VERSION ""

NS_ :

BS_:

BU_:

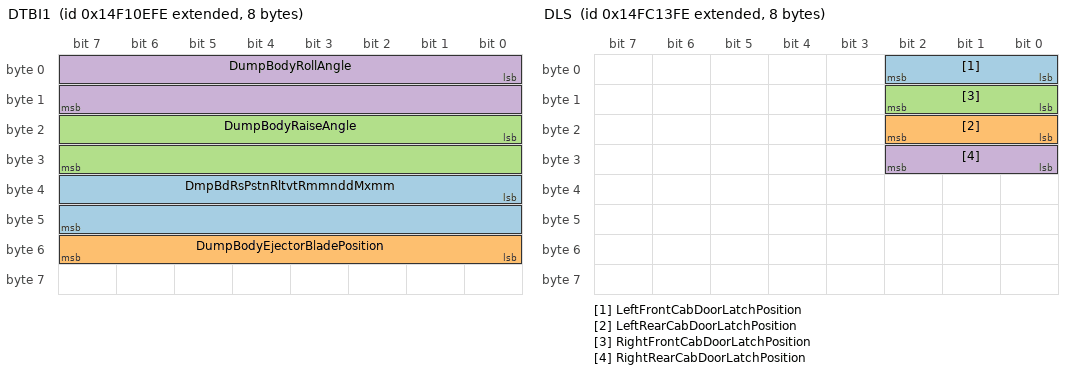
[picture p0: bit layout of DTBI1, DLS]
BO_ 2498825982 DTBI1: 8 Vector__XXX
 SG_ DmpBdRsPstnRltvtRmmnddMxmm : 32|16@1+ (0.005,-150) [-150|171.275] "%" Vector__XXX
 SG_ DumpBodyEjectorBladePosition : 48|8@1+ (0.4,0) [0|100] "%" Vector__XXX
 SG_ DumpBodyRaiseAngle : 16|16@1+ (0.0078125,-200) [-200|301.99] "deg" Vector__XXX
 SG_ DumpBodyRollAngle : 0|16@1+ (0.0078125,-200) [-200|301.99] "deg" Vector__XXX

BO_ 2499547902 CDC1: 8 Vector__XXX
 SG_ CabDoorsLockActuationCommand : 0|3@1+ (1,0) [0|7] "" Vector__XXX
 SG_ LeftFrontWindowPositionCommand : 16|3@1+ (1,0) [0|7] "" Vector__XXX
 SG_ LeftRearWindowPositionCommand : 24|3@1+ (1,0) [0|7] "" Vector__XXX
 SG_ MirrorLeft1HeatCommand : 48|2@1+ (1,0) [0|3] "" Vector__XXX
 SG_ MirrorLeft1HorizontalCommand : 32|2@1+ (1,0) [0|3] "" Vector__XXX
 SG_ MirrorLeft1VerticalCommand : 34|2@1+ (1,0) [0|3] "" Vector__XXX
 SG_ MirrorLeft2HeatCommand : 52|2@1+ (1,0) [0|3] "" Vector__XXX
 SG_ MirrorLeft2HorizontalCommand : 40|2@1+ (1,0) [0|3] "" Vector__XXX
 SG_ MirrorLeft2VerticalCommand : 42|2@1+ (1,0) [0|3] "" Vector__XXX
 SG_ MirrorRight1HeatCommand : 50|2@1+ (1,0) [0|3] "" Vector__XXX
 SG_ MirrorRight1HorizontalCommand : 36|2@1+ (1,0) [0|3] "" Vector__XXX
 SG_ MirrorRight1VerticalCommand : 38|2@1+ (1,0) [0|3] "" Vector__XXX
 SG_ MirrorRight2HeatCommand : 54|2@1+ (1,0) [0|3] "" Vector__XXX
 SG_ MirrorRight2HorizontalCommand : 44|2@1+ (1,0) [0|3] "" Vector__XXX
 SG_ MirrorRight2VerticalCommand : 46|2@1+ (1,0) [0|3] "" Vector__XXX
 SG_ RemoteCabDoorLockRequest : 8|3@1+ (1,0) [0|7] "" Vector__XXX
 SG_ RightFrontWindowPositionCommand : 19|3@1+ (1,0) [0|7] "" Vector__XXX
 SG_ RightRearWindowPositionCommand : 27|3@1+ (1,0) [0|7] "" Vector__XXX
 SG_ MirrorFoldingSwitch : 22|2@1+ (1,0) [0|3] "" Vector__XXX
 SG_ MirrorAutoPanningEnable : 30|2@1+ (1,0) [0|3] "" Vector__XXX

BO_ 2499548158 DLS: 8 Vector__XXX
 SG_ LeftFrontCabDoorLatchPosition : 0|3@1+ (1,0) [0|7] "" Vector__XXX
 SG_ LeftRearCabDoorLatchPosition : 16|3@1+ (1,0) [0|7] "" Vector__XXX
 SG_ RightFrontCabDoorLatchPosition : 8|3@1+ (1,0) [0|7] "" Vector__XXX
 SG_ RightRearCabDoorLatchPosition : 24|3@1+ (1,0) [0|7] "" Vector__XXX

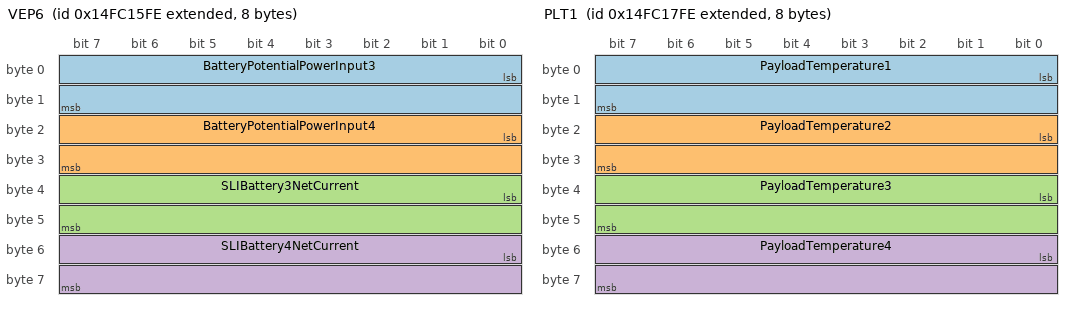
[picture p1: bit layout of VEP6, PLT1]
BO_ 2499548670 VEP6: 8 Vector__XXX
 SG_ BatteryPotentialPowerInput3 : 0|16@1+ (0.05,0) [0|3212.75] "V" Vector__XXX
 SG_ BatteryPotentialPowerInput4 : 16|16@1+ (0.05,0) [0|3212.75] "V" Vector__XXX
 SG_ SLIBattery3NetCurrent : 32|16@1+ (0.05,-1600) [-1600|1612.75] "A" Vector__XXX
 SG_ SLIBattery4NetCurrent : 48|16@1+ (0.05,-1600) [-1600|1612.75] "A" Vector__XXX

BO_ 2499548926 PLT2: 8 Vector__XXX
 SG_ PayloadTemperature5 : 0|16@1+ (0.03125,-273) [-273|1734.96875] "degC" Vector__XXX

BO_ 2499549182 PLT1: 8 Vector__XXX
 SG_ PayloadTemperature1 : 0|16@1+ (0.03125,-273) [-273|1734.96875] "degC" Vector__XXX
 SG_ PayloadTemperature2 : 16|16@1+ (0.03125,-273) [-273|1734.96875] "degC" Vector__XXX
 SG_ PayloadTemperature3 : 32|16@1+ (0.03125,-273) [-273|1734.96875] "degC" Vector__XXX
 SG_ PayloadTemperature4 : 48|16@1+ (0.03125,-273) [-273|1734.96875] "degC" Vector__XXX

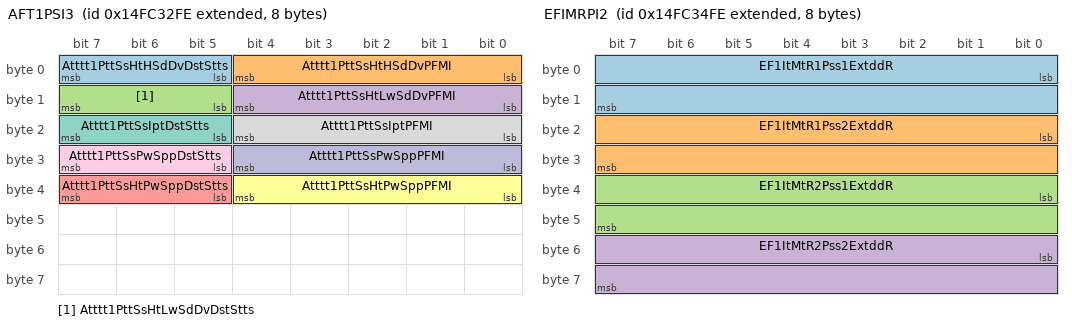
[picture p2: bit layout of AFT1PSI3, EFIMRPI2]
BO_ 2499556094 AFT1PSI3: 8 Vector__XXX
 SG_ Atttt1PttSsHtHSdDvDstStts : 5|3@1+ (1,0) [0|7] "" Vector__XXX
 SG_ Atttt1PttSsHtHSdDvPFMI : 0|5@1+ (1,0) [0|31] "" Vector__XXX
 SG_ Atttt1PttSsHtLwSdDvDstStts : 13|3@1+ (1,0) [0|7] "" Vector__XXX
 SG_ Atttt1PttSsHtLwSdDvPFMI : 8|5@1+ (1,0) [0|31] "" Vector__XXX
 SG_ Atttt1PttSsHtPwSppDstStts : 37|3@1+ (1,0) [0|7] "" Vector__XXX
 SG_ Atttt1PttSsHtPwSppPFMI : 32|5@1+ (1,0) [0|31] "" Vector__XXX
 SG_ Atttt1PttSsIptDstStts : 21|3@1+ (1,0) [0|7] "" Vector__XXX
 SG_ Atttt1PttSsIptPFMI : 16|5@1+ (1,0) [0|31] "" Vector__XXX
 SG_ Atttt1PttSsPwSppDstStts : 29|3@1+ (1,0) [0|7] "" Vector__XXX
 SG_ Atttt1PttSsPwSppPFMI : 24|5@1+ (1,0) [0|31] "" Vector__XXX

BO_ 2499556350 EFIMRPI3: 8 Vector__XXX
 SG_ EngnFl1InjtrMtrngRl1DsrdPrssr : 0|16@1+ (5,0) [0|321275] "kPa" Vector__XXX
 SG_ EngnFl1InjtrMtrngRl2DsrdPrssr : 16|16@1+ (5,0) [0|321275] "kPa" Vector__XXX

BO_ 2499556606 EFIMRPI2: 8 Vector__XXX
 SG_ EF1ItMtR1Pss1ExtddR : 0|16@1+ (5,0) [0|321275] "kPa" Vector__XXX
 SG_ EF1ItMtR1Pss2ExtddR : 16|16@1+ (5,0) [0|321275] "kPa" Vector__XXX
 SG_ EF1ItMtR2Pss1ExtddR : 32|16@1+ (5,0) [0|321275] "kPa" Vector__XXX
 SG_ EF1ItMtR2Pss2ExtddR : 48|16@1+ (5,0) [0|321275] "kPa" Vector__XXX

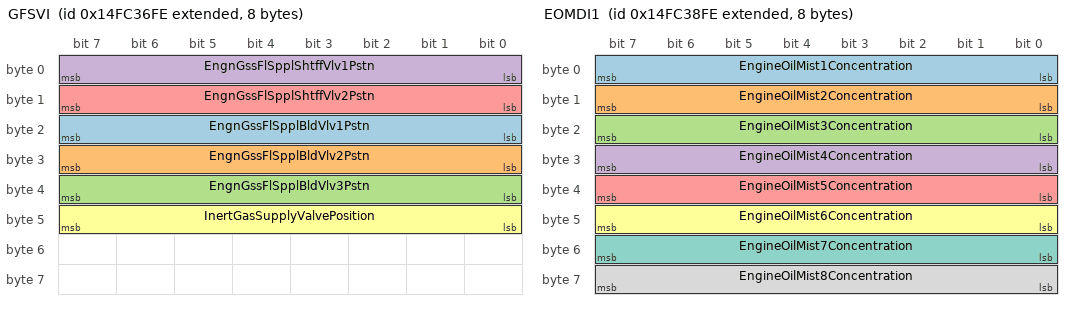
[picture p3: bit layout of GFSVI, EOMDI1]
BO_ 2499557118 GFSVI: 8 Vector__XXX
 SG_ EngnGssFlSpplBldVlv1Pstn : 16|8@1+ (0.4,0) [0|100] "%" Vector__XXX
 SG_ EngnGssFlSpplBldVlv2Pstn : 24|8@1+ (0.4,0) [0|100] "%" Vector__XXX
 SG_ EngnGssFlSpplBldVlv3Pstn : 32|8@1+ (0.4,0) [0|100] "%" Vector__XXX
 SG_ EngnGssFlSpplShtffVlv1Pstn : 0|8@1+ (0.4,0) [0|100] "%" Vector__XXX
 SG_ EngnGssFlSpplShtffVlv2Pstn : 8|8@1+ (0.4,0) [0|100] "%" Vector__XXX
 SG_ InertGasSupplyValvePosition : 40|8@1+ (0.4,0) [0|100] "%" Vector__XXX

BO_ 2499557374 EOMDI2: 8 Vector__XXX
 SG_ EngineOilMist10Concentration : 8|8@1+ (1,0) [0|250] "%" Vector__XXX
 SG_ EngineOilMist9Concentration : 0|8@1+ (1,0) [0|250] "%" Vector__XXX

BO_ 2499557630 EOMDI1: 8 Vector__XXX
 SG_ EngineOilMist1Concentration : 0|8@1+ (1,0) [0|250] "%" Vector__XXX
 SG_ EngineOilMist2Concentration : 8|8@1+ (1,0) [0|250] "%" Vector__XXX
 SG_ EngineOilMist3Concentration : 16|8@1+ (1,0) [0|250] "%" Vector__XXX
 SG_ EngineOilMist4Concentration : 24|8@1+ (1,0) [0|250] "%" Vector__XXX
 SG_ EngineOilMist5Concentration : 32|8@1+ (1,0) [0|250] "%" Vector__XXX
 SG_ EngineOilMist6Concentration : 40|8@1+ (1,0) [0|250] "%" Vector__XXX
 SG_ EngineOilMist7Concentration : 48|8@1+ (1,0) [0|250] "%" Vector__XXX
 SG_ EngineOilMist8Concentration : 56|8@1+ (1,0) [0|250] "%" Vector__XXX

BO_ 2499557886 GFSP2: 8 Vector__XXX
 SG_ PlntGssFlSpplOtltPrssr : 0|16@1+ (0.5,0) [0|32127.5] "kPa" Vector__XXX
 SG_ PlntInrtGsSpplOtltPrssr : 16|16@1+ (0.5,0) [0|32127.5] "kPa" Vector__XXX

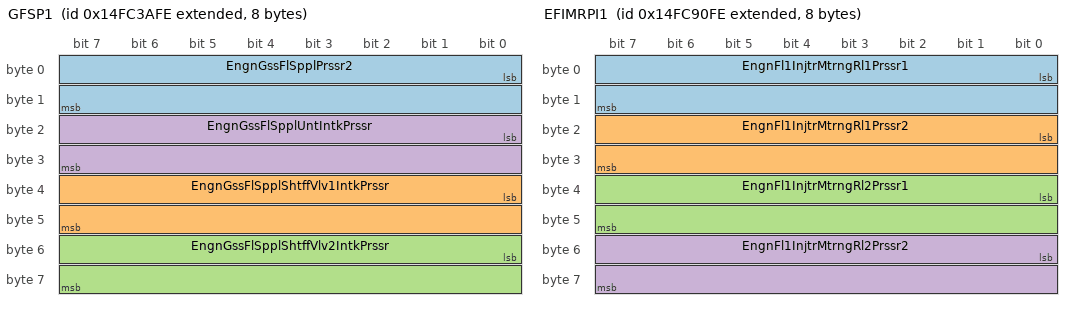
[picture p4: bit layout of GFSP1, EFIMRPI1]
BO_ 2499558142 GFSP1: 8 Vector__XXX
 SG_ EngnGssFlSpplPrssr2 : 0|16@1+ (0.5,0) [0|32127.5] "kPa" Vector__XXX
 SG_ EngnGssFlSpplShtffVlv1IntkPrssr : 32|16@1+ (0.5,0) [0|32127.5] "kPa" Vector__XXX
 SG_ EngnGssFlSpplShtffVlv2IntkPrssr : 48|16@1+ (0.5,0) [0|32127.5] "kPa" Vector__XXX
 SG_ EngnGssFlSpplUntIntkPrssr : 16|16@1+ (0.5,0) [0|32127.5] "kPa" Vector__XXX

BO_ 2499580158 EFIMRPI1: 8 Vector__XXX
 SG_ EngnFl1InjtrMtrngRl1Prssr1 : 0|16@1+ (0.00390625,0) [0|250.996] "MPa" Vector__XXX
 SG_ EngnFl1InjtrMtrngRl1Prssr2 : 16|16@1+ (0.00390625,0) [0|250.996] "MPa" Vector__XXX
 SG_ EngnFl1InjtrMtrngRl2Prssr1 : 32|16@1+ (0.00390625,0) [0|250.996] "MPa" Vector__XXX
 SG_ EngnFl1InjtrMtrngRl2Prssr2 : 48|16@1+ (0.00390625,0) [0|250.996] "MPa" Vector__XXX

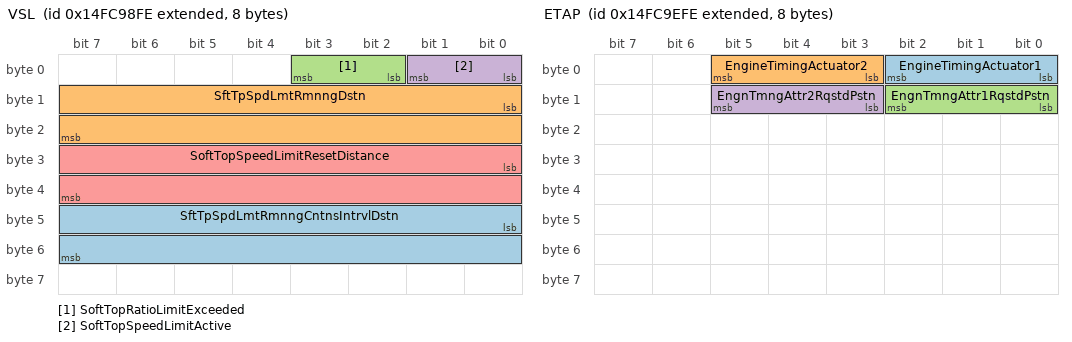
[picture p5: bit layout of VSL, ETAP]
BO_ 2499582206 VSL: 8 Vector__XXX
 SG_ SftTpSpdLmtRmnngCntnsIntrvlDstn : 40|16@1+ (1,0) [0|64255] "km" Vector__XXX
 SG_ SftTpSpdLmtRmnngDstn : 8|16@1+ (1,0) [0|64255] "km" Vector__XXX
 SG_ SoftTopRatioLimitExceeded : 2|2@1+ (1,0) [0|3] "" Vector__XXX
 SG_ SoftTopSpeedLimitActive : 0|2@1+ (1,0) [0|3] "" Vector__XXX
 SG_ SoftTopSpeedLimitResetDistance : 24|16@1+ (1,0) [0|64255] "km" Vector__XXX

BO_ 2499583486 ETAPC: 8 Vector__XXX
 SG_ EngnTmngAttr1PstnCmmnd : 0|3@1+ (1,0) [0|7] "" Vector__XXX
 SG_ EngnTmngAttr2PstnCmmnd : 3|3@1+ (1,0) [0|7] "" Vector__XXX

BO_ 2499583742 ETAP: 8 Vector__XXX
 SG_ EngineTimingActuator1 : 0|3@1+ (1,0) [0|7] "" Vector__XXX
 SG_ EngineTimingActuator2 : 3|3@1+ (1,0) [0|7] "" Vector__XXX
 SG_ EngnTmngAttr1RqstdPstn : 8|3@1+ (1,0) [0|7] "" Vector__XXX
 SG_ EngnTmngAttr2RqstdPstn : 11|3@1+ (1,0) [0|7] "" Vector__XXX

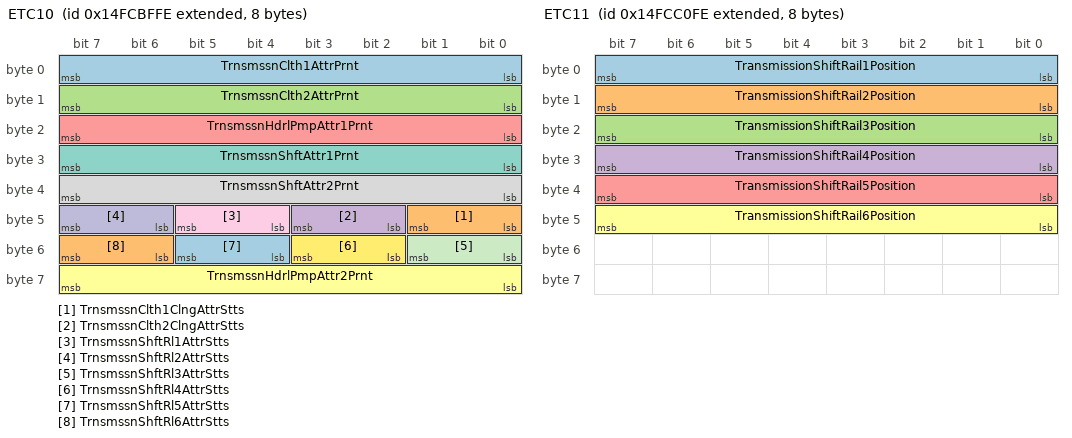
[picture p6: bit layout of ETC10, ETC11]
BO_ 2499592190 ETC10: 8 Vector__XXX
 SG_ TrnsmssnClth1AttrPrnt : 0|8@1+ (0.4,0) [0|100] "%" Vector__XXX
 SG_ TrnsmssnClth1ClngAttrStts : 40|2@1+ (1,0) [0|3] "" Vector__XXX
 SG_ TrnsmssnClth2AttrPrnt : 8|8@1+ (0.4,0) [0|100] "%" Vector__XXX
 SG_ TrnsmssnClth2ClngAttrStts : 42|2@1+ (1,0) [0|3] "" Vector__XXX
 SG_ TrnsmssnHdrlPmpAttr1Prnt : 16|8@1+ (0.4,0) [0|100] "%" Vector__XXX
 SG_ TrnsmssnHdrlPmpAttr2Prnt : 56|8@1+ (0.4,0) [0|100] "%" Vector__XXX
 SG_ TrnsmssnShftAttr1Prnt : 24|8@1+ (0.4,0) [0|100] "%" Vector__XXX
 SG_ TrnsmssnShftAttr2Prnt : 32|8@1+ (0.4,0) [0|100] "%" Vector__XXX
 SG_ TrnsmssnShftRl1AttrStts : 44|2@1+ (1,0) [0|3] "" Vector__XXX
 SG_ TrnsmssnShftRl2AttrStts : 46|2@1+ (1,0) [0|3] "" Vector__XXX
 SG_ TrnsmssnShftRl3AttrStts : 48|2@1+ (1,0) [0|3] "" Vector__XXX
 SG_ TrnsmssnShftRl4AttrStts : 50|2@1+ (1,0) [0|3] "" Vector__XXX
 SG_ TrnsmssnShftRl5AttrStts : 52|2@1+ (1,0) [0|3] "" Vector__XXX
 SG_ TrnsmssnShftRl6AttrStts : 54|2@1+ (1,0) [0|3] "" Vector__XXX

BO_ 2499592446 ETC11: 8 Vector__XXX
 SG_ TransmissionShiftRail1Position : 0|8@1+ (0.4,0) [0|100] "%" Vector__XXX
 SG_ TransmissionShiftRail2Position : 8|8@1+ (0.4,0) [0|100] "%" Vector__XXX
 SG_ TransmissionShiftRail3Position : 16|8@1+ (0.4,0) [0|100] "%" Vector__XXX
 SG_ TransmissionShiftRail4Position : 24|8@1+ (0.4,0) [0|100] "%" Vector__XXX
 SG_ TransmissionShiftRail5Position : 32|8@1+ (0.4,0) [0|100] "%" Vector__XXX
 SG_ TransmissionShiftRail6Position : 40|8@1+ (0.4,0) [0|100] "%" Vector__XXX

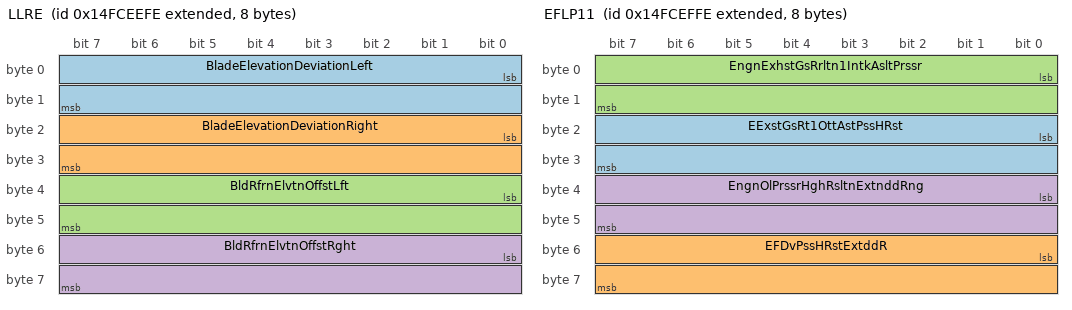
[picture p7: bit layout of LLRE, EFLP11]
BO_ 2499604222 LLRE: 8 Vector__XXX
 SG_ BladeElevationDeviationLeft : 0|16@1+ (1,-32000) [-32000|32255] "mm" Vector__XXX
 SG_ BladeElevationDeviationRight : 16|16@1+ (1,-32000) [-32000|32255] "mm" Vector__XXX
 SG_ BldRfrnElvtnOffstLft : 32|16@1+ (1,-32000) [-32000|32255] "mm" Vector__XXX
 SG_ BldRfrnElvtnOffstRght : 48|16@1+ (1,-32000) [-32000|32255] "mm" Vector__XXX

BO_ 2499604478 EFLP11: 8 Vector__XXX
 SG_ EExstGsRt1OttAstPssHRst : 16|16@1+ (0.1,0) [0|6425.5] "kPa" Vector__XXX
 SG_ EFDvPssHRstExtddR : 48|16@1+ (0.1,0) [0|6425.5] "kPa" Vector__XXX
 SG_ EngnExhstGsRrltn1IntkAsltPrssr : 0|16@1+ (0.1,0) [0|6425.5] "kPa" Vector__XXX
 SG_ EngnOlPrssrHghRsltnExtnddRng : 32|16@1+ (0.1,0) [0|6425.5] "kPa" Vector__XXX

BO_ 2499607550 EMAP: 8 Vector__XXX
 SG_ EExstMdB1FwBVvAttPst : 0|16@1+ (0.0025,0) [0|160.6375] "%" Vector__XXX
 SG_ EExstMdB2FwBVvAttPst : 16|16@1+ (0.0025,0) [0|160.6375] "%" Vector__XXX

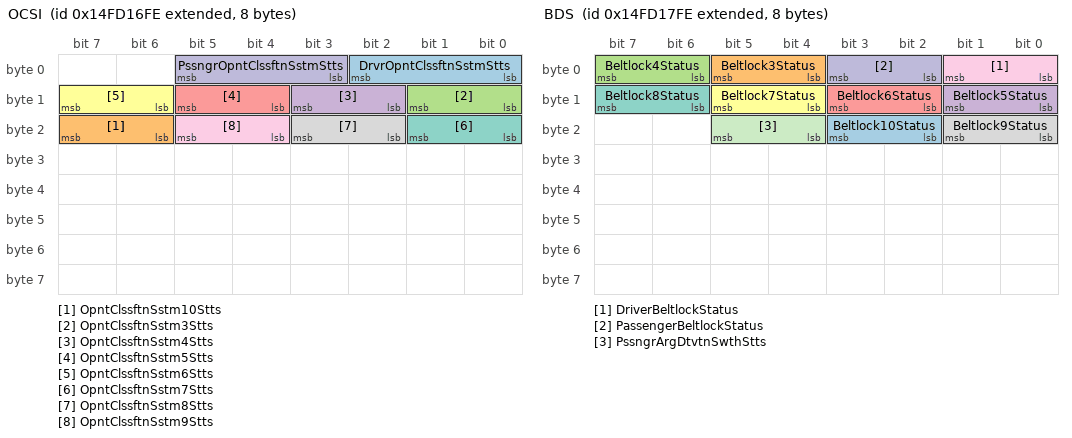
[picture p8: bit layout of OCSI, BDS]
BO_ 2499614462 OCSI: 8 Vector__XXX
 SG_ DrvrOpntClssftnSstmStts : 0|3@1+ (1,0) [0|7] "" Vector__XXX
 SG_ OpntClssftnSstm10Stts : 22|2@1+ (1,0) [0|3] "" Vector__XXX
 SG_ OpntClssftnSstm3Stts : 8|2@1+ (1,0) [0|3] "" Vector__XXX
 SG_ OpntClssftnSstm4Stts : 10|2@1+ (1,0) [0|3] "" Vector__XXX
 SG_ OpntClssftnSstm5Stts : 12|2@1+ (1,0) [0|3] "" Vector__XXX
 SG_ OpntClssftnSstm6Stts : 14|2@1+ (1,0) [0|3] "" Vector__XXX
 SG_ OpntClssftnSstm7Stts : 16|2@1+ (1,0) [0|3] "" Vector__XXX
 SG_ OpntClssftnSstm8Stts : 18|2@1+ (1,0) [0|3] "" Vector__XXX
 SG_ OpntClssftnSstm9Stts : 20|2@1+ (1,0) [0|3] "" Vector__XXX
 SG_ PssngrOpntClssftnSstmStts : 3|3@1+ (1,0) [0|7] "" Vector__XXX

BO_ 2499614718 BDS: 8 Vector__XXX
 SG_ Beltlock10Status : 18|2@1+ (1,0) [0|3] "" Vector__XXX
 SG_ Beltlock3Status : 4|2@1+ (1,0) [0|3] "" Vector__XXX
 SG_ Beltlock4Status : 6|2@1+ (1,0) [0|3] "" Vector__XXX
 SG_ Beltlock5Status : 8|2@1+ (1,0) [0|3] "" Vector__XXX
 SG_ Beltlock6Status : 10|2@1+ (1,0) [0|3] "" Vector__XXX
 SG_ Beltlock7Status : 12|2@1+ (1,0) [0|3] "" Vector__XXX
 SG_ Beltlock8Status : 14|2@1+ (1,0) [0|3] "" Vector__XXX
 SG_ Beltlock9Status : 16|2@1+ (1,0) [0|3] "" Vector__XXX
 SG_ DriverBeltlockStatus : 0|2@1+ (1,0) [0|3] "" Vector__XXX
 SG_ PassengerBeltlockStatus : 2|2@1+ (1,0) [0|3] "" Vector__XXX
 SG_ PssngrArgDtvtnSwthStts : 20|2@1+ (1,0) [0|3] "" Vector__XXX

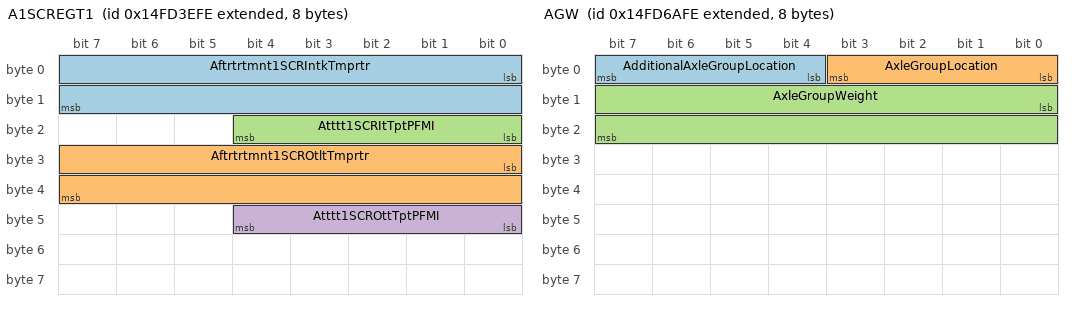
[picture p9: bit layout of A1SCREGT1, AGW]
BO_ 2499624702 A1SCREGT1: 8 Vector__XXX
 SG_ Aftrtrtmnt1SCRIntkTmprtr : 0|16@1+ (0.03125,-273) [-273|1734.96875] "degC" Vector__XXX
 SG_ Aftrtrtmnt1SCROtltTmprtr : 24|16@1+ (0.03125,-273) [-273|1734.96875] "degC" Vector__XXX
 SG_ Atttt1SCRItTptPFMI : 16|5@1+ (1,0) [0|31] "" Vector__XXX
 SG_ Atttt1SCROttTptPFMI : 40|5@1+ (1,0) [0|31] "" Vector__XXX

BO_ 2499630078 EAI: 8 Vector__XXX
 SG_ EngineExhaustTemperatureAverage : 0|16@1+ (0.03125,-273) [-273|1734.96875] "degC" Vector__XXX
 SG_ EngnExhstBnk1TmprtrAvrg : 16|16@1+ (0.03125,-273) [-273|1734.96875] "degC" Vector__XXX
 SG_ EngnExhstBnk2TmprtrAvrg : 32|16@1+ (0.03125,-273) [-273|1734.96875] "degC" Vector__XXX

BO_ 2499635454 GCVW: 8 Vector__XXX
 SG_ GrossCombinationWeight : 0|24@1+ (2,0) [0|32899070] "kg" Vector__XXX
 SG_ NetVehicleWeightChange : 24|24@1+ (2,-16449535) [-16449535|16449535] "kg" Vector__XXX

BO_ 2499635966 AGW: 8 Vector__XXX
 SG_ AdditionalAxleGroupLocation : 4|4@1+ (1,0) [0|15] "" Vector__XXX
 SG_ AxleGroupLocation : 0|4@1+ (1,0) [0|15] "" Vector__XXX
 SG_ AxleGroupWeight : 8|16@1+ (2,0) [0|128510] "kg" Vector__XXX

BO_ 2499641854 EGRBV: 8 Vector__XXX
 SG_ EExstGsRt1CBpssAttPst : 0|8@1+ (0.4,0) [0|100] "%" Vector__XXX

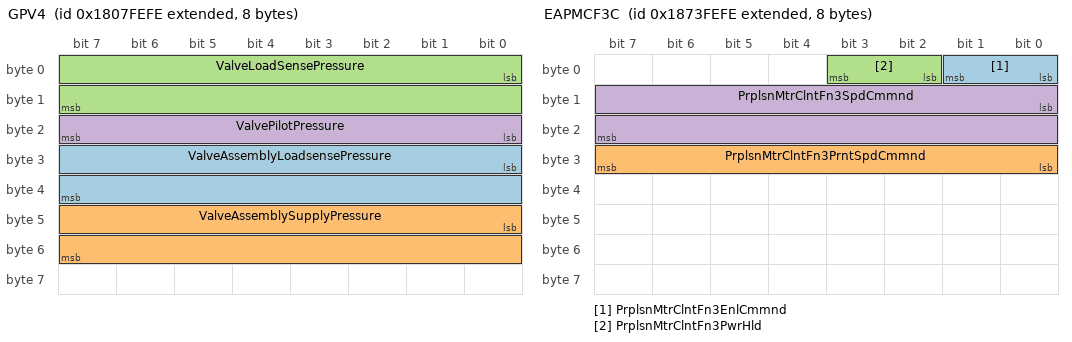
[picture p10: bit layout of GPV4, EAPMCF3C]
BO_ 2550660862 GPV4: 8 Vector__XXX
 SG_ ValveAssemblyLoadsensePressure : 24|16@1+ (5,0) [0|321275] "kPa" Vector__XXX
 SG_ ValveAssemblySupplyPressure : 40|16@1+ (5,0) [0|321275] "kPa" Vector__XXX
 SG_ ValveLoadSensePressure : 0|16@1+ (5,0) [0|321275] "kPa" Vector__XXX
 SG_ ValvePilotPressure : 16|8@1+ (16,0) [0|4000] "kPa" Vector__XXX

BO_ 2550988542 EEC16: 8 Vector__XXX
 SG_ EngineClutchEngageRequestStatus : 10|2@1+ (1,0) [0|3] "" Vector__XXX
 SG_ ReadyForClutchEngagementStatus : 8|2@1+ (1,0) [0|3] "" Vector__XXX
 SG_ AcceleratorPedal3Position : 0|8@1+ (0.4,0) [0|100] "%" Vector__XXX

BO_ 2557214462 WSPSCC: 8 Vector__XXX
 SG_ WSttPpDsPssCtStPtCd : 8|4@1+ (1,0) [0|15] "" Vector__XXX
 SG_ WSttPpStPssCtStPtCd : 0|4@1+ (1,0) [0|15] "" Vector__XXX

BO_ 2557345534 WSPT1: 19 Vector__XXX
 SG_ WllStmltnPmpPlngrFrngOrdr : 144|4@1+ (1,0) [0|15] "" Vector__XXX
 SG_ WllStmltnPmpRdLdHghThrshld : 128|16@1+ (5,0) [0|321275] "kN" Vector__XXX
 SG_ WllStmltnPmpStnPrssrHghThrshld : 64|16@1+ (0.1,-3212.7) [-3212.7|3212.8] "kPa" Vector__XXX
 SG_ WllStmltnPmpStnPrssrLwThrshld : 48|16@1+ (0.1,-3212.7) [-3212.7|3212.8] "kPa" Vector__XXX
 SG_ WSttPpCstSpdHTsd : 112|16@1+ (0.125,0) [0|8031.875] "rpm" Vector__XXX
 SG_ WSttPpCstSpdLwTsd : 96|16@1+ (0.125,0) [0|8031.875] "rpm" Vector__XXX
 SG_ WSttPpDsPssHTsd : 80|16@1+ (5,0) [0|321275] "kPa" Vector__XXX
 SG_ WSttPpGBxOPssHTsd : 16|16@1+ (0.1,0) [0|6425.5] "kPa" Vector__XXX
 SG_ WSttPpGBxOPssLwTsd : 0|16@1+ (0.1,0) [0|6425.5] "kPa" Vector__XXX
 SG_ WSttPpGBxOTptHTsd : 40|8@1+ (1,-40) [-40|210] "degC" Vector__XXX
 SG_ WSttPpGBxOTptLwTsd : 32|8@1+ (1,-40) [-40|210] "degC" Vector__XXX

BO_ 2557673214 ODMCC: 37 Vector__XXX
 SG_ OlDrsMntrCnfgrtnIdntftnNmr : 0|8@1+ (1,0) [0|250] "count" Vector__XXX
 SG_ OlDrsMntrFrrsBn1CntCmmnd : 8|24@1+ (1,0) [0|16449535] "count" Vector__XXX
 SG_ OlDrsMntrFrrsBn2CntCmmnd : 32|24@1+ (1,0) [0|16449535] "count" Vector__XXX
 SG_ OlDrsMntrFrrsBn3CntCmmnd : 56|24@1+ (1,0) [0|16449535] "count" Vector__XXX
 SG_ OlDrsMntrFrrsBn4CntCmmnd : 80|24@1+ (1,0) [0|16449535] "count" Vector__XXX
 SG_ OlDrsMntrFrrsBn5CntCmmnd : 104|24@1+ (1,0) [0|16449535] "count" Vector__XXX
 SG_ OlDrsMntrFrrsBn6CntCmmnd : 128|24@1+ (1,0) [0|16449535] "count" Vector__XXX
 SG_ OlDrsMntrNnFrrsBn1CntCmmnd : 152|24@1+ (1,0) [0|16449535] "count" Vector__XXX
 SG_ OlDrsMntrNnFrrsBn2CntCmmnd : 176|24@1+ (1,0) [0|16449535] "count" Vector__XXX
 SG_ OlDrsMntrNnFrrsBn3CntCmmnd : 200|24@1+ (1,0) [0|16449535] "count" Vector__XXX
 SG_ OlDrsMntrNnFrrsBn4CntCmmnd : 224|24@1+ (1,0) [0|16449535] "count" Vector__XXX
 SG_ OlDrsMntrNnFrrsBn5CntCmmnd : 248|24@1+ (1,0) [0|16449535] "count" Vector__XXX
 SG_ OlDrsMntrNnFrrsBn6CntCmmnd : 272|24@1+ (1,0) [0|16449535] "count" Vector__XXX

BO_ 2557738750 EAPMCF3C: 8 Vector__XXX
 SG_ PrplsnMtrClntFn3EnlCmmnd : 0|2@1+ (1,0) [0|3] "" Vector__XXX
 SG_ PrplsnMtrClntFn3PrntSpdCmmnd : 24|8@1+ (0.5,0) [0|125] "%" Vector__XXX
 SG_ PrplsnMtrClntFn3PwrHld : 2|2@1+ (1,0) [0|3] "" Vector__XXX
 SG_ PrplsnMtrClntFn3SpdCmmnd : 8|16@1+ (0.5,0) [0|32127.5] "rpm" Vector__XXX

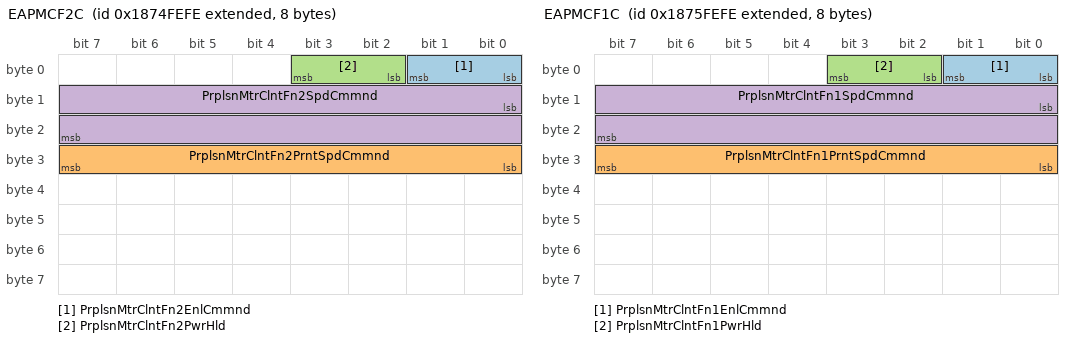
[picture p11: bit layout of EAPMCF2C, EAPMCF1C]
BO_ 2557804286 EAPMCF2C: 8 Vector__XXX
 SG_ PrplsnMtrClntFn2EnlCmmnd : 0|2@1+ (1,0) [0|3] "" Vector__XXX
 SG_ PrplsnMtrClntFn2PrntSpdCmmnd : 24|8@1+ (0.5,0) [0|125] "%" Vector__XXX
 SG_ PrplsnMtrClntFn2PwrHld : 2|2@1+ (1,0) [0|3] "" Vector__XXX
 SG_ PrplsnMtrClntFn2SpdCmmnd : 8|16@1+ (0.5,0) [0|32127.5] "rpm" Vector__XXX

BO_ 2557869822 EAPMCF1C: 8 Vector__XXX
 SG_ PrplsnMtrClntFn1EnlCmmnd : 0|2@1+ (1,0) [0|3] "" Vector__XXX
 SG_ PrplsnMtrClntFn1PrntSpdCmmnd : 24|8@1+ (0.5,0) [0|125] "%" Vector__XXX
 SG_ PrplsnMtrClntFn1PwrHld : 2|2@1+ (1,0) [0|3] "" Vector__XXX
 SG_ PrplsnMtrClntFn1SpdCmmnd : 8|16@1+ (0.5,0) [0|32127.5] "rpm" Vector__XXX

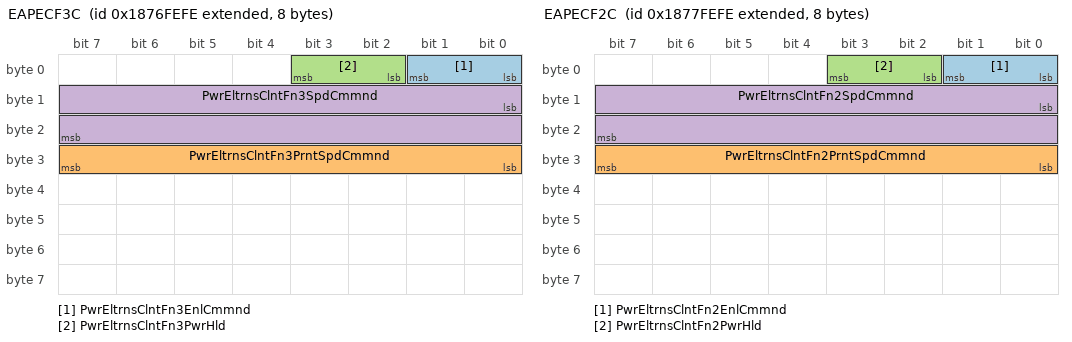
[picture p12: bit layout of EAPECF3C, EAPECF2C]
BO_ 2557935358 EAPECF3C: 8 Vector__XXX
 SG_ PwrEltrnsClntFn3EnlCmmnd : 0|2@1+ (1,0) [0|3] "" Vector__XXX
 SG_ PwrEltrnsClntFn3PrntSpdCmmnd : 24|8@1+ (0.5,0) [0|125] "%" Vector__XXX
 SG_ PwrEltrnsClntFn3PwrHld : 2|2@1+ (1,0) [0|3] "" Vector__XXX
 SG_ PwrEltrnsClntFn3SpdCmmnd : 8|16@1+ (0.5,0) [0|32127.5] "rpm" Vector__XXX

BO_ 2558000894 EAPECF2C: 8 Vector__XXX
 SG_ PwrEltrnsClntFn2EnlCmmnd : 0|2@1+ (1,0) [0|3] "" Vector__XXX
 SG_ PwrEltrnsClntFn2PrntSpdCmmnd : 24|8@1+ (0.5,0) [0|125] "%" Vector__XXX
 SG_ PwrEltrnsClntFn2PwrHld : 2|2@1+ (1,0) [0|3] "" Vector__XXX
 SG_ PwrEltrnsClntFn2SpdCmmnd : 8|16@1+ (0.5,0) [0|32127.5] "rpm" Vector__XXX

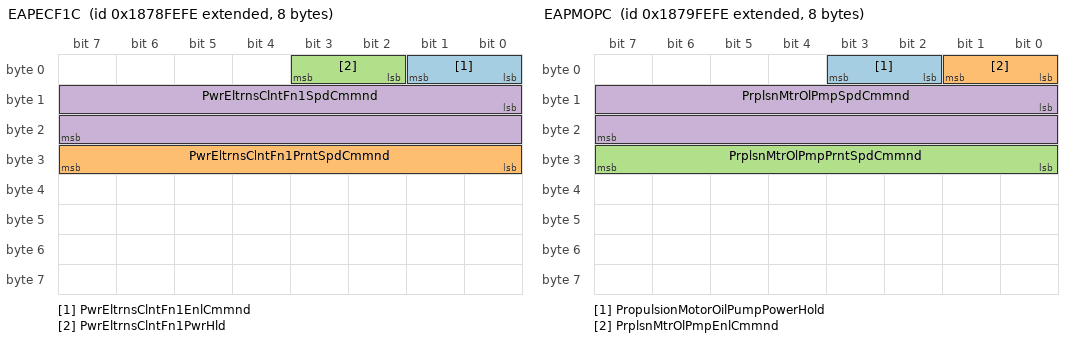
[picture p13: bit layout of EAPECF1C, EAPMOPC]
BO_ 2558066430 EAPECF1C: 8 Vector__XXX
 SG_ PwrEltrnsClntFn1EnlCmmnd : 0|2@1+ (1,0) [0|3] "" Vector__XXX
 SG_ PwrEltrnsClntFn1PrntSpdCmmnd : 24|8@1+ (0.5,0) [0|125] "%" Vector__XXX
 SG_ PwrEltrnsClntFn1PwrHld : 2|2@1+ (1,0) [0|3] "" Vector__XXX
 SG_ PwrEltrnsClntFn1SpdCmmnd : 8|16@1+ (0.5,0) [0|32127.5] "rpm" Vector__XXX

BO_ 2558131966 EAPMOPC: 8 Vector__XXX
 SG_ PropulsionMotorOilPumpPowerHold : 2|2@1+ (1,0) [0|3] "" Vector__XXX
 SG_ PrplsnMtrOlPmpEnlCmmnd : 0|2@1+ (1,0) [0|3] "" Vector__XXX
 SG_ PrplsnMtrOlPmpPrntSpdCmmnd : 24|8@1+ (0.5,0) [0|125] "%" Vector__XXX
 SG_ PrplsnMtrOlPmpSpdCmmnd : 8|16@1+ (0.5,0) [0|32127.5] "rpm" Vector__XXX

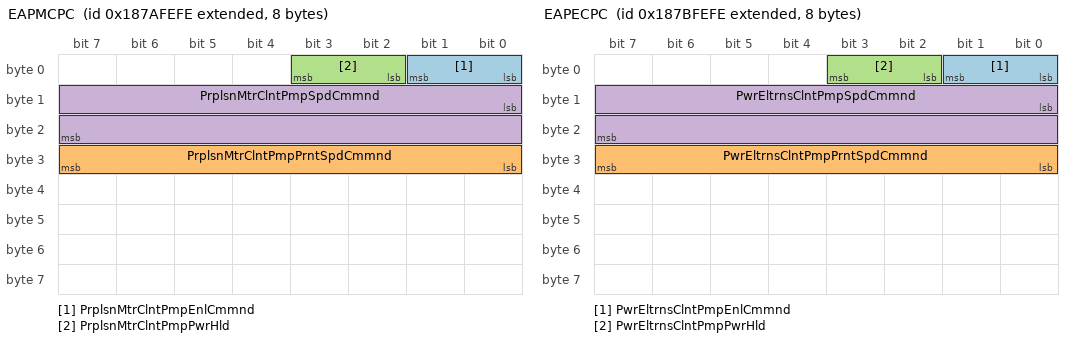
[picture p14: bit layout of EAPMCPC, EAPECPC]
BO_ 2558197502 EAPMCPC: 8 Vector__XXX
 SG_ PrplsnMtrClntPmpEnlCmmnd : 0|2@1+ (1,0) [0|3] "" Vector__XXX
 SG_ PrplsnMtrClntPmpPrntSpdCmmnd : 24|8@1+ (0.5,0) [0|125] "%" Vector__XXX
 SG_ PrplsnMtrClntPmpPwrHld : 2|2@1+ (1,0) [0|3] "" Vector__XXX
 SG_ PrplsnMtrClntPmpSpdCmmnd : 8|16@1+ (0.5,0) [0|32127.5] "rpm" Vector__XXX

BO_ 2558263038 EAPECPC: 8 Vector__XXX
 SG_ PwrEltrnsClntPmpEnlCmmnd : 0|2@1+ (1,0) [0|3] "" Vector__XXX
 SG_ PwrEltrnsClntPmpPrntSpdCmmnd : 24|8@1+ (0.5,0) [0|125] "%" Vector__XXX
 SG_ PwrEltrnsClntPmpPwrHld : 2|2@1+ (1,0) [0|3] "" Vector__XXX
 SG_ PwrEltrnsClntPmpSpdCmmnd : 8|16@1+ (0.5,0) [0|32127.5] "rpm" Vector__XXX

BO_ 2558394110 EAMC: 8 Vector__XXX
 SG_ EltrfdAssrMtrEnlCmmnd : 0|2@1+ (1,0) [0|3] "" Vector__XXX
 SG_ EltrfdAssrMtrPrntSpdCmmnd : 24|8@1+ (0.5,0) [0|125] "%" Vector__XXX
 SG_ EltrfdAssrMtrPwrHld : 2|2@1+ (1,0) [0|3] "" Vector__XXX
 SG_ EltrfdAssrMtrSpdCmmnd : 8|16@1+ (0.5,0) [0|32127.5] "rpm" Vector__XXX
 SG_ ElectrifiedAccessoryMotor1 : 32|1@1+ (1,0) [0|1] "" Vector__XXX
 SG_ ElectrifiedAccessoryMotor2 : 33|1@1+ (1,0) [0|1] "" Vector__XXX
 SG_ ElectrifiedAccessoryMotor3 : 34|1@1+ (1,0) [0|1] "" Vector__XXX
 SG_ ElectrifiedAccessoryMotor4 : 35|1@1+ (1,0) [0|1] "" Vector__XXX
 SG_ ElectrifiedAccessoryMotor5 : 36|1@1+ (1,0) [0|1] "" Vector__XXX
 SG_ ElectrifiedAccessoryMotor6 : 37|1@1+ (1,0) [0|1] "" Vector__XXX
 SG_ ElectrifiedAccessoryMotor7 : 38|1@1+ (1,0) [0|1] "" Vector__XXX
 SG_ ElectrifiedAccessoryMotor8 : 39|1@1+ (1,0) [0|1] "" Vector__XXX
 SG_ ElectrifiedAccessoryMotor9 : 40|1@1+ (1,0) [0|1] "" Vector__XXX
 SG_ ElectrifiedAccessoryMotor10 : 41|1@1+ (1,0) [0|1] "" Vector__XXX
 SG_ ElectrifiedAccessoryMotor11 : 42|1@1+ (1,0) [0|1] "" Vector__XXX
 SG_ ElectrifiedAccessoryMotor12 : 43|1@1+ (1,0) [0|1] "" Vector__XXX
 SG_ ElectrifiedAccessoryMotor13 : 44|1@1+ (1,0) [0|1] "" Vector__XXX
 SG_ ElectrifiedAccessoryMotor14 : 45|1@1+ (1,0) [0|1] "" Vector__XXX
 SG_ ElectrifiedAccessoryMotor15 : 46|1@1+ (1,0) [0|1] "" Vector__XXX

BO_ 2558459646 ESRRBR: 8 Vector__XXX
 SG_ RqstdEngnSpdAlrtnRtLmt : 0|16@1+ (1,0) [0|64255] "rpm/s" Vector__XXX
 SG_ RqstdEngnSpdDlrtnRtLmt : 16|16@1+ (1,0) [0|64255] "rpm/s" Vector__XXX

BO_ 2558525182 TSIC: 200 Vector__XXX
 SG_ NumberofTireSensors : 0|8@1+ (1,0) [0|250] "count" Vector__XXX
 SG_ TireLocation : 16|8@1+ (8,0) [0|0] "bit-mapped" Vector__XXX
 SG_ TireNumber : 8|8@1+ (1,0) [0|250] "count" Vector__XXX
 SG_ TireSensorIdentificationNumber : 24|8@1+ (1,0) [0|255] "ASCII" Vector__XXX

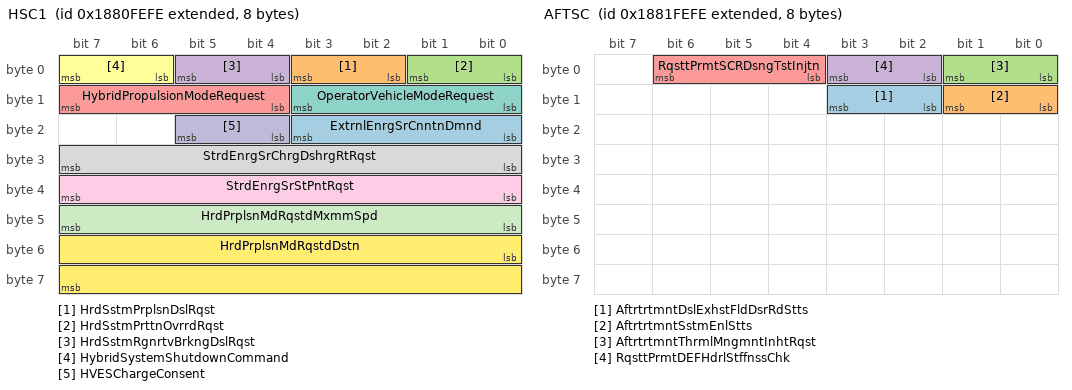
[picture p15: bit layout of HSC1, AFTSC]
BO_ 2558590718 HSC1: 8 Vector__XXX
 SG_ ExtrnlEnrgSrCnntnDmnd : 16|4@1+ (1,0) [0|15] "" Vector__XXX
 SG_ HrdSstmPrplsnDslRqst : 2|2@1+ (1,0) [0|3] "" Vector__XXX
 SG_ HrdSstmPrttnOvrrdRqst : 0|2@1+ (1,0) [0|3] "" Vector__XXX
 SG_ HrdSstmRgnrtvBrkngDslRqst : 4|2@1+ (1,0) [0|3] "" Vector__XXX
 SG_ HybridPropulsionModeRequest : 12|4@1+ (1,0) [0|15] "" Vector__XXX
 SG_ HybridSystemShutdownCommand : 6|2@1+ (1,0) [0|3] "" Vector__XXX
 SG_ OperatorVehicleModeRequest : 8|4@1+ (1,0) [0|15] "" Vector__XXX
 SG_ StrdEnrgSrChrgDshrgRtRqst : 24|8@1+ (0.4,0) [0|100] "%" Vector__XXX
 SG_ StrdEnrgSrStPntRqst : 32|8@1+ (0.4,0) [0|100] "%" Vector__XXX
 SG_ HVESChargeConsent : 20|2@1+ (1,0) [0|3] "" Vector__XXX
 SG_ HrdPrplsnMdRqstdMxmmSpd : 40|8@1+ (1,0) [0|250] "km/h" Vector__XXX
 SG_ HrdPrplsnMdRqstdDstn : 48|16@1+ (0.03125,0) [0|2007.96875] "km" Vector__XXX

BO_ 2558656254 AFTSC: 8 Vector__XXX
 SG_ AftrtrtmntDslExhstFldDsrRdStts : 10|2@1+ (1,0) [0|3] "" Vector__XXX
 SG_ AftrtrtmntSstmEnlStts : 8|2@1+ (1,0) [0|3] "" Vector__XXX
 SG_ AftrtrtmntThrmlMngmntInhtRqst : 0|2@1+ (1,0) [0|3] "" Vector__XXX
 SG_ RqsttPrmtDEFHdrlStffnssChk : 2|2@1+ (1,0) [0|3] "" Vector__XXX
 SG_ RqsttPrmtSCRDsngTstInjtn : 4|3@1+ (1,0) [0|7] "" Vector__XXX

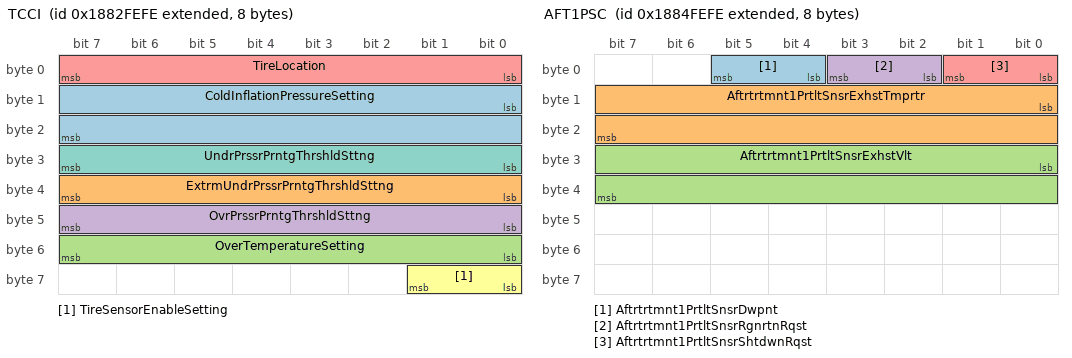
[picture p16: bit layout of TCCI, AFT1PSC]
BO_ 2558721790 TCCI: 8 Vector__XXX
 SG_ ColdInflationPressureSetting : 8|16@1+ (1,0) [0|64255] "kPa" Vector__XXX
 SG_ ExtrmUndrPrssrPrntgThrshldSttng : 32|8@1+ (0.5,0) [0|125] "%" Vector__XXX
 SG_ OverTemperatureSetting : 48|8@1+ (1,-40) [-40|210] "degC" Vector__XXX
 SG_ OvrPrssrPrntgThrshldSttng : 40|8@1+ (0.5,0) [0|125] "%" Vector__XXX
 SG_ TireLocation : 0|8@1+ (8,0) [0|0] "bit-mapped" Vector__XXX
 SG_ TireSensorEnableSetting : 56|2@1+ (1,0) [0|3] "" Vector__XXX
 SG_ UndrPrssrPrntgThrshldSttng : 24|8@1+ (0.5,0) [0|125] "%" Vector__XXX

BO_ 2558787326 PCIC: 8 Vector__XXX
 SG_ PayloadCorrectionFactorCommand : 24|8@1+ (1,-125) [-125|125] "%" Vector__XXX
 SG_ PldClrtnCmmnddWght : 8|16@1+ (2,0) [0|128510] "kg" Vector__XXX
 SG_ PldClrtnStPntCmmnd : 0|4@1+ (1,0) [0|15] "" Vector__XXX

BO_ 2558852862 AFT1PSC: 8 Vector__XXX
 SG_ Aftrtrtmnt1PrtltSnsrDwpnt : 4|2@1+ (1,0) [0|3] "" Vector__XXX
 SG_ Aftrtrtmnt1PrtltSnsrExhstTmprtr : 8|16@1+ (0.03125,-273) [-273|1734.96875] "degC" Vector__XXX
 SG_ Aftrtrtmnt1PrtltSnsrExhstVlt : 24|16@1+ (0.00390625,0) [0|250.996] "km/h" Vector__XXX
 SG_ Aftrtrtmnt1PrtltSnsrRgnrtnRqst : 2|2@1+ (1,0) [0|3] "" Vector__XXX
 SG_ Aftrtrtmnt1PrtltSnsrShtdwnRqst : 0|2@1+ (1,0) [0|3] "" Vector__XXX

BO_ 2558918398 CM2: 8 Vector__XXX
 SG_ ActiveShiftConsoleRequest : 52|2@1+ (1,0) [0|3] "" Vector__XXX
 SG_ AftrtrtmntSstmEnlCmmnd : 50|2@1+ (1,0) [0|3] "" Vector__XXX
 SG_ AttttRtESpdAwdSwt : 30|2@1+ (1,0) [0|3] "" Vector__XXX
 SG_ ElvtdEngnSpdAllwdSwth : 28|2@1+ (1,0) [0|3] "" Vector__XXX
 SG_ EngineFan2RequestedPercentSpeed : 0|8@1+ (0.4,0) [0|100] "%" Vector__XXX
 SG_ EngineStopStartDisableCommand : 26|2@1+ (1,0) [0|3] "" Vector__XXX
 SG_ EngnIdlMngmntPndngEvntOvrrd : 54|2@1+ (1,0) [0|3] "" Vector__XXX
 SG_ HtExhngrDrsPrgFrSwth : 20|2@1+ (1,0) [0|3] "" Vector__XXX
 SG_ HtExhngrDrsPrgInhtSwth : 18|2@1+ (1,0) [0|3] "" Vector__XXX
 SG_ PerformanceBiasSelection : 8|8@1+ (0.4,0) [0|100] "%" Vector__XXX
 SG_ PrdtvCrsCntrlDtvtnRqst : 24|2@1+ (1,0) [0|3] "" Vector__XXX
 SG_ PrdtvCrsCntrlEnlSwth : 22|2@1+ (1,0) [0|3] "" Vector__XXX
 SG_ PrdtvCrsCntrlMxmmNgtvOffst : 40|8@1+ (0.125,-31.25) [-31.25|0] "km/h" Vector__XXX
 SG_ PrdtvCrsCntrlMxmmPstvOffst : 32|8@1+ (0.125,0) [0|31.25] "km/h" Vector__XXX
 SG_ SCROprtrIndmntOvrrdSwth : 16|2@1+ (1,0) [0|3] "" Vector__XXX
 SG_ TrnsmssnAtNtrlMnlRtrnEnlSwth : 48|2@1+ (1,0) [0|3] "" Vector__XXX
 SG_ VehicleHoodSwitch : 56|2@1+ (1,0) [0|3] "" Vector__XXX

BO_ 2558983934 SPOC: 8 Vector__XXX
 SG_ SwitchedPowerOutput10Command : 20|2@1+ (1,0) [0|3] "" Vector__XXX
 SG_ SwitchedPowerOutput11Command : 18|2@1+ (1,0) [0|3] "" Vector__XXX
 SG_ SwitchedPowerOutput12Command : 16|2@1+ (1,0) [0|3] "" Vector__XXX
 SG_ SwitchedPowerOutput13Command : 30|2@1+ (1,0) [0|3] "" Vector__XXX
 SG_ SwitchedPowerOutput14Command : 28|2@1+ (1,0) [0|3] "" Vector__XXX
 SG_ SwitchedPowerOutput15Command : 26|2@1+ (1,0) [0|3] "" Vector__XXX
 SG_ SwitchedPowerOutput16Command : 24|2@1+ (1,0) [0|3] "" Vector__XXX
 SG_ SwitchedPowerOutput17Command : 38|2@1+ (1,0) [0|3] "" Vector__XXX
 SG_ SwitchedPowerOutput18Command : 36|2@1+ (1,0) [0|3] "" Vector__XXX
 SG_ SwitchedPowerOutput19Command : 34|2@1+ (1,0) [0|3] "" Vector__XXX
 SG_ SwitchedPowerOutput1Command : 6|2@1+ (1,0) [0|3] "" Vector__XXX
 SG_ SwitchedPowerOutput20Command : 32|2@1+ (1,0) [0|3] "" Vector__XXX
 SG_ SwitchedPowerOutput21Command : 46|2@1+ (1,0) [0|3] "" Vector__XXX
 SG_ SwitchedPowerOutput22Command : 44|2@1+ (1,0) [0|3] "" Vector__XXX
 SG_ SwitchedPowerOutput23Command : 42|2@1+ (1,0) [0|3] "" Vector__XXX
 SG_ SwitchedPowerOutput24Command : 40|2@1+ (1,0) [0|3] "" Vector__XXX
 SG_ SwitchedPowerOutput25Command : 54|2@1+ (1,0) [0|3] "" Vector__XXX
 SG_ SwitchedPowerOutput26Command : 52|2@1+ (1,0) [0|3] "" Vector__XXX
 SG_ SwitchedPowerOutput27Command : 50|2@1+ (1,0) [0|3] "" Vector__XXX
 SG_ SwitchedPowerOutput28Command : 48|2@1+ (1,0) [0|3] "" Vector__XXX
 SG_ SwitchedPowerOutput29Command : 62|2@1+ (1,0) [0|3] "" Vector__XXX
 SG_ SwitchedPowerOutput2Command : 4|2@1+ (1,0) [0|3] "" Vector__XXX
 SG_ SwitchedPowerOutput30Command : 60|2@1+ (1,0) [0|3] "" Vector__XXX
 SG_ SwitchedPowerOutput31Command : 58|2@1+ (1,0) [0|3] "" Vector__XXX
 SG_ SwitchedPowerOutput32Command : 56|2@1+ (1,0) [0|3] "" Vector__XXX
 SG_ SwitchedPowerOutput3Command : 2|2@1+ (1,0) [0|3] "" Vector__XXX
 SG_ SwitchedPowerOutput4Command : 0|2@1+ (1,0) [0|3] "" Vector__XXX
 SG_ SwitchedPowerOutput5Command : 14|2@1+ (1,0) [0|3] "" Vector__XXX
 SG_ SwitchedPowerOutput6Command : 12|2@1+ (1,0) [0|3] "" Vector__XXX
 SG_ SwitchedPowerOutput7Command : 10|2@1+ (1,0) [0|3] "" Vector__XXX
 SG_ SwitchedPowerOutput8Command : 8|2@1+ (1,0) [0|3] "" Vector__XXX
 SG_ SwitchedPowerOutput9Command : 22|2@1+ (1,0) [0|3] "" Vector__XXX

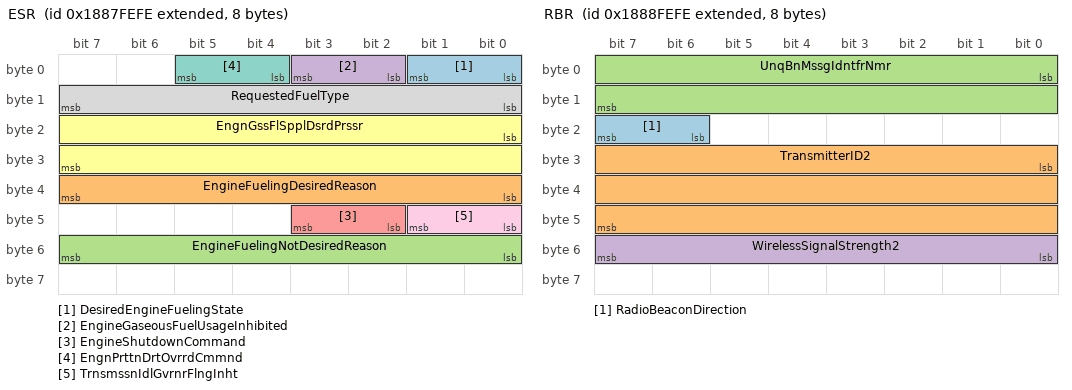
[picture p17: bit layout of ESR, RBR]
BO_ 2559049470 ESR: 8 Vector__XXX
 SG_ DesiredEngineFuelingState : 0|2@1+ (1,0) [0|3] "" Vector__XXX
 SG_ EngineFuelingDesiredReason : 32|8@1+ (1,0) [0|255] "" Vector__XXX
 SG_ EngineFuelingNotDesiredReason : 48|8@1+ (1,0) [0|255] "" Vector__XXX
 SG_ EngineGaseousFuelUsageInhibited : 2|2@1+ (1,0) [0|3] "" Vector__XXX
 SG_ EngineShutdownCommand : 42|2@1+ (1,0) [0|3] "" Vector__XXX
 SG_ EngnGssFlSpplDsrdPrssr : 16|16@1+ (0.5,0) [0|32127.5] "kPa" Vector__XXX
 SG_ EngnPrttnDrtOvrrdCmmnd : 4|2@1+ (1,0) [0|3] "" Vector__XXX
 SG_ RequestedFuelType : 8|8@1+ (1,0) [0|255] "" Vector__XXX
 SG_ TrnsmssnIdlGvrnrFlngInht : 40|2@1+ (1,0) [0|3] "" Vector__XXX

BO_ 2559115006 RBR: 8 Vector__XXX
 SG_ RadioBeaconDirection : 22|2@1+ (1,0) [0|3] "" Vector__XXX
 SG_ TransmitterID2 : 24|24@1+ (1,0) [0|16449635] "ID" Vector__XXX
 SG_ UnqBnMssgIdntfrNmr : 0|16@1+ (1,0) [0|64255] "count" Vector__XXX
 SG_ WirelessSignalStrength2 : 48|8@1+ (0.5,-125) [-125|0] "dBm" Vector__XXX

BO_ 2559573758 ECC: 8 Vector__XXX
 SG_ CtLvEPttStdwOvdCd : 0|2@1+ (1,0) [0|3] "" Vector__XXX

BO_ 2559639294 SFC: 8 Vector__XXX
 SG_ SupplementalFanDirectionCommand : 2|2@1+ (1,0) [0|3] "" Vector__XXX
 SG_ SupplementalFanEnableCommand : 0|2@1+ (1,0) [0|3] "" Vector__XXX
 SG_ SupplementalFanPowerHold : 24|2@1+ (1,0) [0|3] "" Vector__XXX
 SG_ SupplementalFanSpeedCommand : 8|16@1+ (0.5,0) [0|32127.5] "rpm" Vector__XXX

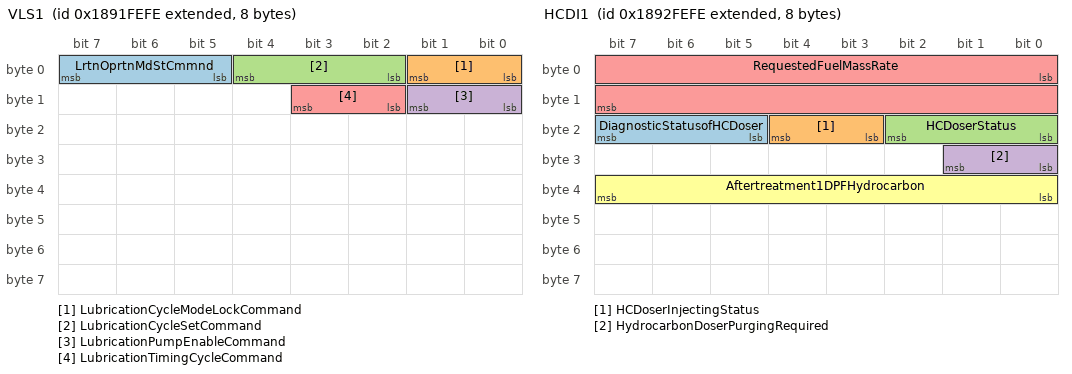
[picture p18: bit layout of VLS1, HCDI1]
BO_ 2559704830 VLS1: 8 Vector__XXX
 SG_ LrtnOprtnMdStCmmnd : 5|3@1+ (1,0) [0|7] "" Vector__XXX
 SG_ LubricationCycleModeLockCommand : 0|2@1+ (1,0) [0|3] "" Vector__XXX
 SG_ LubricationCycleSetCommand : 2|3@1+ (1,0) [0|7] "" Vector__XXX
 SG_ LubricationPumpEnableCommand : 8|2@1+ (1,0) [0|3] "" Vector__XXX
 SG_ LubricationTimingCycleCommand : 10|2@1+ (1,0) [0|3] "" Vector__XXX

BO_ 2559770366 HCDI1: 8 Vector__XXX
 SG_ DiagnosticStatusofHCDoser : 21|3@1+ (1,0) [0|7] "" Vector__XXX
 SG_ HCDoserInjectingStatus : 19|2@1+ (1,0) [0|3] "" Vector__XXX
 SG_ HCDoserStatus : 16|3@1+ (1,0) [0|7] "" Vector__XXX
 SG_ HydrocarbonDoserPurgingRequired : 24|2@1+ (1,0) [0|3] "" Vector__XXX
 SG_ RequestedFuelMassRate : 0|16@1+ (0.05,0) [0|3212.75] "g/min" Vector__XXX
 SG_ Aftertreatment1DPFHydrocarbon : 32|8@1+ (0.5,0) [0|125] "%" Vector__XXX

BO_ 2559901438 AT1DPFSSC: 8 Vector__XXX
 SG_ Atttt1DsPttFtStMCtOst : 0|16@1+ (0.0025,0) [0|160.6375] "%" Vector__XXX
 SG_ Atttt1DsPttFtStStddDvtCtOst : 16|16@1+ (0.0025,0) [0|160.6375] "%" Vector__XXX

BO_ 2559966974 AT2DPFSSC: 8 Vector__XXX
 SG_ Atttt2DsPttFtStMCtOst : 0|16@1+ (0.0025,0) [0|160.6375] "%" Vector__XXX
 SG_ Atttt2DsPttFtStStddDvtCtOst : 16|16@1+ (0.0025,0) [0|160.6375] "%" Vector__XXX

BO_ 2560032510 LVDSOM: 8 Vector__XXX
 SG_ LwVltgDsnntDsrdOprtngMd : 0|4@1+ (1,0) [0|15] "" Vector__XXX

BO_ 2560098046 NCS: 8 Vector__XXX
 SG_ CabNoiseControlStatus : 0|2@1+ (1,0) [0|3] "" Vector__XXX
 SG_ CabNoiseControlTuningStatus : 2|4@1+ (1,0) [0|15] "" Vector__XXX

BO_ 2560163582 NC1: 8 Vector__XXX
 SG_ CabNoiseControlCommand : 0|2@1+ (1,0) [0|3] "" Vector__XXX
 SG_ CabNoiseControlTuningCommand : 2|3@1+ (1,0) [0|7] "" Vector__XXX

BO_ 2560360190 PMI: 8 Vector__XXX
 SG_ DataDictionaryManufacturerCode : 0|11@1+ (1,0) [0|2047] "" Vector__XXX
 SG_ DataDictionaryMethod : 11|21@1+ (1,0) [0|2097151] "" Vector__XXX

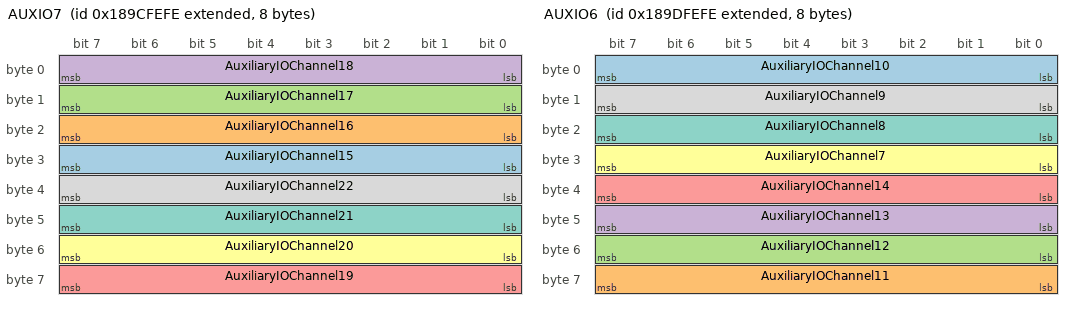
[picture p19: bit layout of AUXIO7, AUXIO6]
BO_ 2560425726 AUXIO7: 8 Vector__XXX
 SG_ AuxiliaryIOChannel15 : 24|8@1+ (1,0) [0|250] "count" Vector__XXX
 SG_ AuxiliaryIOChannel16 : 16|8@1+ (1,0) [0|250] "count" Vector__XXX
 SG_ AuxiliaryIOChannel17 : 8|8@1+ (1,0) [0|250] "count" Vector__XXX
 SG_ AuxiliaryIOChannel18 : 0|8@1+ (1,0) [0|250] "count" Vector__XXX
 SG_ AuxiliaryIOChannel19 : 56|8@1+ (1,0) [0|250] "count" Vector__XXX
 SG_ AuxiliaryIOChannel20 : 48|8@1+ (1,0) [0|250] "count" Vector__XXX
 SG_ AuxiliaryIOChannel21 : 40|8@1+ (1,0) [0|250] "count" Vector__XXX
 SG_ AuxiliaryIOChannel22 : 32|8@1+ (1,0) [0|250] "count" Vector__XXX

BO_ 2560491262 AUXIO6: 8 Vector__XXX
 SG_ AuxiliaryIOChannel10 : 0|8@1+ (1,0) [0|250] "count" Vector__XXX
 SG_ AuxiliaryIOChannel11 : 56|8@1+ (1,0) [0|250] "count" Vector__XXX
 SG_ AuxiliaryIOChannel12 : 48|8@1+ (1,0) [0|250] "count" Vector__XXX
 SG_ AuxiliaryIOChannel13 : 40|8@1+ (1,0) [0|250] "count" Vector__XXX
 SG_ AuxiliaryIOChannel14 : 32|8@1+ (1,0) [0|250] "count" Vector__XXX
 SG_ AuxiliaryIOChannel7 : 24|8@1+ (1,0) [0|250] "count" Vector__XXX
 SG_ AuxiliaryIOChannel8 : 16|8@1+ (1,0) [0|250] "count" Vector__XXX
 SG_ AuxiliaryIOChannel9 : 8|8@1+ (1,0) [0|250] "count" Vector__XXX

BO_ 2561015550 AUXIO4: 8 Vector__XXX
 SG_ AuxiliaryIO100 : 32|2@1+ (1,0) [0|3] "" Vector__XXX
 SG_ AuxiliaryIO101 : 46|2@1+ (1,0) [0|3] "" Vector__XXX
 SG_ AuxiliaryIO102 : 44|2@1+ (1,0) [0|3] "" Vector__XXX
 SG_ AuxiliaryIO103 : 42|2@1+ (1,0) [0|3] "" Vector__XXX
 SG_ AuxiliaryIO104 : 40|2@1+ (1,0) [0|3] "" Vector__XXX
 SG_ AuxiliaryIO105 : 54|2@1+ (1,0) [0|3] "" Vector__XXX
 SG_ AuxiliaryIO106 : 52|2@1+ (1,0) [0|3] "" Vector__XXX
 SG_ AuxiliaryIO107 : 50|2@1+ (1,0) [0|3] "" Vector__XXX
 SG_ AuxiliaryIO108 : 48|2@1+ (1,0) [0|3] "" Vector__XXX
 SG_ AuxiliaryIO109 : 62|2@1+ (1,0) [0|3] "" Vector__XXX
 SG_ AuxiliaryIO110 : 60|2@1+ (1,0) [0|3] "" Vector__XXX
 SG_ AuxiliaryIO111 : 58|2@1+ (1,0) [0|3] "" Vector__XXX
 SG_ AuxiliaryIO112 : 56|2@1+ (1,0) [0|3] "" Vector__XXX
 SG_ AuxiliaryIO81 : 6|2@1+ (1,0) [0|3] "" Vector__XXX
 SG_ AuxiliaryIO82 : 4|2@1+ (1,0) [0|3] "" Vector__XXX
 SG_ AuxiliaryIO83 : 2|2@1+ (1,0) [0|3] "" Vector__XXX
 SG_ AuxiliaryIO84 : 0|2@1+ (1,0) [0|3] "" Vector__XXX
 SG_ AuxiliaryIO85 : 14|2@1+ (1,0) [0|3] "" Vector__XXX
 SG_ AuxiliaryIO86 : 12|2@1+ (1,0) [0|3] "" Vector__XXX
 SG_ AuxiliaryIO87 : 10|2@1+ (1,0) [0|3] "" Vector__XXX
 SG_ AuxiliaryIO88 : 8|2@1+ (1,0) [0|3] "" Vector__XXX
 SG_ AuxiliaryIO89 : 22|2@1+ (1,0) [0|3] "" Vector__XXX
 SG_ AuxiliaryIO90 : 20|2@1+ (1,0) [0|3] "" Vector__XXX
 SG_ AuxiliaryIO91 : 18|2@1+ (1,0) [0|3] "" Vector__XXX
 SG_ AuxiliaryIO92 : 16|2@1+ (1,0) [0|3] "" Vector__XXX
 SG_ AuxiliaryIO93 : 30|2@1+ (1,0) [0|3] "" Vector__XXX
 SG_ AuxiliaryIO94 : 28|2@1+ (1,0) [0|3] "" Vector__XXX
 SG_ AuxiliaryIO95 : 26|2@1+ (1,0) [0|3] "" Vector__XXX
 SG_ AuxiliaryIO96 : 24|2@1+ (1,0) [0|3] "" Vector__XXX
 SG_ AuxiliaryIO97 : 38|2@1+ (1,0) [0|3] "" Vector__XXX
 SG_ AuxiliaryIO98 : 36|2@1+ (1,0) [0|3] "" Vector__XXX
 SG_ AuxiliaryIO99 : 34|2@1+ (1,0) [0|3] "" Vector__XXX

BO_ 2561081086 AUXIO3: 8 Vector__XXX
 SG_ AuxiliaryIO49 : 6|2@1+ (1,0) [0|3] "" Vector__XXX
 SG_ AuxiliaryIO50 : 4|2@1+ (1,0) [0|3] "" Vector__XXX
 SG_ AuxiliaryIO51 : 2|2@1+ (1,0) [0|3] "" Vector__XXX
 SG_ AuxiliaryIO52 : 0|2@1+ (1,0) [0|3] "" Vector__XXX
 SG_ AuxiliaryIO53 : 14|2@1+ (1,0) [0|3] "" Vector__XXX
 SG_ AuxiliaryIO54 : 12|2@1+ (1,0) [0|3] "" Vector__XXX
 SG_ AuxiliaryIO55 : 10|2@1+ (1,0) [0|3] "" Vector__XXX
 SG_ AuxiliaryIO56 : 8|2@1+ (1,0) [0|3] "" Vector__XXX
 SG_ AuxiliaryIO57 : 22|2@1+ (1,0) [0|3] "" Vector__XXX
 SG_ AuxiliaryIO58 : 20|2@1+ (1,0) [0|3] "" Vector__XXX
 SG_ AuxiliaryIO59 : 18|2@1+ (1,0) [0|3] "" Vector__XXX
 SG_ AuxiliaryIO60 : 16|2@1+ (1,0) [0|3] "" Vector__XXX
 SG_ AuxiliaryIO61 : 30|2@1+ (1,0) [0|3] "" Vector__XXX
 SG_ AuxiliaryIO62 : 28|2@1+ (1,0) [0|3] "" Vector__XXX
 SG_ AuxiliaryIO63 : 26|2@1+ (1,0) [0|3] "" Vector__XXX
 SG_ AuxiliaryIO64 : 24|2@1+ (1,0) [0|3] "" Vector__XXX
 SG_ AuxiliaryIO65 : 38|2@1+ (1,0) [0|3] "" Vector__XXX
 SG_ AuxiliaryIO66 : 36|2@1+ (1,0) [0|3] "" Vector__XXX
 SG_ AuxiliaryIO67 : 34|2@1+ (1,0) [0|3] "" Vector__XXX
 SG_ AuxiliaryIO68 : 32|2@1+ (1,0) [0|3] "" Vector__XXX
 SG_ AuxiliaryIO69 : 46|2@1+ (1,0) [0|3] "" Vector__XXX
 SG_ AuxiliaryIO70 : 44|2@1+ (1,0) [0|3] "" Vector__XXX
 SG_ AuxiliaryIO71 : 42|2@1+ (1,0) [0|3] "" Vector__XXX
 SG_ AuxiliaryIO72 : 40|2@1+ (1,0) [0|3] "" Vector__XXX
 SG_ AuxiliaryIO73 : 54|2@1+ (1,0) [0|3] "" Vector__XXX
 SG_ AuxiliaryIO74 : 52|2@1+ (1,0) [0|3] "" Vector__XXX
 SG_ AuxiliaryIO75 : 50|2@1+ (1,0) [0|3] "" Vector__XXX
 SG_ AuxiliaryIO76 : 48|2@1+ (1,0) [0|3] "" Vector__XXX
 SG_ AuxiliaryIO77 : 62|2@1+ (1,0) [0|3] "" Vector__XXX
 SG_ AuxiliaryIO78 : 60|2@1+ (1,0) [0|3] "" Vector__XXX
 SG_ AuxiliaryIO79 : 58|2@1+ (1,0) [0|3] "" Vector__XXX
 SG_ AuxiliaryIO80 : 56|2@1+ (1,0) [0|3] "" Vector__XXX

CM_ BO_ 2498825982 "Dump Truck Body Information";
CM_ SG_ 2498825982 DmpBdRsPstnRltvtRmmnddMxmm "Dump Body Raise Position Relative to Recommended Maximum: The angular position of the dump body expressed as a percentage of the maximum recommended body raised position. 100% represents the maximum default raised position of the dump body and is mea...";
CM_ SG_ 2498825982 DumpBodyEjectorBladePosition "Dump Body Ejector Blade Position: The dump body ejector blade is used to push material out of the dump body of a dump truck. 0% represents the fully retracted position and 100% represents the fully extended position.";
CM_ SG_ 2498825982 DumpBodyRaiseAngle "Dump Body Raise Angle: The angular position of the dump body referenced to the vehicle chassis. 0 degrees represents the body in its resting position.";
CM_ SG_ 2498825982 DumpBodyRollAngle "Dump Body Roll Angle: The angle between the dump body y-axis and the ground plane (i.e. rotation about the X-axis). The roll angle for a roll to the right is reported with a positive value. Roll angle is the same for both Z-Down and Z-Up axis systems...";
CM_ BO_ 2499547902 "Cab Door Control 1";
CM_ SG_ 2499547902 CabDoorsLockActuationCommand "Cab Doors Lock Actuation Command: Commands cab door latch state change: lock or unlock.000b = Unlock left front cab door latch (driver door on LH steer vehicles)001b = Unlock right front cab door latch (front passenger door for LH steer vehicles)010b...";
CM_ SG_ 2499547902 LeftFrontWindowPositionCommand "Left Front Window Position Command: Commands position change of left front window (driver door window on left-hand steer vehicles).000b = Window move up001b = Window move down010b = Window auto up011b = Window auto down100b = Reserved101b = Reserved1...";
CM_ SG_ 2499547902 LeftRearWindowPositionCommand "Left Rear Window Position Command: Commands position change of left rear window.000b = Window move up001b = Window move down010b = Window auto up011b = Window auto down100b = Reserved101b = Reserved110b = Reserved111b = Take no action...";
CM_ SG_ 2499547902 MirrorLeft1HeatCommand "Mirror Left 1 Heat Command: Command to activate heater for primary mirror on the left side (driver side for left-hand steer vehicle).  Mirror heat may be expected to latch in the on state upon receipt of the command, stay on while the command is take...";
CM_ SG_ 2499547902 MirrorLeft1HorizontalCommand "Mirror Left 1 Horizontal Command: Commands horizontal position change of the primary mirror on the left side (driver side for left-hand steer vehicles).00b = Move left01b = Move right10b = Reserved11b = Take no action";
CM_ SG_ 2499547902 MirrorLeft1VerticalCommand "Mirror Left 1 Vertical Command: Commands vertical position change of the primary mirror on the left side (driver side for left-hand steer vehicles).00b = Move up01b = Move down10b = Reserved11b = Take no action";
CM_ SG_ 2499547902 MirrorLeft2HeatCommand "Mirror Left 2 Heat Command: Command to activate heater for second mirror on the left side (driver side for left-hand steer vehicle).  Mirror heat may be expected to latch in the on state upon receipt of the command, stay on while the command is take ...";
CM_ SG_ 2499547902 MirrorLeft2HorizontalCommand "Mirror Left 2 Horizontal Command: Commands horizontal position change of the second mirror on the left side (driver side for left-hand steer vehicles).00b = Move left01b = Move right10b = Reserved11b = Take no action";
CM_ SG_ 2499547902 MirrorLeft2VerticalCommand "Mirror Left 2 Vertical Command: Commands vertical position change of the second mirror on the left side (driver side for left-hand steer vehicles). 00b = Move up01b = Move down10b = Reserved11b = Take no action";
CM_ SG_ 2499547902 MirrorRight1HeatCommand "Mirror Right 1 Heat Command: Command to activate heater for primary mirror on the right side (passenger side for left-hand steer vehicle).  Mirror heat may be expected to latch in the on state upon receipt of the command, stay on while the command is...";
CM_ SG_ 2499547902 MirrorRight1HorizontalCommand "Mirror Right 1 Horizontal Command: Commands horizontal position change of the primary mirror on the right side (passenger side for lefthand steer vehicles).00b = Move left01b = Move right10b = Reserved11b = Take no action";
CM_ SG_ 2499547902 MirrorRight1VerticalCommand "Mirror Right 1 Vertical Command: Commands vertical position change of the primary mirror on the right side (passenger side for lefthand steer vehicles).00b = Move up01b = Move down10b = Reserved11b = Take no action";
CM_ SG_ 2499547902 MirrorRight2HeatCommand "Mirror Right 2 Heat Command: Command to activate heater for second mirror on the right side (passenger side for left-hand steer vehicle).  Mirror heat may be expected to latch in the on state upon receipt of the command, stay on while the command is ...";
CM_ SG_ 2499547902 MirrorRight2HorizontalCommand "Mirror Right 2 Horizontal Command: Commands horizontal position change of the second mirror on the right side (passenger side for lefthand steer vehicles).00b = Move left01b = Move right10b = Reserved11b = Take no action";
CM_ SG_ 2499547902 MirrorRight2VerticalCommand "Mirror Right 2 Vertical Command: Commands vertical position change of the second mirror on the right side (passenger side for lefthand steer vehicles).00b = Move up01b = Move down10b = Reserved11b = Take no action";
CM_ SG_ 2499547902 RemoteCabDoorLockRequest "Remote Cab Door Lock Request: Request to the cab door lock controller from Remote Keyless Entry or or other external device to lock or unlock doors.This parameter is different from Cab Doors Lock Actuation Command (SPN 7727) because this is a request...";
CM_ SG_ 2499547902 RightFrontWindowPositionCommand "Right Front Window Position Command: Commands position change of right front window (passenger door window on left-hand steer vehicles).000b = Window move up001b = Window move down010b = Window auto up011b = Window auto down100b = Reserved101b = Rese...";
CM_ SG_ 2499547902 RightRearWindowPositionCommand "Right Rear Window Position Command: Commands position change of the right rear window.000b = Window move up001b = Window move down010b = Window auto up011b = Window auto down100b = Reserved101b = Reserved110b = Reserved111b = Take no action...";
CM_ SG_ 2499547902 MirrorFoldingSwitch "Mirror Folding Switch: Status of momentary switch used to toggle position of folding mirrors.00b = No Request01b = Request to toggle mirror position (fold/unfold)10b = Reserved11b = Take no action";
CM_ SG_ 2499547902 MirrorAutoPanningEnable "Mirror Auto Panning Enable: Command to enable/disable the auto panning (trailer tracking) function of the mirror or mirror replacement camera.00b = Disable panning01b = Enable panning10b = Reserved11b = Not available/Take no action";
CM_ BO_ 2499548158 "Door Latch Status";
CM_ SG_ 2499548158 LeftFrontCabDoorLatchPosition "Left Front Cab Door Latch Position: Status of the left front cab door latch (driver door for left-hand steer vehicles). Door latches may have 3 positions indicating fully open, 1st detent or ajar, and 2nd detent or fully closed.000b = Door Latch Open...";
CM_ SG_ 2499548158 LeftRearCabDoorLatchPosition "Left Rear Cab Door Latch Position: Status of the left rear cab door latch. Door latches may have 3 positions indicating fully open, 1st detent or ajar, and 2nd detent or fully closed.000b = Door Latch Open001b = Door Latch Fully Closed/Latched010b = ...";
CM_ SG_ 2499548158 RightFrontCabDoorLatchPosition "Right Front Cab Door Latch Position: Status of the right front cab door latch (passenger door for left-hand steer vehicles). Door latches may have 3 positions indicating fully open, 1st detent or ajar, and 2nd detent or fully closed.000b = Door Latch...";
CM_ SG_ 2499548158 RightRearCabDoorLatchPosition "Right Rear Cab Door Latch Position: Status of the right rear cab door latch. Door latches may have 3 positions indicating fully open, 1st detent or ajar, and 2nd detent or fully closed.000b = Door Latch Open001b = Door Latch Fully Closed/Latched010b ...";
CM_ BO_ 2499548670 "Vehicle Electrical Power 6";
CM_ SG_ 2499548670 BatteryPotentialPowerInput3 "Battery Potential / Power Input 3: This parameter measures the third source of battery potential as measured at the input of the ECU/actuator etc. coming from one or more batteries, irrespective of the distance between the component and the battery. ...";
CM_ SG_ 2499548670 BatteryPotentialPowerInput4 "Battery Potential / Power Input 4: This parameter measures the fourth source of battery potential as measured at the input of the ECU/actuator etc. coming from one or more batteries, irrespective of the distance between the component and the battery....";
CM_ SG_ 2499548670 SLIBattery3NetCurrent "SLI Battery 3 Net Current: Net flow of electrical current into/out of the third battery or third set of batteries used for starting the engine, for lighting, and for ignition (SLI).";
CM_ SG_ 2499548670 SLIBattery4NetCurrent "SLI Battery 4 Net Current: Net flow of electrical current into/out of the fourth battery or fourth set of batteries used for starting the engine, for lighting, and for ignition (SLI).";
CM_ BO_ 2499548926 "Payload Temperature 2";
CM_ SG_ 2499548926 PayloadTemperature5 "Payload Temperature 5: Temperature of payload at measurement point 5.Measurement position is manufacturer or regulation specific.";
CM_ BO_ 2499549182 "Payload Temperature 1";
CM_ SG_ 2499549182 PayloadTemperature1 "Payload Temperature 1: Temperature of payload at measurement point 1.Measurement position is manufacturer or regulation specific.";
CM_ SG_ 2499549182 PayloadTemperature2 "Payload Temperature 2: Temperature of payload at measurement point 2.Measurement position is manufacturer or regulation specific.";
CM_ SG_ 2499549182 PayloadTemperature3 "Payload Temperature 3: Temperature of payload at measurement point 3.Measurement position is manufacturer or regulation specific.";
CM_ SG_ 2499549182 PayloadTemperature4 "Payload Temperature 4: Temperature of payload at measurement point 4.Measurement position is manufacturer or regulation specific.";
CM_ BO_ 2499556094 "Aftertreatment 1 Particulate Sensor Information 3";
CM_ SG_ 2499556094 Atttt1PttSsHtHSdDvDstStts "Aftertreatment 1 Particulate Sensor Heater High Side Driver Diagnostic Status: The value of this parameter is not retained when power is removed from the particulate sensor.000b = Tests monitored continuously. There are no enable or pause conditions....";
CM_ SG_ 2499556094 Atttt1PttSsHtHSdDvPFMI "Aftertreatment 1 Particulate Sensor Heater High Side Driver Preliminary FMI: Used to identify the applicable J1939-73 FMI detected in the aftertreatment particulate sensor heater high side driver by the manufacturer’s sensor control software in exhau...";
CM_ SG_ 2499556094 Atttt1PttSsHtLwSdDvDstStts "Aftertreatment 1 Particulate Sensor Heater Low Side Driver Diagnostic Status: The value of this parameter is not retained when power is removed from the particulate sensor.000b = Tests monitored continuously. There are no enable or pause conditions. ...";
CM_ SG_ 2499556094 Atttt1PttSsHtLwSdDvPFMI "Aftertreatment 1 Particulate Sensor Heater Low Side Driver Preliminary FMI: Used to identify the applicable J1939-73 FMI detected in the aftertreatment particulate sensor heater high side driver by the manufacturer’s sensor control software in exhaus...";
CM_ SG_ 2499556094 Atttt1PttSsHtPwSppDstStts "Aftertreatment 1 Particulate Sensor Heater Power Supply Diagnostic Status: The value of this parameter is not retained when power is removed from the particulate sensor.000b = Tests monitored continuously. There are no enable or pause conditions. See...";
CM_ SG_ 2499556094 Atttt1PttSsHtPwSppPFMI "Aftertreatment 1 Particulate Sensor Heater Power Supply Preliminary FMI: Used to identify the applicable J1939-73 FMI detected in the aftertreatment particulate sensor heater power supply by the manufacturer’s sensor control software in exhaust bank ...";
CM_ SG_ 2499556094 Atttt1PttSsIptDstStts "Aftertreatment 1 Particulate Sensor Input Diagnostic Status: The value of this parameter is not retained when power is removed from the particulate sensor.000b = Tests monitored continuously. There are no enable or pause conditions. See Aftertreatmen...";
CM_ SG_ 2499556094 Atttt1PttSsIptPFMI "Aftertreatment 1 Particulate Sensor Input Preliminary FMI: Used to identify the applicable J1939-73 FMI detected in the aftertreatment particulate sensor input by the manufacturer’s sensor control software in exhaust bank 1. In the case of multiple f...";
CM_ SG_ 2499556094 Atttt1PttSsPwSppDstStts "Aftertreatment 1 Particulate Sensor Power Supply Diagnostic Status: The value of this parameter is not retained when power is removed from the particulate sensor.000b = Tests monitored continuously. There are no enable or pause conditions. See Aftert...";
CM_ SG_ 2499556094 Atttt1PttSsPwSppPFMI "Aftertreatment 1 Particulate Sensor Power Supply Preliminary FMI: Used to identify the applicable J1939-73 FMI detected in the aftertreatment particulate sensor power supply by the manufacturer’s sensor control software in exhaust bank 1. In the case...";
CM_ BO_ 2499556350 "Engine Fuel Injector Metering Rail Pressure Information 3";
CM_ SG_ 2499556350 EngnFl1InjtrMtrngRl1DsrdPrssr "Engine Fuel 1 Injector Metering Rail 1 Desired Pressure: The desired pressure of fuel in the primary, or first, metering rail as delivered from the supply pump to the injector metering intake.";
CM_ SG_ 2499556350 EngnFl1InjtrMtrngRl2DsrdPrssr "Engine Fuel 1 Injector Metering Rail 2 Desired Pressure: The desired pressure of fuel in metering rail 2 as delivered from the supply pump to the injector metering intake.";
CM_ BO_ 2499556606 "Engine Fuel Injector Metering Rail Pressure Information 2";
CM_ SG_ 2499556606 EF1ItMtR1Pss1ExtddR "Engine Fuel 1 Injector Metering Rail 1 Pressure 1 (Extended Range): The pressure of fuel measured by first rail pressure sensor in the primary, or first, metering rail as delivered from the supply pump to the injector metering intake.";
CM_ SG_ 2499556606 EF1ItMtR1Pss2ExtddR "Engine Fuel 1 Injector Metering Rail 1 Pressure 2 (Extended Range): The pressure of fuel measured by the second rail pressure sensor in the primary, or first, metering rail as delivered from the supply pump to the injector metering intake.";
CM_ SG_ 2499556606 EF1ItMtR2Pss1ExtddR "Engine Fuel 1 Injector Metering Rail 2 Pressure 1 (Extended Range): The pressure of fuel measured by first rail pressure sensor in the metering rail 2 as delivered from the supply pump to the injector metering intake.";
CM_ SG_ 2499556606 EF1ItMtR2Pss2ExtddR "Engine Fuel 1 Injector Metering Rail 2 Pressure 2 (Extended Range): The pressure of fuel measured by second rail pressure sensor in the metering rail 2 as delivered from the supply pump to the injector metering intake.";
CM_ BO_ 2499557118 "Gaseous Fuel Supply Valve Information";
CM_ SG_ 2499557118 EngnGssFlSpplBldVlv1Pstn "Engine Gaseous Fuel Supply Bleed Valve 1 Position: Position of bleed valve 1, which is used to control the flow of gaseous fuel through the fuel supply unit. 0% represents valve fully closed and 100% represents valve fully open.";
CM_ SG_ 2499557118 EngnGssFlSpplBldVlv2Pstn "Engine Gaseous Fuel Supply Bleed Valve 2 Position: Position of bleed valve 2, which is used to control the flow of gaseous fuel through the fuel supply unit. 0% represents valve fully closed and 100% represents valve fully open.";
CM_ SG_ 2499557118 EngnGssFlSpplBldVlv3Pstn "Engine Gaseous Fuel Supply Bleed Valve 3 Position: Position of bleed valve 3, which is used to control the flow of gaseous fuel through the fuel supply unit. 0% represents valve fully closed and 100% represents valve fully open.";
CM_ SG_ 2499557118 EngnGssFlSpplShtffVlv1Pstn "Engine Gaseous Fuel Supply Shutoff Valve 1 Position: Position of shutoff valve 1, which is used to control the flow of gaseous fuel through the fuel supply unit. 0% represents valve fully closed and 100% represents valve fully open.";
CM_ SG_ 2499557118 EngnGssFlSpplShtffVlv2Pstn "Engine Gaseous Fuel Supply Shutoff Valve 2 Position: Position of shutoff valve 2, which is used to control the flow of gaseous fuel through the fuel supply unit. 0% represents valve fully closed and 100% represents valve fully open.";
CM_ SG_ 2499557118 InertGasSupplyValvePosition "Inert Gas Supply Valve Position: Position of inert gas supply valve used to control the flow of inert gas into the engine to purge the system.0% represents valve fully closed and 100% represents valve fully open.";
CM_ BO_ 2499557374 "Engine Oil Mist Detection Information 2";
CM_ SG_ 2499557374 EngineOilMist10Concentration "Engine Oil Mist 10 Concentration: Percentage of detected oil mist in compartment 10 compared to the lower explosion limit (LEL). 100% means the measured value is on the lower explosion limit,whereas 0% means no detected oil mist in the air.";
CM_ SG_ 2499557374 EngineOilMist9Concentration "Engine Oil Mist 9 Concentration: Percentage of detected oil mist in compartment 9 compared to the lower explosion limit (LEL). 100% means the measured value is on the lower explosion limit,whereas 0% means no detected oil mist in the air.";
CM_ BO_ 2499557630 "Engine Oil Mist Detection Information 1";
CM_ SG_ 2499557630 EngineOilMist1Concentration "Engine Oil Mist 1 Concentration: Percentage of detected oil mist in compartment 1 compared to the lower explosion limit (LEL). 100% means the measured value is on the lower explosion limit, whereas 0% means no detected oil mist in the air. This measu...";
CM_ SG_ 2499557630 EngineOilMist2Concentration "Engine Oil Mist 2 Concentration: Percentage of detected oil mist in compartment 2 compared to the lower explosion limit (LEL). 100% means the measured value is on the lower explosion limit,whereas 0% means no detected oil mist in the air.";
CM_ SG_ 2499557630 EngineOilMist3Concentration "Engine Oil Mist 3 Concentration: Percentage of detected oil mist in compartment 3 compared to the lower explosion limit (LEL). 100% means the measured value is on the lower explosion limit,whereas 0% means no detected oil mist in the air.";
CM_ SG_ 2499557630 EngineOilMist4Concentration "Engine Oil Mist 4 Concentration: Percentage of detected oil mist in compartment 4 compared to the lower explosion limit (LEL). 100% means the measured value is on the lower explosion limit,whereas 0% means no detected oil mist in the air.";
CM_ SG_ 2499557630 EngineOilMist5Concentration "Engine Oil Mist 5 Concentration: Percentage of detected oil mist in compartment 5 compared to the lower explosion limit (LEL). 100% means the measured value is on the lower explosion limit,whereas 0% means no detected oil mist in the air.";
CM_ SG_ 2499557630 EngineOilMist6Concentration "Engine Oil Mist 6 Concentration: Percentage of detected oil mist in compartment 6 compared to the lower explosion limit (LEL). 100% means the measured value is on the lower explosion limit,whereas 0% means no detected oil mist in the air.";
CM_ SG_ 2499557630 EngineOilMist7Concentration "Engine Oil Mist 7 Concentration: Percentage of detected oil mist in compartment 7 compared to the lower explosion limit (LEL). 100% means the measured value is on the lower explosion limit,whereas 0% means no detected oil mist in the air.";
CM_ SG_ 2499557630 EngineOilMist8Concentration "Engine Oil Mist 8 Concentration: Percentage of detected oil mist in compartment 8 compared to the lower explosion limit (LEL). 100% means the measured value is on the lower explosion limit,whereas 0% means no detected oil mist in the air.";
CM_ BO_ 2499557886 "Gaseous Fuel Supply Pressure 2";
CM_ SG_ 2499557886 PlntGssFlSpplOtltPrssr "Plant Gaseous Fuel Supply Outlet Pressure: Pressure of the gaseous fuel supplied from the plant room for one or more engines.  Based on the application, plant room will contain fuel tank for gas, vaporizer and heater and cooler compartments.";
CM_ SG_ 2499557886 PlntInrtGsSpplOtltPrssr "Plant Inert Gas Supply Outlet Pressure: Pressure of the purge gas supplied to the engine. Inert gas is used to remove gaseous fuel build-up in the engines and in the fuel supply lines when gaseous fuel is not in operation.";
CM_ BO_ 2499558142 "Gaseous Fuel Supply Pressure 1";
CM_ SG_ 2499558142 EngnGssFlSpplPrssr2 "Engine Gaseous Fuel Supply Pressure 2: Second gage pressure measurement of gaseous fuel supply to fuel metering device. If only one sensor is used for gas supply pressure measurement, use SPN 159 instead.";
CM_ SG_ 2499558142 EngnGssFlSpplShtffVlv1IntkPrssr "Engine Gaseous Fuel Supply Shutoff Valve 1 Intake Pressure: Pressure of gaseous fuel supply measured at shutoff valve 1 in gaseous fuel supply unit. Shutoff valves are used to regulate gaseous fuel supply to engine.";
CM_ SG_ 2499558142 EngnGssFlSpplShtffVlv2IntkPrssr "Engine Gaseous Fuel Supply Shutoff Valve 2 Intake Pressure: Pressure of gaseous fuel supply measured at shutoff valve 2 in gaseous fuel supply unit. Shutoff valves are used to regulate gaseous fuel supply to engine.";
CM_ SG_ 2499558142 EngnGssFlSpplUntIntkPrssr "Engine Gaseous Fuel Supply Unit Intake Pressure: Pressure of gaseous fuel supply measured at the intake of gaseous fuel supply unit. Gaseous fuel valve unit contains block and bleed valves to regulate the flow of gaseous fuel from the plant to engine...";
CM_ BO_ 2499580158 "Engine Fuel Injector Metering Rail Pressure Information 1";
CM_ SG_ 2499580158 EngnFl1InjtrMtrngRl1Prssr1 "Engine Fuel 1 Injector Metering Rail 1 Pressure 1: The pressure of fuel measured by first rail pressure sensor in the primary, or first, metering rail as delivered from the supply pump to the injector metering intake.Note:  This is for the rail press...";
CM_ SG_ 2499580158 EngnFl1InjtrMtrngRl1Prssr2 "Engine Fuel 1 Injector Metering Rail 1 Pressure 2: The pressure of fuel measured by the second rail pressure sensor in the primary, or first, metering rail as delivered from the supply pump to the injector metering intake. Note:  This is for the rail...";
CM_ SG_ 2499580158 EngnFl1InjtrMtrngRl2Prssr1 "Engine Fuel 1 Injector Metering Rail 2 Pressure 1: The pressure of fuel measured by first rail pressure sensor in the metering rail 2 as delivered from the supply pump to the injector metering intake.Note:  This is for the rail pressure from the 1st ...";
CM_ SG_ 2499580158 EngnFl1InjtrMtrngRl2Prssr2 "Engine Fuel 1 Injector Metering Rail 2 Pressure 2: The pressure of fuel measured by second rail pressure sensor in the metering rail 2 as delivered from the supply pump to the injector metering intake. Note:  This is for the rail pressure from the 2n...";
CM_ BO_ 2499582206 "Vehicle Speed Limiter";
CM_ SG_ 2499582206 SftTpSpdLmtRmnngCntnsIntrvlDstn "Soft Top Speed Limit Remaining Continuous Interval Distance: Indicates the remaining distance that the vehicle can continuously travel at the Soft Top Speed Limit.  This parameter will decrement while the Soft Top Speed Limit Active (SPN 6370) is 1 a...";
CM_ SG_ 2499582206 SftTpSpdLmtRmnngDstn "Soft Top Speed Limit Remaining Distance: Indicates the remaining distance that the vehicle can travel at the Soft Top Speed Limit within the larger reset window. The reset window may be distance (possibly indicated by SPN 6373), time, or something el...";
CM_ SG_ 2499582206 SoftTopRatioLimitExceeded "Soft Top Ratio Limit Exceeded: Greenhouse Gas Regulations limit the overall distance that Soft Top Speed can be used in relation to the total distance traveled. This parameter indicates the allowable ratio has been exceeded and Soft Top Speed is unav...";
CM_ SG_ 2499582206 SoftTopSpeedLimitActive "Soft Top Speed Limit Active: Indicates that the current Maximum Vehicle Speed Limit (SPN 74) has been temporarily increased to the Soft Top Speed Limit. Under certain conditions, the legal speed limit allowed by the Greenhouse Gas Regulations can be ...";
CM_ SG_ 2499582206 SoftTopSpeedLimitResetDistance "Soft Top Speed Limit Reset Distance: This parameter will decrement as long as the vehicle is moving. When this parameter reaches 0, it will be reset to its maximum value and continue to decrement.";
CM_ BO_ 2499583486 "Engine Timing Actuator Position Command";
CM_ SG_ 2499583486 EngnTmngAttr1PstnCmmnd "Engine Timing Actuator 1 Position Command: The commanded position of actuator 1 on the engine timing system by Engine Control Module.  The engine timing system has different timing positions and the timing positions may be used to determine intake an...";
CM_ SG_ 2499583486 EngnTmngAttr2PstnCmmnd "Engine Timing Actuator 2 Position Command: The commanded position of actuator 2 on the engine timing system by Engine Control Module.  The engine timing system has different timing positions and the timing positions may be used to determine intake an...";
CM_ BO_ 2499583742 "Engine Timing Actuator Position";
CM_ SG_ 2499583742 EngineTimingActuator1 "Engine Timing Actuator 1: The detected position of actuator 1 on the Engine Timing System, where the system has different timing positions depending on current operating status of the engine. Timing positions may be used to determine intake and outle...";
CM_ SG_ 2499583742 EngineTimingActuator2 "Engine Timing Actuator 2: The detected position of actuator 2 on the Engine Timing System, where the system has different timing positions depending on current operating status of the engine. Timing positions may be used to determine intake and outle...";
CM_ SG_ 2499583742 EngnTmngAttr1RqstdPstn "Engine Timing Actuator 1 Requested Position: The requested position of actuator 1 on the Engine Timing System, as determined by external system such as operator, monitoring, or protection system. Requested position is sent to the Control Module sendi...";
CM_ SG_ 2499583742 EngnTmngAttr2RqstdPstn "Engine Timing Actuator 2 Requested Position: The requested position of actuator 2 on the Engine Timing System, as determined by external system such as operator, monitoring or protection system. Requested position is sent to the Control Module sendin...";
CM_ BO_ 2499592190 "Electronic Transmission Controller #10";
CM_ SG_ 2499592190 TrnsmssnClth1AttrPrnt "Transmission Clutch 1 Actuator Percent: The current modulated value for the transmission clutch 1 actuator, where 0% = no hydraulic pressure and 100% = full hydraulic pressure.";
CM_ SG_ 2499592190 TrnsmssnClth1ClngAttrStts "Transmission Clutch 1 Cooling Actuator Status: Identifies the status of the actuator that cools transmission clutch 1.00b = off01b = on10b = error11b = not available";
CM_ SG_ 2499592190 TrnsmssnClth2AttrPrnt "Transmission Clutch 2 Actuator Percent: The current modulated value for the transmission clutch 2 actuator, where 0% = no hydraulic pressure and 100% = full hydraulic pressure.";
CM_ SG_ 2499592190 TrnsmssnClth2ClngAttrStts "Transmission Clutch 2 Cooling Actuator Status: Identifies the status of the actuator that cools transmission clutch 2.00b = off01b = on10b = error11b = not available";
CM_ SG_ 2499592190 TrnsmssnHdrlPmpAttr1Prnt "Transmission Hydraulic Pump Actuator 1 Percent: The current modulated value for the actuator that controls the transmission hydraulic pump, where 0% = no hydraulic pressure and 100% = full hydraulic pressure.";
CM_ SG_ 2499592190 TrnsmssnHdrlPmpAttr2Prnt "Transmission Hydraulic Pump Actuator 2 Percent: The current modulated value for actuator 2 that controls the transmission hydraulic pump, where 0% = no hydraulic pressure and 100% = full hydraulic pressure.";
CM_ SG_ 2499592190 TrnsmssnShftAttr1Prnt "Transmission Shift Actuator 1 Percent: The current modulated value for the transmission shift 1 actuator, where 0% = no hydraulic pressure and 100% = full hydraulic pressure.";
CM_ SG_ 2499592190 TrnsmssnShftAttr2Prnt "Transmission Shift Actuator 2 Percent: The current modulated value for the transmission shift 2 actuator, where 0% = no hydraulic pressure and 100% = full hydraulic pressure.";
CM_ SG_ 2499592190 TrnsmssnShftRl1AttrStts "Transmission Shift Rail 1 Actuator Status: Identifies the status of the actuator that moves the transmission shift rail identified as rail #1.00b = off01b = on10b = error11b = not available";
CM_ SG_ 2499592190 TrnsmssnShftRl2AttrStts "Transmission Shift Rail 2 Actuator Status: Identifies the status of the actuator that moves the transmission shift rail identified as rail #2.00b = off01b = on10b = error11b = not available";
CM_ SG_ 2499592190 TrnsmssnShftRl3AttrStts "Transmission Shift Rail 3 Actuator Status: Identifies the status of the actuator that moves the transmission shift rail identified as rail #3.00b = off01b = on10b = error11b = not available";
CM_ SG_ 2499592190 TrnsmssnShftRl4AttrStts "Transmission Shift Rail 4 Actuator Status: Identifies the status of the actuator that moves the transmission shift rail identified as rail #4.00b = off01b = on10b = error11b = not available";
CM_ SG_ 2499592190 TrnsmssnShftRl5AttrStts "Transmission Shift Rail 5 Actuator Status: Identifies the status of the actuator that moves the transmission shift rail identified as rail #5.00b = off01b = on10b = error11b = not available";
CM_ SG_ 2499592190 TrnsmssnShftRl6AttrStts "Transmission Shift Rail 6 Actuator Status: Identifies the status of the actuator that moves the transmission shift rail identified as rail #6.00b = off01b = on10b = error11b = not available";
CM_ BO_ 2499592446 "Electronic Transmission Controller #11";
CM_ SG_ 2499592446 TransmissionShiftRail1Position "Transmission Shift Rail 1 Position: The current position of transmission shift rail identified as rail #1.";
CM_ SG_ 2499592446 TransmissionShiftRail2Position "Transmission Shift Rail 2 Position: The current position of transmission shift rail identified as rail #2.";
CM_ SG_ 2499592446 TransmissionShiftRail3Position "Transmission Shift Rail 3 Position: The current position of transmission shift rail identified as rail #3.";
CM_ SG_ 2499592446 TransmissionShiftRail4Position "Transmission Shift Rail 4 Position: The current position of transmission shift rail identified as rail #4.";
CM_ SG_ 2499592446 TransmissionShiftRail5Position "Transmission Shift Rail 5 Position: The current position of transmission shift rail identified as rail #5.";
CM_ SG_ 2499592446 TransmissionShiftRail6Position "Transmission Shift Rail 6 Position: The current position of transmission shift rail identified as rail #6.";
CM_ BO_ 2499604222 "Land Leveling System Reference Elevation Data";
CM_ SG_ 2499604222 BladeElevationDeviationLeft "Blade Elevation Deviation - Left: Indicate the blade's left elevation deviation with respect to the reference elevation.  Serves as an indication of how far the left end of the blade is above or below grade.  A positive number indicates that the blad...";
CM_ SG_ 2499604222 BladeElevationDeviationRight "Blade Elevation Deviation - Right: Indicate the blade's right elevation deviation with respect to the reference elevation.  Serves as an indication of how far the left end of the blade is above or below grade.  A positive number indicates that the bl...";
CM_ SG_ 2499604222 BldRfrnElvtnOffstLft "Blade Reference Elevation Offset - Left: Indicates the blade's left elevation offset with respect to the reference elevation.  An offset of 0 m represents no offset from the reference elevation.  A positive number indicates that the offset elevation ...";
CM_ SG_ 2499604222 BldRfrnElvtnOffstRght "Blade Reference Elevation Offset - Right: Indicates the blade's right elevation offset with respect to the reference elevation.  An offset of 0 m represents no offset from the reference elevation.  A positive number indicates that the offset elevatio...";
CM_ BO_ 2499604478 "Engine Fluid Level/Pressure 11";
CM_ SG_ 2499604478 EExstGsRt1OttAstPssHRst "Engine Exhaust Gas Recirculation 1 Outlet Absolute Pressure (High Resolution): EGR outlet absolute pressure is measured after the EGR 1 valve. See SPN 5019 for 1 byte resolution.";
CM_ SG_ 2499604478 EFDvPssHRstExtddR "Engine Fuel Delivery Pressure (High Resolution/Extended Range): Gage pressure of fuel in system as delivered from supply pump to the injection pump. See SPN 94 for alternate resolution.See also SPN 5578 for Engine Fuel Delivery Absolute Pressure.";
CM_ SG_ 2499604478 EngnExhstGsRrltn1IntkAsltPrssr "Engine Exhaust Gas Recirculation 1 Intake Absolute Pressure: EGR intake absolute pressure measured before the EGR 1 valve.";
CM_ SG_ 2499604478 EngnOlPrssrHghRsltnExtnddRng "Engine Oil Pressure (High Resolution/Extended Range): Gage pressure of oil in engine lubrication system as provided by oil pump. See SPN 100 for alternate resolution.";
CM_ BO_ 2499607550 "Engine Manifold Actuator Position";
CM_ SG_ 2499607550 EExstMdB1FwBVvAttPst "Engine Exhaust Manifold Bank 1 Flow Balance Valve Actuator Position: Actual percentage of maximum Engine Exhaust Manifold Bank 1 Balance valve opening. 0% means valve is closed. 100% means maximum valve opening (full gas flow).";
CM_ SG_ 2499607550 EExstMdB2FwBVvAttPst "Engine Exhaust Manifold Bank 2 Flow Balance Valve Actuator Position: Actual percentage of maximum Engine Manifold Bank 2 Balance valve opening. 0% means valve is closed. 100% means maximum valve opening (full gas flow).";
CM_ BO_ 2499614462 "Occupant Classification System Information";
CM_ SG_ 2499614462 DrvrOpntClssftnSstmStts "Driver Occupant Classification System Status: State of Occupant Classification System for driver.000b = empty001b = child010b = small adult011b = adult100b = large adult101b = reserved110b = Error - Classification of occupant cannot be determined111b...";
CM_ SG_ 2499614462 OpntClssftnSstm10Stts "Occupant Classification System 10 Status: State of Occupant Classification System for seat position 10.00b = empty01b = occupied10b = Error - Classification cannot be determined11b = not available";
CM_ SG_ 2499614462 OpntClssftnSstm3Stts "Occupant Classification System 3 Status: State of Occupant Classification System for seat position 3.00b = empty01b = occupied10b = Error - Classification cannot be determined11b = not available";
CM_ SG_ 2499614462 OpntClssftnSstm4Stts "Occupant Classification System 4 Status: State of Occupant Classification System for seat position 4.00b = empty01b = occupied10b = Error - Classification cannot be determined11b = not available";
CM_ SG_ 2499614462 OpntClssftnSstm5Stts "Occupant Classification System 5 Status: State of Occupant Classification System for seat position 5.00b = empty01b = occupied10b = Error - Classification cannot be determined11b = not available";
CM_ SG_ 2499614462 OpntClssftnSstm6Stts "Occupant Classification System 6 Status: State of Occupant Classification System for seat position 6.00b = empty01b = occupied10b = Error - Classification cannot be determined11b = not available";
CM_ SG_ 2499614462 OpntClssftnSstm7Stts "Occupant Classification System 7 Status: State of Occupant Classification System for seat position 7.00b = empty01b = occupied10b = Error - Classification cannot be determined11b = not available";
CM_ SG_ 2499614462 OpntClssftnSstm8Stts "Occupant Classification System 8 Status: State of Occupant Classification System for seat position 8.00b = empty01b = occupied10b = Error - Classification cannot be determined11b = not available";
CM_ SG_ 2499614462 OpntClssftnSstm9Stts "Occupant Classification System 9 Status: State of Occupant Classification System for seat position 9.00b = empty01b = occupied10b = Error - Classification cannot be determined11b = not available";
CM_ SG_ 2499614462 PssngrOpntClssftnSstmStts "Passenger Occupant Classification System Status: State of Occupant Classification System for passenger.000b = empty001b = child010b = small adult011b = adult100b = large adult101b = Error - Classification of occupant cannot be determined110b = reserv...";
CM_ BO_ 2499614718 "Beltlock and Airbag Deactivation Switch Information";
CM_ SG_ 2499614718 Beltlock10Status "Beltlock 10 Status: State of switch used to determine if Beltlock 10 is buckled.00b = unlocked01b = locked10b = Error - Beltlock state cannot be determined11b = not available";
CM_ SG_ 2499614718 Beltlock3Status "Beltlock 3 Status: State of switch used to determine if Beltlock 3 is buckled.00b = unlocked01b = locked10b = Error - Beltlock state cannot be determined11b = not available";
CM_ SG_ 2499614718 Beltlock4Status "Beltlock 4 Status: State of switch used to determine if Beltlock 4 is buckled.00b = unlocked01b = locked10b = Error - Beltlock state cannot be determined11b = not available";
CM_ SG_ 2499614718 Beltlock5Status "Beltlock 5 Status: State of switch used to determine if Beltlock 5 is buckled.00b = unlocked01b = locked10b = Error - Beltlock state cannot be determined11b = not available";
CM_ SG_ 2499614718 Beltlock6Status "Beltlock 6 Status: State of switch used to determine if Beltlock 6 is buckled.00b = unlocked01b = locked10b = Error - Beltlock state cannot be determined11b = not available";
CM_ SG_ 2499614718 Beltlock7Status "Beltlock 7 Status: State of switch used to determine if Beltlock 7 is buckled.00b = unlocked01b = locked10b = Error - Beltlock state cannot be determined11b = not available";
CM_ SG_ 2499614718 Beltlock8Status "Beltlock 8 Status: State of switch used to determine if Beltlock 8 is buckled.00b = unlocked01b = locked10b = Error - Beltlock state cannot be determined11b = not available";
CM_ SG_ 2499614718 Beltlock9Status "Beltlock 9 Status: State of switch used to determine if Beltlock 9 is buckled.00b = unlocked01b = locked10b = Error - Beltlock state cannot be determined11b = not available";
CM_ SG_ 2499614718 DriverBeltlockStatus "Driver Beltlock Status: State of switch used to determine if Driver Beltlock is buckled.00b = unlocked01b = locked10b = Error - Beltlock state cannot be determined11b = not available";
CM_ SG_ 2499614718 PassengerBeltlockStatus "Passenger Beltlock Status: State of switch used to determine if Passenger Beltlock is buckled.00b = unlocked01b = locked10b = Error - Beltlock state cannot be determined11b = not available";
CM_ SG_ 2499614718 PssngrArgDtvtnSwthStts "Passenger Airbag Deactivation Switch Status: State of switch used to deactivate Passenger Airbag manually.00b = passenger airbag activated01b = passenger airbag deactivated10b = Error - State of deactivation switch cannot be determined11b = not avail...";
CM_ BO_ 2499624702 "Aftertreatment 1 SCR Exhaust Gas Temperature 1";
CM_ SG_ 2499624702 Aftrtrtmnt1SCRIntkTmprtr "Aftertreatment 1 SCR Intake Temperature: Temperature of engine combustion byproducts entering the SCR in exhaust bank 1.";
CM_ SG_ 2499624702 Aftrtrtmnt1SCROtltTmprtr "Aftertreatment 1 SCR Outlet Temperature: Temperature of engine combustion byproducts leaving the SCR outlet in exhaust bank 1.";
CM_ SG_ 2499624702 Atttt1SCRItTptPFMI "Aftertreatment 1 SCR Intake Temperature Preliminary FMI: Used to identify the applicable J1939-73 FMI detected in the SCR intake temperature sensor by the manufacturer’s sensor control software in exhaust bank 1.  In the case of multiple failures the...";
CM_ SG_ 2499624702 Atttt1SCROttTptPFMI "Aftertreatment 1 SCR Outlet Temperature Preliminary FMI: Used to identify the applicable J1939-73 FMI detected in the SCR outlet temperature sensor by the manufacturer’s sensor control software in exhaust bank 1. In the case of multiple failures the ...";
CM_ BO_ 2499630078 "Engine Average Information";
CM_ SG_ 2499630078 EngineExhaustTemperatureAverage "Engine Exhaust Temperature Average: The calculated average temperature based upon all of the engine exhaust port temperatures.  This is the average temperature based upon the exhaust port temperature measurements at each of the engine cylinders.Notes...";
CM_ SG_ 2499630078 EngnExhstBnk1TmprtrAvrg "Engine Exhaust Bank 1 Temperature Average: The calculated average temperature based upon all of the Bank 1 (left bank) engine exhaust port temperatures.  This is the average temperature based upon the exhaust port temperature measurements of each of ...";
CM_ SG_ 2499630078 EngnExhstBnk2TmprtrAvrg "Engine Exhaust Bank 2 Temperature Average: The calculated average temperature based upon all of the Bank 2 (right bank) engine exhaust port temperatures.  This is the average temperature based upon the exhaust port temperature measurements of each of...";
CM_ BO_ 2499635454 "Gross Combination Vehicle Weight";
CM_ SG_ 2499635454 GrossCombinationWeight "Gross Combination Weight: Total weight of the truck and all the trailers with on-board scales.";
CM_ SG_ 2499635454 NetVehicleWeightChange "Net Vehicle Weight Change: Identifies the net vehicle weight change from the time of last vehicle net weight zeroing.";
CM_ BO_ 2499635966 "Axle Group Weight";
CM_ SG_ 2499635966 AdditionalAxleGroupLocation "Additional Axle Group Location: Location of the axle group, listed from front of the vehicle to rear.  If the value of SPN 4073 is 15, then this SP is used to indicate the axle group referred to by this PG. Otherwise, this SP should be broadcast as 1...";
CM_ SG_ 2499635966 AxleGroupLocation "Axle Group Location: Specific axle group used in conjunction with and when communicating the axle group weight, listed from the front of the vehicle to the rear.If the value of SPN 5935 is 1111b, then this SP is used to indicate the axle group referr...";
CM_ SG_ 2499635966 AxleGroupWeight "Axle Group Weight: Total mass imposed on the road surface by all the tires in the axle group";
CM_ BO_ 2499641854 "EGR Cooler Bypass";
CM_ SG_ 2499641854 EExstGsRt1CBpssAttPst "Engine Exhaust Gas Recirculation 1 Cooler Bypass Actuator Position: The parameter gives the % open of the exhaust gas recirculation cooler bypass actuator, where 0% = Fully Closed (no gas flowing through the bypass), and 100% = Fully Open.";
CM_ BO_ 2550660862 "General Purpose Valve Pressure";
CM_ SG_ 2550660862 ValveAssemblyLoadsensePressure "Valve Assembly Load sense Pressure: The maximum pressure of a valve assembly's current collective load sense pressures where a valve assembly can consist of two or more valves.";
CM_ SG_ 2550660862 ValveAssemblySupplyPressure "Valve Assembly Supply Pressure: Pressure of the hydraulic supply port to a valve assembly.";
CM_ SG_ 2550660862 ValveLoadSensePressure "Valve Load Sense Pressure: The maximum of the currently measured pressures of a valve's work port A and work port B.";
CM_ SG_ 2550660862 ValvePilotPressure "Valve Pilot Pressure: Pressure of a valve's pilot supply port.";
CM_ BO_ 2550988542 "Electronic Engine Controller 16";
CM_ SG_ 2550988542 EngineClutchEngageRequestStatus "Engine Clutch Engage Request Status: Indicates if the engine has an external request to establish its operating conditions to be appropriate for engagement of the transmission or gearbox.00b = Engine does not have an external request01b = Engine has ...";
CM_ SG_ 2550988542 ReadyForClutchEngagementStatus "Ready For Clutch Engagement Status: Indicates the engine operating conditions are appropriate for engagement of the transmission or gearbox clutch.00b = Engine Not Ready For Clutch Engagement01b = Engine is Ready For Clutch Engagement10b = Error11b =...";
CM_ SG_ 2550988542 AcceleratorPedal3Position "Accelerator Pedal 3 Position: The ratio of actual position of the third analog engine speed/torque request input device (such as an accelerator pedal or throttle lever) to the maximum position of the input device.  This parameter is intended for the ...";
CM_ BO_ 2557214462 "Well Stimulation Pump Sensor Calibration Command";
CM_ SG_ 2557214462 WSttPpDsPssCtStPtCd "Well Stimulation Pump Discharge Pressure Calibration Set Point Command: Specifies the current discharge pressure whose calibration status is being reported. Multipoint calibration of the discharge pressure system is performed by increasing the pressu...";
CM_ SG_ 2557214462 WSttPpStPssCtStPtCd "Well Stimulation Pump Suction Pressure Calibration Set Point Command: Specifies the current suction pressure being calibrated. Multipoint calibration of the suction pressuresystem is performed by increasing the pressure with up to 10 known calibratio...";
CM_ BO_ 2557345534 "Well Stimulation Pump System Configuration Command";
CM_ SG_ 2557345534 WllStmltnPmpPlngrFrngOrdr "Well Stimulation Pump Plunger Firing Order: Well stimulation pump plunger firing order0000b = Firing order 1-2-30001b = Firing order 1-5-2-3-40010b = Reserved0011b = Reserved0100b = Reserved0101b = Reserved0110b = Reserved0111b = Reserved1000b = Rese...";
CM_ SG_ 2557345534 WllStmltnPmpRdLdHghThrshld "Well Stimulation Pump Rod Load High Threshold: Rod load force at which the rod load is considered at the highest acceptable force.";
CM_ SG_ 2557345534 WllStmltnPmpStnPrssrHghThrshld "Well Stimulation Pump Suction Pressure High Threshold: Pressure at which the suction pressure is considered at the highest acceptable pressure.";
CM_ SG_ 2557345534 WllStmltnPmpStnPrssrLwThrshld "Well Stimulation Pump Suction Pressure Low Threshold: Pressure at which the suction pressure is considered at the lowest acceptable pressure.";
CM_ SG_ 2557345534 WSttPpCstSpdHTsd "Well Stimulation Pump Crankshaft Speed High Threshold: Well stimulation pump crankshaft speed that has been considered to be the highest acceptable speed.";
CM_ SG_ 2557345534 WSttPpCstSpdLwTsd "Well Stimulation Pump Crankshaft Speed Low Threshold: The minimum speed of Well stimulation pump crankshaft that is considered to be valid.";
CM_ SG_ 2557345534 WSttPpDsPssHTsd "Well Stimulation Pump Discharge Pressure High Threshold: Pressure at which the discharge pressure is considered at the highest acceptable pressure.";
CM_ SG_ 2557345534 WSttPpGBxOPssHTsd "Well Stimulation Pump Gear Box Oil Pressure High Threshold: Pressure at which the gearbox oil pressure is considered at the highest acceptable pressure.";
CM_ SG_ 2557345534 WSttPpGBxOPssLwTsd "Well Stimulation Pump Gear Box Oil Pressure Low Threshold: Pressure at which the gearbox oil pressure is considered at the lowest acceptable pressure.";
CM_ SG_ 2557345534 WSttPpGBxOTptHTsd "Well Stimulation Pump Gear Box Oil Temperature High Threshold: Temperature at which the gearbox oil temperature is considered at the highest acceptable temperature.";
CM_ SG_ 2557345534 WSttPpGBxOTptLwTsd "Well Stimulation Pump Gear Box Oil Temperature Low Threshold: Temperature at which the gearbox oil temperature is considered at the lowest acceptable temperature.";
CM_ BO_ 2557673214 "Oil Debris Monitor Configuration Command";
CM_ SG_ 2557673214 OlDrsMntrCnfgrtnIdntftnNmr "Oil Debris Monitor Configuration Identification Number: Identification number of the Oil Debris Monitoring (ODM) sensor being configured. Identification numbers are application specific.";
CM_ SG_ 2557673214 OlDrsMntrFrrsBn1CntCmmnd "Oil Debris Monitor Ferrous Bin 1 Count Command: New starting value for total count of particles detected in Ferrous bin 1.NOTE: The value FFFFFFh indicates Do Not Change (i.e. the current count value of the Oil Debris Monitor for this bin will not be...";
CM_ SG_ 2557673214 OlDrsMntrFrrsBn2CntCmmnd "Oil Debris Monitor Ferrous Bin 2 Count Command: New starting value for total count of particles detected in Ferrous bin 2.NOTE: The value FFFFFFh indicates Do Not Change (i.e. the current count value of the Oil Debris Monitor for this bin will not be...";
CM_ SG_ 2557673214 OlDrsMntrFrrsBn3CntCmmnd "Oil Debris Monitor Ferrous Bin 3 Count Command: New starting value for total count of particles detected in Ferrous bin 3.NOTE: The value FFFFFFh indicates Do Not Change (i.e. the current count value of the Oil Debris Monitor for this bin will not be...";
CM_ SG_ 2557673214 OlDrsMntrFrrsBn4CntCmmnd "Oil Debris Monitor Ferrous Bin 4 Count Command: New starting value for total count of particles detected in Ferrous bin 4.NOTE: The value FFFFFFh indicates Do Not Change (i.e. the current count value of the Oil Debris Monitor for this bin will not be...";
CM_ SG_ 2557673214 OlDrsMntrFrrsBn5CntCmmnd "Oil Debris Monitor Ferrous Bin 5 Count Command: New starting value for total count of particles detected in Ferrous bin 5.NOTE: The value FFFFFFh indicates Do Not Change (i.e. the current count value of the Oil Debris Monitor for this bin will not be...";
CM_ SG_ 2557673214 OlDrsMntrFrrsBn6CntCmmnd "Oil Debris Monitor Ferrous Bin 6 Count Command: New starting value for total count of particles detected in Ferrous bin 6.NOTE: The value FFFFFFh indicates Do Not Change (i.e. the current count value of the Oil Debris Monitor for this bin will not be...";
CM_ SG_ 2557673214 OlDrsMntrNnFrrsBn1CntCmmnd "Oil Debris Monitor Non-Ferrous Bin 1 Count Command: New starting value for total count of particles detected in Non-Ferrous bin 1.NOTE: The value FFFFFFh indicates Do Not Change (i.e. the current count value of the Oil Debris Monitor for this bin wil...";
CM_ SG_ 2557673214 OlDrsMntrNnFrrsBn2CntCmmnd "Oil Debris Monitor Non-Ferrous Bin 2 Count Command: New starting value for total count of particles detected in Non-Ferrous bin 2.NOTE: The value FFFFFFh indicates Do Not Change (i.e. the current count value of the Oil Debris Monitor for this bin wil...";
CM_ SG_ 2557673214 OlDrsMntrNnFrrsBn3CntCmmnd "Oil Debris Monitor Non-Ferrous Bin 3 Count Command: New starting value for total count of particles detected in Non-Ferrous bin 3.NOTE: The value FFFFFFh indicates Do Not Change (i.e. the current count value of the Oil Debris Monitor for this bin wil...";
CM_ SG_ 2557673214 OlDrsMntrNnFrrsBn4CntCmmnd "Oil Debris Monitor Non-Ferrous Bin 4 Count Command: New starting value for total count of particles detected in Non-Ferrous bin 4.NOTE: The value FFFFFFh indicates Do Not Change (i.e. the current count value of the Oil Debris Monitor for this bin wil...";
CM_ SG_ 2557673214 OlDrsMntrNnFrrsBn5CntCmmnd "Oil Debris Monitor Non-Ferrous Bin 5 Count Command: New starting value for total count of particles detected in Non-Ferrous bin 5.NOTE: The value FFFFFFh indicates Do Not Change (i.e. the current count value of the Oil Debris Monitor for this bin wil...";
CM_ SG_ 2557673214 OlDrsMntrNnFrrsBn6CntCmmnd "Oil Debris Monitor Non-Ferrous Bin 6 Count Command: New starting value for total count of particles detected in Non-Ferrous bin 6.NOTE: The value FFFFFFh indicates Do Not Change (i.e. the current count value of the Oil Debris Monitor for this bin wil...";
CM_ BO_ 2557738750 "Electrified Accessory Propulsion Motor Coolant Fan 3 Command";
CM_ SG_ 2557738750 PrplsnMtrClntFn3EnlCmmnd "Propulsion Motor Coolant Fan 3 Enable Command: Enable and direction command to the Propulsion Motor Coolant Fan 3.00b = Accessory Motor Off01b = Accessory Motor On Normal/Default Direction10b = Accessory Motor On Reverse Direction11b = Don't Care/Tak...";
CM_ SG_ 2557738750 PrplsnMtrClntFn3PrntSpdCmmnd "Propulsion Motor Coolant Fan 3 Percent Speed Command: Speed command to the Propulsion Motor Coolant Fan 3 in percentage of maximum speed.Note: Both Speed Command and Percent Speed Command cannot be used at the same time.  Always set the unused speed ...";
CM_ SG_ 2557738750 PrplsnMtrClntFn3PwrHld "Propulsion Motor Coolant Fan 3 Power Hold: Command to allow the Propulsion Motor Coolant Fan 3 to remain alive independently of the electrical enable input to the Accessory Motor.  For example, this could allow continued device operation after the ke...";
CM_ SG_ 2557738750 PrplsnMtrClntFn3SpdCmmnd "Propulsion Motor Coolant Fan 3 Speed Command: Speed command to the Propulsion Motor Coolant Fan 3.Note: Both Speed Command and Percent Speed Command cannot be used at the same time.  Always set the unused speed command to Not Available.  If both comm...";
CM_ BO_ 2557804286 "Electrified Accessory Propulsion Motor Coolant Fan 2 Command";
CM_ SG_ 2557804286 PrplsnMtrClntFn2EnlCmmnd "Propulsion Motor Coolant Fan 2 Enable Command: Enable and direction command to the Power Motor Coolant Fan 2.00b = Accessory Motor Off01b = Accessory Motor On Normal/Default Direction10b = Accessory Motor On Reverse Direction11b = Don't Care/Take no ...";
CM_ SG_ 2557804286 PrplsnMtrClntFn2PrntSpdCmmnd "Propulsion Motor Coolant Fan 2 Percent Speed Command: Speed command to the Propulsion Motor Coolant Fan 2 in percentage of maximum speed.Note: Both Speed Command and Percent Speed Command cannot be used at the same time.  Always set the unused speed ...";
CM_ SG_ 2557804286 PrplsnMtrClntFn2PwrHld "Propulsion Motor Coolant Fan 2 Power Hold: Command to allow the Propulsion Motor Coolant Fan 2 to remain alive independently of the electrical enable input to the Accessory Motor.  For example, this could allow continued device operation after the ke...";
CM_ SG_ 2557804286 PrplsnMtrClntFn2SpdCmmnd "Propulsion Motor Coolant Fan 2 Speed Command: Speed command to the Propulsion Motor Coolant Fan 2.Note: Both Speed Command and Percent Speed Command cannot be used at the same time.  Always set the unused speed command to Not Available.  If both comm...";
CM_ BO_ 2557869822 "Electrified Accessory Propulsion Motor Coolant Fan 1 Command";
CM_ SG_ 2557869822 PrplsnMtrClntFn1EnlCmmnd "Propulsion Motor Coolant Fan 1 Enable Command: Enable and direction command to the Propulsion Motor Coolant Fan 1.00b = Accessory Motor Off01b = Accessory Motor On Normal/Default Direction10b = Accessory Motor On Reverse Direction11b = Don't Care/Tak...";
CM_ SG_ 2557869822 PrplsnMtrClntFn1PrntSpdCmmnd "Propulsion Motor Coolant Fan 1 Percent Speed Command: Speed command to the Propulsion Motor Coolant Fan 1 in percentage of maximum speed.Note: Both Speed Command and Percent Speed Command cannot be used at the same time.  Always set the unused speed ...";
CM_ SG_ 2557869822 PrplsnMtrClntFn1PwrHld "Propulsion Motor Coolant Fan 1 Power Hold: Command to allow the Propulsion Motor Coolant Fan 1 to remain alive independently of the electrical enable input to the Accessory Motor.  For example, this could allow continued device operation after the ke...";
CM_ SG_ 2557869822 PrplsnMtrClntFn1SpdCmmnd "Propulsion Motor Coolant Fan 1 Speed Command: Speed command to the Propulsion Motor Coolant Fan 1.Note: Both Speed Command and Percent Speed Command cannot be used at the same time.  Always set the unused speed command to Not Available.  If both comm...";
CM_ BO_ 2557935358 "Electrified Accessory Power Electronics Coolant Fan 3 Command";
CM_ SG_ 2557935358 PwrEltrnsClntFn3EnlCmmnd "Power Electronics Coolant Fan 3 Enable Command: Enable and direction command to the Power Electonics Coolant Fan 3.00b = Accessory Motor Off01b = Accessory Motor On Normal/Default Direction10b = Accessory Motor On Reverse Direction11b = Don't Care/Ta...";
CM_ SG_ 2557935358 PwrEltrnsClntFn3PrntSpdCmmnd "Power Electronics Coolant Fan 3 Percent Speed Command: Speed command to the Power Electronics Coolant Fan 3 in percentage of maximum speed.Note: Both Speed Command and Percent Speed Command cannot be used at the same time.  Always set the unused spee...";
CM_ SG_ 2557935358 PwrEltrnsClntFn3PwrHld "Power Electronics Coolant Fan 3 Power Hold: Command to allow the Power Electronics Coolant Fan 3 to remain alive independently of the electrical enable input to the Accessory Motor.  For example, this could allow continued device operation after the ...";
CM_ SG_ 2557935358 PwrEltrnsClntFn3SpdCmmnd "Power Electronics Coolant Fan 3 Speed Command: Speed command to the Power Electronics Coolant Fan 3.Note: Both Speed Command and Percent Speed Command cannot be used at the same time.  Always set the unused speed command to Not Available.  If both co...";
CM_ BO_ 2558000894 "Electrified Accessory Power Electronics Coolant Fan 2 Command";
CM_ SG_ 2558000894 PwrEltrnsClntFn2EnlCmmnd "Power Electronics Coolant Fan 2 Enable Command: Enable and direction command to the Power Electonics Coolant Fan 2.00b = Accessory Motor Off01b = Accessory Motor On Normal/Default Direction10b = Accessory Motor On Reverse Direction11b = Don't Care/Ta...";
CM_ SG_ 2558000894 PwrEltrnsClntFn2PrntSpdCmmnd "Power Electronics Coolant Fan 2 Percent Speed Command: Speed command to the Power Electronics Coolant Fan 2 in percentage of maximum speed.Note: Both Speed Command and Percent Speed Command cannot be used at the same time.  Always set the unused spee...";
CM_ SG_ 2558000894 PwrEltrnsClntFn2PwrHld "Power Electronics Coolant Fan 2 Power Hold: Command to allow the Power Electronics Coolant Fan 2 to remain alive independently of the electrical enable input to the Accessory Motor.  For example, this could allow continued device operation after the ...";
CM_ SG_ 2558000894 PwrEltrnsClntFn2SpdCmmnd "Power Electronics Coolant Fan 2 Speed Command: Speed command to the Power Electronics Coolant Fan 2.Note: Both Speed Command and Percent Speed Command cannot be used at the same time.  Always set the unused speed command to Not Available.  If both co...";
CM_ BO_ 2558066430 "Electrified Accessory Power Electronics Coolant Fan 1 Command";
CM_ SG_ 2558066430 PwrEltrnsClntFn1EnlCmmnd "Power Electronics Coolant Fan 1 Enable Command: Enable and direction command to the Power Electonics Coolant Fan 1.00b = Accessory Motor Off01b = Accessory Motor On Normal/Default Direction10b = Accessory Motor On Reverse Direction11b = Don't Care/Ta...";
CM_ SG_ 2558066430 PwrEltrnsClntFn1PrntSpdCmmnd "Power Electronics Coolant Fan 1 Percent Speed Command: Speed command to the Power Electronics Coolant Fan 1 in percentage of maximum speed.Note: Both Speed Command and Percent Speed Command cannot be used at the same time.  Always set the unused spee...";
CM_ SG_ 2558066430 PwrEltrnsClntFn1PwrHld "Power Electronics Coolant Fan 1 Power Hold: Command to allow the Power Electronics Coolant Fan 1 to remain alive independently of the electrical enable input to the Accessory Motor.  For example, this could allow continued device operation after the ...";
CM_ SG_ 2558066430 PwrEltrnsClntFn1SpdCmmnd "Power Electronics Coolant Fan 1 Speed Command: Speed command to the Power Electronics Coolant Fan 1.Note: Both Speed Command and Percent Speed Command cannot be used at the same time.  Always set the unused speed command to Not Available.  If both co...";
CM_ BO_ 2558131966 "Electrified Accessory Propulsion Motor Oil Pump Command";
CM_ SG_ 2558131966 PropulsionMotorOilPumpPowerHold "Propulsion Motor Oil Pump Power Hold: Command to allow the Propulsion Motor Oil Pump to remain alive independently of the electrical enable input to the Accessory Motor.  For example, this could allow continued device operation after the keyswitch ha...";
CM_ SG_ 2558131966 PrplsnMtrOlPmpEnlCmmnd "Propulsion Motor Oil Pump Enable Command: Enable and direction command to the Propulsion Motor Oil Pump.00b = Accessory Motor Off01b = Accessory Motor On Normal/Default Direction10b = Accessory Motor On Reverse Direction11b = Don't Care/Take no actio...";
CM_ SG_ 2558131966 PrplsnMtrOlPmpPrntSpdCmmnd "Propulsion Motor Oil Pump Percent Speed Command: Speed command to the Propulsion Motor Oil Pump in percentage of maximum speed.Note: Both Speed Command and Percent Speed Command cannot be used at the same time.  Always set the unused speed command to...";
CM_ SG_ 2558131966 PrplsnMtrOlPmpSpdCmmnd "Propulsion Motor Oil Pump Speed Command: Speed command to the Propulsion Motor Oil Pump. Note: Both Speed Command and Percent Speed Command cannot be used at the same time.  Always set the unused speed command to Not Available.  If both commands are ...";
CM_ BO_ 2558197502 "Electrified Accessory Propulsion Motor Coolant Pump Command";
CM_ SG_ 2558197502 PrplsnMtrClntPmpEnlCmmnd "Propulsion Motor Coolant Pump Enable Command: Enable and direction command to the Propulsion Motor Coolant Pump.00b = Accessory Motor Off01b = Accessory Motor On Normal/Default Direction10b = Accessory Motor On Reverse Direction11b = Don't Care/Take ...";
CM_ SG_ 2558197502 PrplsnMtrClntPmpPrntSpdCmmnd "Propulsion Motor Coolant Pump Percent Speed Command: Speed command to the Propulsion Motor Coolant Pump in percentage of maximum speed.Note: Both Speed Command and Percent Speed Command cannot be used at the same time.  Always set the unused speed co...";
CM_ SG_ 2558197502 PrplsnMtrClntPmpPwrHld "Propulsion Motor Coolant Pump Power Hold: Command to allow the Propulsion Motor Coolant Pump to remain alive independently of the electrical enable input to the Accessory Motor.  For example, this could allow continued device operation after the keys...";
CM_ SG_ 2558197502 PrplsnMtrClntPmpSpdCmmnd "Propulsion Motor Coolant Pump Speed Command: Speed command to the Propulsion Motor Coolant Pump. Note: Both Speed Command and Percent Speed Command cannot be used at the same time.  Always set the unused speed command to Not Available.  If both comma...";
CM_ BO_ 2558263038 "Electrified Accessory Power Electronics Coolant Pump Command";
CM_ SG_ 2558263038 PwrEltrnsClntPmpEnlCmmnd "Power Electronics Coolant Pump Enable Command: Enable and direction command to the Power Electonics Coolant Pump.00b = Accessory Motor Off01b = Accessory Motor On Normal/Default Direction10b = Accessory Motor On Reverse Direction11b = Don't Care/Take...";
CM_ SG_ 2558263038 PwrEltrnsClntPmpPrntSpdCmmnd "Power Electronics Coolant Pump Percent Speed Command: Speed command to the Power Electronics Coolant Pump in percentage of maximum speed.Note: Both Speed Command and Percent Speed Command cannot be used at the same time.  Always set the unused speed ...";
CM_ SG_ 2558263038 PwrEltrnsClntPmpPwrHld "Power Electronics Coolant Pump Power Hold: Command to allow the Power Electronics Coolant Pump to remain alive independently of the electrical enable input to the Accessory Motor.  For example, this could allow continued device operation after the ke...";
CM_ SG_ 2558263038 PwrEltrnsClntPmpSpdCmmnd "Power Electronics Coolant Pump Speed Command: Speed command to the Power Electronics Coolant Pump.Note: Both Speed Command and Percent Speed Command cannot be used at the same time.  Always set the unused speed command to Not Available.  If both comm...";
CM_ BO_ 2558394110 "Electrified Accessory Motor Command";
CM_ SG_ 2558394110 EltrfdAssrMtrEnlCmmnd "Electrified Accessory Motor Enable Command: Enable and direction command to this electrified Accessory Motor.00b = Accessory Motor Off01b = Accessory Motor On Normal/Default Direction10b = Accessory Motor On Reverse Direction11b = Don't Care/Take no ...";
CM_ SG_ 2558394110 EltrfdAssrMtrPrntSpdCmmnd "Electrified Accessory Motor Percent Speed Command: Speed command to this Electrified Accessory Motor in percentage of maximum speed.Note: Both Speed Command and Percent Speed Command cannot be used at the same time.  Always set the unused speed comma...";
CM_ SG_ 2558394110 EltrfdAssrMtrPwrHld "Electrified Accessory Motor Power Hold: Command to allow this Electrified Accessory Motor to remain alive independently of the electrical enable input to the Accessory Motor.  For example, this could allow continued device operation after the keyswit...";
CM_ SG_ 2558394110 EltrfdAssrMtrSpdCmmnd "Electrified Accessory Motor Speed Command: Speed command to this Electrified Accessory Motor.  Note: Both Speed Command and Percent Speed Command cannot be used at the same time.  Always set the unused speed command to Not Available.If both commands ...";
CM_ SG_ 2558394110 ElectrifiedAccessoryMotor1 "Electrified Accessory Motor 1: Indicates this instance of the Electrified Accessory Motor.  Multiple instances can be controlled with the same command PG by setting each unique instance parameter to 0b.0b = Command applied to this Accessory Motor Ins...";
CM_ SG_ 2558394110 ElectrifiedAccessoryMotor2 "Electrified Accessory Motor 2: Indicates this instance of the Electrified Accessory Motor.  Multiple instances can be controlled with the same command PG by setting each unique instance parameter to 0b.0b = Command applied to this Accessory Motor Ins...";
CM_ SG_ 2558394110 ElectrifiedAccessoryMotor3 "Electrified Accessory Motor 3: Indicates this instance of the Electrified Accessory Motor.  Multiple instances can be controlled with the same command PG by setting each unique instance parameter to 0b.0b = Command applied to this Accessory Motor Ins...";
CM_ SG_ 2558394110 ElectrifiedAccessoryMotor4 "Electrified Accessory Motor 4: Indicates this instance of the Electrified Accessory Motor.  Multiple instances can be controlled with the same command PG by setting each unique instance parameter to 0b.0b = Command applied to this Accessory Motor Ins...";
CM_ SG_ 2558394110 ElectrifiedAccessoryMotor5 "Electrified Accessory Motor 5: Indicates this instance of the Electrified Accessory Motor.  Multiple instances can be controlled with the same command PG by setting each unique instance parameter to 0b.0b = Command applied to this Accessory Motor Ins...";
CM_ SG_ 2558394110 ElectrifiedAccessoryMotor6 "Electrified Accessory Motor 6: Indicates this instance of the Electrified Accessory Motor.  Multiple instances can be controlled with the same command PG by setting each unique instance parameter to 0b.0b = Command applied to this Accessory Motor Ins...";
CM_ SG_ 2558394110 ElectrifiedAccessoryMotor7 "Electrified Accessory Motor 7: Indicates this instance of the Electrified Accessory Motor.  Multiple instances can be controlled with the same command PG by setting each unique instance parameter to 0b.0b = Command applied to this Accessory Motor Ins...";
CM_ SG_ 2558394110 ElectrifiedAccessoryMotor8 "Electrified Accessory Motor 8: Indicates this instance of the Electrified Accessory Motor.  Multiple instances can be controlled with the same command PG by setting each unique instance parameter to 0b.0b = Command applied to this Accessory Motor Ins...";
CM_ SG_ 2558394110 ElectrifiedAccessoryMotor9 "Electrified Accessory Motor 9: Indicates this instance of the Electrified Accessory Motor.  Multiple instances can be controlled with the same command PG by setting each unique instance parameter to 0b.0b = Command applied to this Accessory Motor Ins...";
CM_ SG_ 2558394110 ElectrifiedAccessoryMotor10 "Electrified Accessory Motor 10: Indicates this instance of the Electrified Accessory Motor.  Multiple instances can be controlled with the same command PG by setting each unique instance parameter to 0b.0b = Command applied to this Accessory Motor In...";
CM_ SG_ 2558394110 ElectrifiedAccessoryMotor11 "Electrified Accessory Motor 11: Indicates this instance of the Electrified Accessory Motor.  Multiple instances can be controlled with the same command PG by setting each unique instance parameter to 0b.0b = Command applied to this Accessory Motor In...";
CM_ SG_ 2558394110 ElectrifiedAccessoryMotor12 "Electrified Accessory Motor 12: Indicates this instance of the Electrified Accessory Motor.  Multiple instances can be controlled with the same command PG by setting each unique instance parameter to 0b.0b = Command applied to this Accessory Motor In...";
CM_ SG_ 2558394110 ElectrifiedAccessoryMotor13 "Electrified Accessory Motor 13: Indicates this instance of the Electrified Accessory Motor.  Multiple instances can be controlled with the same command PG by setting each unique instance parameter to 0b.0b = Command applied to this Accessory Motor In...";
CM_ SG_ 2558394110 ElectrifiedAccessoryMotor14 "Electrified Accessory Motor 14: Indicates this instance of the Electrified Accessory Motor.  Multiple instances can be controlled with the same command PG by setting each unique instance parameter to 0b.0b = Command applied to this Accessory Motor In...";
CM_ SG_ 2558394110 ElectrifiedAccessoryMotor15 "Electrified Accessory Motor 15: Indicates this instance of the Electrified Accessory Motor.  Multiple instances can be controlled with the same command PG by setting each unique instance parameter to 0b.0b = Command applied to this Accessory Motor In...";
CM_ BO_ 2558459646 "Engine Speed Ramp Rate Boundary Request";
CM_ SG_ 2558459646 RqstdEngnSpdAlrtnRtLmt "Requested Engine Speed Acceleration Rate Limit: This parameter is intended to be received by a device sending speed commands to an engine (e.g. TSC1 or proprietary command). The sending device should issue speed commands such that this acceleration r...";
CM_ SG_ 2558459646 RqstdEngnSpdDlrtnRtLmt "Requested Engine Speed Deceleration Rate Limit: This parameter is intended to be received by a device sending speed commands to an engine (e.g. TSC1 or proprietary command). The sending device should issue speed commands such that this deceleration r...";
CM_ BO_ 2558525182 "Tire Sensor Identification Command";
CM_ SG_ 2558525182 NumberofTireSensors "Number of Tire Sensors: Total count of monitored tire sensor identification numbers represented in this instance of the parameter group.";
CM_ SG_ 2558525182 TireLocation "Tire Location: The location of monitored tire that corresponds with the tire sensor identification number SPN 7586. In order to specify the monitored tire by tire number, use the tire number SPN 7584.The high order 4 bits indicate the vehicle axle po...";
CM_ SG_ 2558525182 TireNumber "Tire Number: The number of the monitored tire that corresponds with the tire sensor identification number SPN 7586. In order to specify the monitored tire by location, use the tire location SPN 7585.The value FFh indicates this SP is not used.";
CM_ SG_ 2558525182 TireSensorIdentificationNumber "Tire Sensor Identification Number: The identification number of tire sensor for the tire specified in the tire sensor tire number (SPN 7584) or tire sensor location (SPN 7585).";
CM_ BO_ 2558590718 "Hybrid System Control 1";
CM_ SG_ 2558590718 ExtrnlEnrgSrCnntnDmnd "External Energy Source Connection Demand : External Energy Source Connection Demand indicates how the hybrid system should engage with the external energy source that is temporarily connected to the vehicle.This parameter allows for two external ener...";
CM_ SG_ 2558590718 HrdSstmPrplsnDslRqst "Hybrid System Propulsion Disable Request: Indicates the Hybrid System Disable Request state.  The signal gives network controllers the ability to disable the propulsion aspect of hybrid system operation when this request is on.  However, hybrid power...";
CM_ SG_ 2558590718 HrdSstmPrttnOvrrdRqst "Hybrid System Protection Override Request: Indicates the hybrid system protection override request state.  This request allows overriding of hybrid system protection features and failure modes allowing hybrid systems to continue to operate, if possib...";
CM_ SG_ 2558590718 HrdSstmRgnrtvBrkngDslRqst "Hybrid System Regenerative Braking Disable Request: Indicates the hybrid system regenerative braking disable request state.  This signal gives network controllers the ability to disable all regenerative braking.  This is not the operator controlled s...";
CM_ SG_ 2558590718 HybridPropulsionModeRequest "Hybrid Propulsion Mode Request : Hybrid Propulsion Mode Request is the operator intended propulsion mode.  This parameter can be from only one source on the vehicle.  Response to this request can be found in the Hybrid Propulsion Mode Status (SPN 789...";
CM_ SG_ 2558590718 HybridSystemShutdownCommand "Hybrid System Shutdown Command: Indicates the Hybrid System Shutdown Request state.  The signal gives network controllers the ability to disable all hybrid system functionality including propulsion, regenerative braking, and hybrid powered accessorie...";
CM_ SG_ 2558590718 OperatorVehicleModeRequest "Operator Vehicle Mode Request : Operator Vehicle Mode Request is the operator intended vehicle mode.  This parameter can be from only one source on the vehicle.  In the case of a Diesel-Electric Hybrid, the source of this parameter may be a vehicle c...";
CM_ SG_ 2558590718 StrdEnrgSrChrgDshrgRtRqst "Stored Energy Source Charge/Discharge Rate Request: Stored Energy Source Charge/Discharge Rate Request is used to control the rate at which the stored energy is changed in Energy Increasing or Energy Depleting modes.A value of FBh indicates a request...";
CM_ SG_ 2558590718 StrdEnrgSrStPntRqst "Stored Energy Source Set Point Request : Stored Energy Source Set Point Request is used to set the percentage that the Stored Energy Source should be managed to by the system.A value of FBh indicates a request for the default set point.  In the case ...";
CM_ SG_ 2558590718 HVESChargeConsent "HVES Charge Consent: Indicates the sender's consent to charge the system's HVES (high-voltage energy storage) from EVSE (electric vehicle supply equipment), i.e. offboard vehicle charging station.For example, a controller has certain application-spec...";
CM_ SG_ 2558590718 HrdPrplsnMdRqstdMxmmSpd "Hybrid Propulsion Mode Requested Maximum Speed: The requested maximum speed for the vehicle while in a Hybrid Propulsion Mode (see SPN 7889) other than Mode 1 - Stored Energy Source Sustaining.This shall be the operating vehicle speed limit while in ...";
CM_ SG_ 2558590718 HrdPrplsnMdRqstdDstn "Hybrid Propulsion Mode Requested Distance: The requested distance to maintain a Hybrid Propulsion Mode (see SPN 7889) other than Mode 1 - Stored Energy Source Sustaining.When the distance is met, or a protective mode is activated (e.g. HVES charge is...";
CM_ BO_ 2558656254 "Aftertreatment System Control";
CM_ SG_ 2558656254 AftrtrtmntDslExhstFldDsrRdStts "Aftertreatment Diesel Exhaust Fluid Doser Ready Status: Indicates the aftertreatment systems operating conditions are appropriate for dosing.Note: Operating conditions may include but not limited to Diesel Exhaust Fluid tank level and Diesel Exhaust ...";
CM_ SG_ 2558656254 AftrtrtmntSstmEnlStts "Aftertreatment System Enable Status: Indicates that the aftertreatment system is enabled or disabled.  Enabled indicates the system will dose at regular intervals.00b = Aftertreatment System is Disabled01b = Aftertreatment System is Enabled10b = Erro...";
CM_ SG_ 2558656254 AftrtrtmntThrmlMngmntInhtRqst "Aftertreatment Thermal Management Inhibit Request: Provides state of inhibit request for Aftertreatment thermal management from external system.Aftertreatment Thermal Management indicates that the exhaust temperatures have been controlled for expecte...";
CM_ SG_ 2558656254 RqsttPrmtDEFHdrlStffnssChk "Request to Permit DEF Hydraulic Stiffness Check: A request to permit the DEF hydraulic stiffness check. The request continues to be broadcast until the stiffness check is finished or the corresponding permission status indicates an error.00b = no req...";
CM_ SG_ 2558656254 RqsttPrmtSCRDsngTstInjtn "Request to Permit SCR Dosing Test Injection: A request to permit the SCR dosing test injection. The request continues to be broadcast until the test injection is finished or the corresponding permission status indicates an error.000b = No request001b...";
CM_ BO_ 2558721790 "Tire Configuration Command Information";
CM_ SG_ 2558721790 ColdInflationPressureSetting "Cold Inflation Pressure Setting: Configurable value of the cold inflation pressure of the tire. Cold inflation pressure is the default/reference inflation pressure suggested by the manufacturer for a specific tire.";
CM_ SG_ 2558721790 ExtrmUndrPrssrPrntgThrshldSttng "Extreme Under Pressure Percentage Threshold Setting: Configurable percent deviation from the set cold inflation pressure, for the extreme under tire pressure alert.";
CM_ SG_ 2558721790 OverTemperatureSetting "Over Temperature Setting: Configurable constant temperature above which an over temperature alert will trigger.";
CM_ SG_ 2558721790 OvrPrssrPrntgThrshldSttng "Over Pressure Percentage Threshold Setting: Configurable percentage deviation from the set cold inflation pressure, for the over tire pressure alert.";
CM_ SG_ 2558721790 TireLocation "Tire Location: The location of monitored tire on the vehicle.The high order 4 bits indicate the vehicle axle position of the tire, counting front to back on the vehicle, with the value 0 representing the front axle on the vehicle. If the upper 4 bits...";
CM_ SG_ 2558721790 TireSensorEnableSetting "Tire Sensor Enable Setting: Command signal used to enable/disable the tire sensor. On receipt of this command, the tire sensor may either be enabled or disabled.00b = Off / Isolate / Disable01b = On / Enable10b = Reserved / Not Defined11b = Don't Car...";
CM_ SG_ 2558721790 UndrPrssrPrntgThrshldSttng "Under Pressure Percentage Threshold Setting: Configurable percent deviation from the set cold inflation pressure, for the under tire pressure alert.";
CM_ BO_ 2558787326 "Payload Calibration Information Command";
CM_ SG_ 2558787326 PayloadCorrectionFactorCommand "Payload Correction Factor Command: The payload correction factor is used to fine tune the sensor gain value.Correction factor calibration of the Payload Measurement system is performed through a Payload Calibration Set Point SP value of Correction Po...";
CM_ SG_ 2558787326 PldClrtnCmmnddWght "Payload Calibration Commanded Weight: The true known mass of real load weight applicable for the calibration point specified in SPN 6871 and used for calibrating Payload system.Multipoint calibration of the Payload Measurement system is performed by ...";
CM_ SG_ 2558787326 PldClrtnStPntCmmnd "Payload Calibration Set Point Command: Specifies the current payload point being calibrated. The data specified in the 'Payload Calibration Commanded Weight' SP (SPN 6872) or 'Payload Correction Factor Command' SP (SPN 6873) shall be used for calibra...";
CM_ BO_ 2558852862 "Aftertreatment 1 Particulate Sensor Control";
CM_ SG_ 2558852862 Aftrtrtmnt1PrtltSnsrDwpnt "Aftertreatment 1 Particulate Sensor Dewpoint: Indicates that the temperature near the particulate sensor has exceeded the dew point.00b = Dewpoint has not been reached01b = Dewpoint has been reached10b = SAE reserved11b = Not available";
CM_ SG_ 2558852862 Aftrtrtmnt1PrtltSnsrExhstTmprtr "Aftertreatment 1 Particulate Sensor Exhaust Temperature: This is the temperature in the exhaust stream that is closest to the particulate sensor. This could be a calculated value or read from another sensor. The ECU transmitting this message to the p...";
CM_ SG_ 2558852862 Aftrtrtmnt1PrtltSnsrExhstVlt "Aftertreatment 1 Particulate Sensor Exhaust Velocity: Velocity of the exhaust gas near the particulate sensor.";
CM_ SG_ 2558852862 Aftrtrtmnt1PrtltSnsrRgnrtnRqst "Aftertreatment 1 Particulate Sensor Regeneration Request: Another ECU would send this to request that the particulate sensor perform a regeneration of the sensor.  A request would be considered active when this parameter transitions from 00b to 01b.0...";
CM_ SG_ 2558852862 Aftrtrtmnt1PrtltSnsrShtdwnRqst "Aftertreatment 1 Particulate Sensor Shutdown Request: Aftertreatment 1 particulate sensor shutdown request.00b = Shutdown request not active01b = Shutdown request active10b = SAE reserved11b = Not available";
CM_ BO_ 2558918398 "Cab Message 2";
CM_ SG_ 2558918398 ActiveShiftConsoleRequest "Active Shift Console Request: Requests the shift console or shift selector that the operator desires to be active. See SPN 2945 (Active Shift Console Indicator) for feedback on which shift console is currently active.00b = Use Primary Shift Console01...";
CM_ SG_ 2558918398 AftrtrtmntSstmEnlCmmnd "Aftertreatment System Enable Command: Request to enable Aftertreatment system.00b = De-activate Aftertreatment System01b = Activate Aftertreatment System10b = Reserved11b = Don't care/Take no ActionNote: In some marine applications it may be desireab...";
CM_ SG_ 2558918398 AttttRtESpdAwdSwt "Aftertreatment Regeneration Engine Speed Allowed Switch: If this parameter is 01b, then the aftertreatment control system is permitted to perform an aftertreatment regeneration, but the aftertreatment control system is not allowed to take control of ...";
CM_ SG_ 2558918398 ElvtdEngnSpdAllwdSwth "Elevated Engine Speed Allowed Switch: Indicates the state of a switch to indicate the control system is permitted to automatically elevate the engine speed as needed for strategies such as cold mode, aftertreatment regeneration, etc. This is not a di...";
CM_ SG_ 2558918398 EngineFan2RequestedPercentSpeed "Engine Fan 2 Requested Percent Speed: Fan speed of the second fan in the system as a ratio of the actual fan drive (current speed) to the fully engaged fan drive (maximum fan speed). A two state fan (off/on) will use 0% and 100% respectively.  A thre...";
CM_ SG_ 2558918398 EngineStopStartDisableCommand "Engine Stop-Start Disable Command: Engine Stop-Start Disable Command indicates the desire to disable the engine stop-start functionality during propulsion modes. For momentary switches, this parameter does not indicate the state of the switch contact...";
CM_ SG_ 2558918398 EngnIdlMngmntPndngEvntOvrrd "Engine Idle Management Pending Event Override: Command signal which allows the operator to override an impending engine idle management start-up or an impending engine idle management shutdown.00b = Off (not requesting an override)01b = On (requestin...";
CM_ SG_ 2558918398 HtExhngrDrsPrgFrSwth "Heat Exchanger Debris Purge Force Switch: Indicates the state of a switch available to the operator that forces the system to purge the debris from the heat exchanger.00b = not active01b = active10b = error11b = not availableThis SP would be not acti...";
CM_ SG_ 2558918398 HtExhngrDrsPrgInhtSwth "Heat Exchanger Debris Purge Inhibit Switch: Indicates the state of a switch available to the operator that will inhibit the system from purging the debris from the heat exchanger.00b = not active01b = active10b = error11b = not availableThis SP would...";
CM_ SG_ 2558918398 PerformanceBiasSelection "Performance Bias Selection: Indicates the operating bias toward performance of the power source.For values between 0% and 50%, functionality is biased toward fuel economy, with values closer to 0% indicating more bias toward fuel economy.50% Function...";
CM_ SG_ 2558918398 PrdtvCrsCntrlDtvtnRqst "Predictive Cruise Control Deactivation Request: Indicates that the operator has requested to deactivate the predictive cruise control (PCC) function.If enabled, the PCC device may still provide notification of events in range, road grade, and other i...";
CM_ SG_ 2558918398 PrdtvCrsCntrlEnlSwth "Predictive Cruise Control Enable Switch: Indicates whether predictive cruise control (PCC) is enabled. When not enabled, the predictive cruise control does not calculate a speed offset or identify predictive cruise events, and the predictive cruise c...";
CM_ SG_ 2558918398 PrdtvCrsCntrlMxmmNgtvOffst "Predictive Cruise Control Maximum Negative Offset: Maximum speed decrease that the predictive cruise control (PCC) is allowed to request. This may be adjusted by the operator (either directly or indirectly) to tailor the performance of the PCC system...";
CM_ SG_ 2558918398 PrdtvCrsCntrlMxmmPstvOffst "Predictive Cruise Control Maximum Positive Offset: Maximum speed increase that the predictive cruise control (PCC) is allowed to request. This may be adjusted by the operator (either directly or indirectly) to tailor the performance of the PCC system...";
CM_ SG_ 2558918398 SCROprtrIndmntOvrrdSwth "SCR Operator Inducement Override Switch: The position of the operator inducement override switch. This switch function allows the operator to override an operator inducement derate.See EU Commission directive 2012/46/EU. Appendix 1 Section 5.5 for mo...";
CM_ SG_ 2558918398 TrnsmssnAtNtrlMnlRtrnEnlSwth "Transmission Auto-Neutral (Manual Return) Enable Switch: This enable switch is for optional use with interfaces using SPN 7695 [Transmission Auto-Neutral (Manual Return) Request] or another vehicle input configured for Auto-Neutral (Manual Return) fu...";
CM_ SG_ 2558918398 VehicleHoodSwitch "Vehicle Hood Switch: Switch used to indicate the vehicle hood is open or closed.00b = Vehicle hood is closed01b = Vehicle hood is open10b = Error11b = Not available";
CM_ BO_ 2558983934 "Switched Power Outputs Command";
CM_ SG_ 2558983934 SwitchedPowerOutput10Command "Switched Power Output #10 Command: Desired state of Switched Power Output #10. Used to set the desired state.00b = Output off01b = Output on10b = Reserved11b = Take no action";
CM_ SG_ 2558983934 SwitchedPowerOutput11Command "Switched Power Output #11 Command: Desired state of Switched Power Output #11. Used to set the desired state.00b = Output off01b = Output on10b = Reserved11b = Take no action";
CM_ SG_ 2558983934 SwitchedPowerOutput12Command "Switched Power Output #12 Command: Desired state of Switched Power Output #12. Used to set the desired state.00b = Output off01b = Output on10b = Reserved11b = Take no action";
CM_ SG_ 2558983934 SwitchedPowerOutput13Command "Switched Power Output #13 Command: Desired state of Switched Power Output #13. Used to set the desired state.00b = Output off01b = Output on10b = Reserved11b = Take no action";
CM_ SG_ 2558983934 SwitchedPowerOutput14Command "Switched Power Output #14 Command: Desired state of Switched Power Output #14. Used to set the desired state.00b = Output off01b = Output on10b = Reserved11b = Take no action";
CM_ SG_ 2558983934 SwitchedPowerOutput15Command "Switched Power Output #15 Command: Desired state of Switched Power Output #15. Used to set the desired state.00b = Output off01b = Output on10b = Reserved11b = Take no action";
CM_ SG_ 2558983934 SwitchedPowerOutput16Command "Switched Power Output #16 Command: Desired state of Switched Power Output #16. Used to set the desired state.00b = Output off01b = Output on10b = Reserved11b = Take no action";
CM_ SG_ 2558983934 SwitchedPowerOutput17Command "Switched Power Output #17 Command: Desired state of Switched Power Output #17. Used to set the desired state.00b = Output off01b = Output on10b = Reserved11b = Take no action";
CM_ SG_ 2558983934 SwitchedPowerOutput18Command "Switched Power Output #18 Command: Desired state of Switched Power Output #18. Used to set the desired state.00b = Output off01b = Output on10b = Reserved11b = Take no action";
CM_ SG_ 2558983934 SwitchedPowerOutput19Command "Switched Power Output #19 Command: Desired state of Switched Power Output #19. Used to set the desired state.00b = Output off01b = Output on10b = Reserved11b = Take no action";
CM_ SG_ 2558983934 SwitchedPowerOutput1Command "Switched Power Output #1 Command: Desired state of Switched Power Output #1. Used to set the desired state.00b = Output off01b = Output on10b = Reserved11b = Take no action";
CM_ SG_ 2558983934 SwitchedPowerOutput20Command "Switched Power Output #20 Command: Desired state of Switched Power Output #20. Used to set the desired state.00b = Output off01b = Output on10b = Reserved11b = Take no action";
CM_ SG_ 2558983934 SwitchedPowerOutput21Command "Switched Power Output #21 Command: Desired state of Switched Power Output #21. Used to set the desired state.00b = Output off01b = Output on10b = Reserved11b = Take no action";
CM_ SG_ 2558983934 SwitchedPowerOutput22Command "Switched Power Output #22 Command: Desired state of Switched Power Output #22. Used to set the desired state.00b = Output off01b = Output on10b = Reserved11b = Take no action";
CM_ SG_ 2558983934 SwitchedPowerOutput23Command "Switched Power Output #23 Command: Desired state of Switched Power Output #23. Used to set the desired state.00b = Output off01b = Output on10b = Reserved11b = Take no action";
CM_ SG_ 2558983934 SwitchedPowerOutput24Command "Switched Power Output #24 Command: Desired state of Switched Power Output #24. Used to set the desired state.00b = Output off01b = Output on10b = Reserved11b = Take no action";
CM_ SG_ 2558983934 SwitchedPowerOutput25Command "Switched Power Output #25 Command: Desired state of Switched Power Output #25. Used to set the desired state.00b = Output off01b = Output on10b = Reserved11b = Take no action";
CM_ SG_ 2558983934 SwitchedPowerOutput26Command "Switched Power Output #26 Command: Desired state of Switched Power Output #26. Used to set the desired state.00b = Output off01b = Output on10b = Reserved11b = Take no action";
CM_ SG_ 2558983934 SwitchedPowerOutput27Command "Switched Power Output #27 Command: Desired state of Switched Power Output #27. Used to set the desired state.00b = Output off01b = Output on10b = Reserved11b = Take no action";
CM_ SG_ 2558983934 SwitchedPowerOutput28Command "Switched Power Output #28 Command: Desired state of Switched Power Output #28. Used to set the desired state.00b = Output off01b = Output on10b = Reserved11b = Take no action";
CM_ SG_ 2558983934 SwitchedPowerOutput29Command "Switched Power Output #29 Command: Desired state of Switched Power Output #29. Used to set the desired state.00b = Output off01b = Output on10b = Reserved11b = Take no action";
CM_ SG_ 2558983934 SwitchedPowerOutput2Command "Switched Power Output #2 Command: Desired state of Switched Power Output #2. Used to set the desired state.00b = Output off01b = Output on10b = Reserved11b = Take no action";
CM_ SG_ 2558983934 SwitchedPowerOutput30Command "Switched Power Output #30 Command: Desired state of Switched Power Output #30. Used to set the desired state.00b = Output off01b = Output on10b = Reserved11b = Take no action";
CM_ SG_ 2558983934 SwitchedPowerOutput31Command "Switched Power Output #31 Command: Desired state of Switched Power Output #31. Used to set the desired state.00b = Output off01b = Output on10b = Reserved11b = Take no action";
CM_ SG_ 2558983934 SwitchedPowerOutput32Command "Switched Power Output #32 Command: Desired state of Switched Power Output #32. Used to set the desired state.00b = Output off01b = Output on10b = Reserved11b = Take no action";
CM_ SG_ 2558983934 SwitchedPowerOutput3Command "Switched Power Output #3 Command: Desired state of Switched Power Output #3. Used to set the desired state.00b = Output off01b = Output on10b = Reserved11b = Take no action";
CM_ SG_ 2558983934 SwitchedPowerOutput4Command "Switched Power Output #4 Command: Desired state of Switched Power Output #4. Used to set the desired state.00b = Output off01b = Output on10b = Reserved11b = Take no action";
CM_ SG_ 2558983934 SwitchedPowerOutput5Command "Switched Power Output #5 Command: Desired state of Switched Power Output #5. Used to set the desired state.00b = Output off01b = Output on10b = Reserved11b = Take no action";
CM_ SG_ 2558983934 SwitchedPowerOutput6Command "Switched Power Output #6 Command: Desired state of Switched Power Output #6. Used to set the desired state.00b = Output off01b = Output on10b = Reserved11b = Take no action";
CM_ SG_ 2558983934 SwitchedPowerOutput7Command "Switched Power Output #7 Command: Desired state of Switched Power Output #7. Used to set the desired state.00b = Output off01b = Output on10b = Reserved11b = Take no action";
CM_ SG_ 2558983934 SwitchedPowerOutput8Command "Switched Power Output #8 Command: Desired state of Switched Power Output #8. Used to set the desired state.00b = Output off01b = Output on10b = Reserved11b = Take no action";
CM_ SG_ 2558983934 SwitchedPowerOutput9Command "Switched Power Output #9 Command: Desired state of Switched Power Output #9. Used to set the desired state.00b = Output off01b = Output on10b = Reserved11b = Take no action";
CM_ BO_ 2559049470 "Engine State Requests";
CM_ SG_ 2559049470 DesiredEngineFuelingState "Desired Engine Fueling State: Devices send this request to the engine controller to:(a) Shut off engine fueling, but remain prepared to re-start quickly by not shutting down the control system, or(b) Keep the engine running.00b = Fueling not desired ...";
CM_ SG_ 2559049470 EngineFuelingDesiredReason "Engine Fueling Desired Reason: This parameter conveys the reason a device wants the engine running.This SP is intended to be used in conjunction with Desired Engine Fueling State (SPN 5793). When a device sends Desired Engine Fueling State = Fueling ...";
CM_ SG_ 2559049470 EngineFuelingNotDesiredReason "Engine Fueling Not Desired Reason: This parameter conveys the reason a device wants the engine to inhibit fueling. This SP is intended to be used in conjunction with Desired Engine Fueling State (SPN 5793). When a device sends Desired Engine Fueling ...";
CM_ SG_ 2559049470 EngineGaseousFuelUsageInhibited "Engine Gaseous Fuel Usage Inhibited: Used to request that the engine should not be allowed to use gaseous fuel for engine cylinder combustion. This state is relevant for dual fuel systems and would be used when conditions are detected that make it un...";
CM_ SG_ 2559049470 EngineShutdownCommand "Engine Shutdown Command: Command to shut down the engine. If this parameter is received as 01b, then the engine should behave as if the key switch was turned off. An example of how this parameter could be used is an ECU would send 01b for this parame...";
CM_ SG_ 2559049470 EngnGssFlSpplDsrdPrssr "Engine Gaseous Fuel Supply Desired Pressure: Desired gage pressure of gaseous fuel supply to the engine.";
CM_ SG_ 2559049470 EngnPrttnDrtOvrrdCmmnd "Engine Protection Derate Override Command: Command signal to override engine protection derate.This is to temporarily override an engine protection derate due to coolant temperature, oil pressure etc. This is for applications such as fire, rescue, an...";
CM_ SG_ 2559049470 RequestedFuelType "Requested Fuel Type: Engine controller receives this request from another control module to select the type of fuel to be used for engine operation.00h = Not available - NONE01h = Gasoline/petrol - GAS02h = Methanol - METH03h = Ethanol - ETH04h = Die...";
CM_ SG_ 2559049470 TrnsmssnIdlGvrnrFlngInht "Transmission Idle Governor Fueling Inhibit: This parameter is a command provided to the Engine Control Module (ECM) from the Transmission Control Module (TCM) to inhibit idle governor fueling in the unlikely event that transmission has detected a fai...";
CM_ BO_ 2559115006 "Radio Beacon Request";
CM_ SG_ 2559115006 RadioBeaconDirection "Radio Beacon Direction: Indicates the function of a particular instance of the Radio Beacon Request message. The 'Beacon Request' state indicates the message is sent to a wireless transceiver to request a transmit of the special beacon message. The '...";
CM_ SG_ 2559115006 TransmitterID2 "Transmitter ID 2: The ID of the off-board transmitter that sent the incoming special beacon message received by the wireless transceiver.";
CM_ SG_ 2559115006 UnqBnMssgIdntfrNmr "Unique Beacon Message Identifier Number: The number is used to identify a wireless message originating from a device on a particular machine. Within a beacon request message (see SPN 5755 [Radio Beacon Direction]), this number is included in the tran...";
CM_ SG_ 2559115006 WirelessSignalStrength2 "Wireless Signal Strength 2: The absolute received signal strength of the special beacon signal received from the off-board transmitter. The signal strength is reported as a Received Signal Strength Indicator (RSSI) value in dBm. This measurement meth...";
CM_ BO_ 2559573758 "Engine Configuration Commands";
CM_ SG_ 2559573758 CtLvEPttStdwOvdCd "Coolant Level Engine Protection Shutdown Override Command: Overrides the engine protection shutdown functionality due to low coolant level.  00b = Disable engine protection shutdown override due to low coolant level01b = Enable engine protection shut...";
CM_ BO_ 2559639294 "Supplemental Fan Command";
CM_ SG_ 2559639294 SupplementalFanDirectionCommand "Supplemental Fan Direction Command: Direction command to the Supplemental Fan. Fan can be commanded to run forward or reverse.00b = Forward01b = Reverse10b = Reserved11b = Don't care/take no action (leave function as is)";
CM_ SG_ 2559639294 SupplementalFanEnableCommand "Supplemental Fan Enable Command: Enable/Disable command to Supplemental Fan.00b = Disable 01b = Enable10b = Reserved 11b = Don't Care/Take no action";
CM_ SG_ 2559639294 SupplementalFanPowerHold "Supplemental Fan Power Hold: Command to allow the supplemental fan controller to remain alive independently of the electrical enable input to the fan. This allows the fan controller to remain alive after the key switch has disabled the electrical ena...";
CM_ SG_ 2559639294 SupplementalFanSpeedCommand "Supplemental Fan Speed Command: Speed command to Supplemental Fan.";
CM_ BO_ 2559704830 "Vehicle/Chassis Lubrication System 1";
CM_ SG_ 2559704830 LrtnOprtnMdStCmmnd "Lubrication Operation Mode Set Command: Command signal to change lubrication system operational mode. The mode set command gives the operator and/or technician the ability to change the operational mode when diagnosing and servicing of the system is ...";
CM_ SG_ 2559704830 LubricationCycleModeLockCommand "Lubrication Cycle Mode Lock Command: Command signal to lock or unlock the ability to change the lubrication cycle mode.  Locking the lubrication mode would prevent the changing of the lubrication cycle mode, perhaps by an operator.00b = Not Locked01b...";
CM_ SG_ 2559704830 LubricationCycleSetCommand "Lubrication Cycle Set Command: Command signal to change the lubrication cycle. It gives the operator or technician the ability to the change the frequency of lubrication.000b = Cycle mode # 1 (Lowest Lubrication Frequency)001b = Cycle mode # 2010b = ...";
CM_ SG_ 2559704830 LubricationPumpEnableCommand "Lubrication Pump Enable Command: Command signal to reset the lubrication pump.  It allows the operator and/or technician to reset the paused lubrication pump and clear lubrication system faults. This shall enable the lubrication system to resume its ...";
CM_ SG_ 2559704830 LubricationTimingCycleCommand "Lubrication Timing Cycle Command: Command signal to enable or pause the lubrication activation clock 00b = Pause01b = Enable10b = Reserved 11b = Take no action     Note:  In some vehicles or machines the lubrication is only required when the vehicle ...";
CM_ BO_ 2559770366 "Aftertreatment 1 Hydrocarbon Doser Information 1";
CM_ SG_ 2559770366 DiagnosticStatusofHCDoser "Diagnostic Status of HC Doser: Indicates whether an error is active in the Hydrocarbon Doser (HCD) or whether the internal cyclic system test of the HCD is presently active.  This is not intended to replace the DM8/DM30 - Test results requirement for...";
CM_ SG_ 2559770366 HCDoserInjectingStatus "HC Doser Injecting Status: Indicates whether the Hydrocarbon Doser (HCD) is presently injecting diesel fuel into the exhaust pipe.00b = Injecting not active01b = Injecting active10b = Error11b = Not available";
CM_ SG_ 2559770366 HCDoserStatus "HC Doser Status: Indicates whether the HC Doser/ HC Dosing system is enabled or is waiting for regeneration.000b = HC doser disabled001b = HC doser active010b = SAE reserved011b = HC doser enabled, waiting for regeneration100b = SAE reserved101b = SA...";
CM_ SG_ 2559770366 HydrocarbonDoserPurgingRequired "Hydrocarbon Doser Purging Required: Purging of the Hydrocarbon Doser (HCD) is required.  Request could come from the HCD system.00b = Purging not required01b = Purging required - less urgent10b = Purging required - urgent11b = Not available";
CM_ SG_ 2559770366 RequestedFuelMassRate "Requested Fuel Mass Rate: Requested fuel dosing quantity from hydrocarbon doser.";
CM_ SG_ 2559770366 Aftertreatment1DPFHydrocarbon "Aftertreatment 1 DPF Hydrocarbon: Accumulated unburned fuel in the DPF.  0% = no unburned fuel in DPF, 100% = maximum recommended capacity of unburned fuel in DPF.";
CM_ BO_ 2559901438 "Aftertreatment 1 Diesel Particulate Filter Soot Sensor Calibration";
CM_ SG_ 2559901438 Atttt1DsPttFtStMCtOst "Aftertreatment 1 Diesel Particulate Filter Soot Mean Calibration Offset: Calibration offset for the soot Mean for Aftertreatment 1 Diesel Particulate Filter soot sensor.";
CM_ SG_ 2559901438 Atttt1DsPttFtStStddDvtCtOst "Aftertreatment 1 Diesel Particulate Filter Soot Standard Deviation Calibration Offset: Calibration offset for the soot standard deviation for Aftertreatment 1 Diesel Particulate Filter soot sensor.";
CM_ BO_ 2559966974 "Aftertreatment 2 Diesel Particulate Filter Soot Sensor Calibration";
CM_ SG_ 2559966974 Atttt2DsPttFtStMCtOst "Aftertreatment 2 Diesel Particulate Filter Soot Mean Calibration Offset: Calibration offset for the soot Mean for Aftertreatment 2 Diesel Particulate Filter soot sensor.";
CM_ SG_ 2559966974 Atttt2DsPttFtStStddDvtCtOst "Aftertreatment 2 Diesel Particulate Filter Soot Standard Deviation Calibration Offset: Calibration offset for the soot standard deviation for Aftertreatment 2 Diesel Particulate Filter soot sensor.";
CM_ BO_ 2560032510 "Low Voltage Disconnect Set Operating Mode";
CM_ SG_ 2560032510 LwVltgDsnntDsrdOprtngMd "Low Voltage Disconnect Desired Operating Mode: Desired Operating Mode of the LVD.  Used to issue a J1939 request to the LVD to change modes.0000b = Automatic0001b to 0011b = Reserved0100b = Manual Disconnect0101b = Manual Connect0110b to 1110b = Rese...";
CM_ BO_ 2560098046 "Noise Control Status";
CM_ SG_ 2560098046 CabNoiseControlStatus "Cab Noise Control Status: This parameter returns the current status of the Cab Noise Control system.00b = Cab Noise Control System ON-Line01b = Cab Noise Control System OFF-Line10b = Error Indicator11b = Not Available/Not Requested";
CM_ SG_ 2560098046 CabNoiseControlTuningStatus "Cab Noise Control Tuning Status: This parameter returns the current status of tuning function of the Cab Noise Control system.    When the tuning state is active, the Cab Noise Control System adjusts certain system characteristics (e.g. to account fo...";
CM_ BO_ 2560163582 "Noise Control 1";
CM_ SG_ 2560163582 CabNoiseControlCommand "Cab Noise Control Command: Command signal to change the state of the Cab Noise Control System to on-line or off-line00b = Take Cab Noise Control System Off Line01b = Bring Cab Noise Control System On Line10b = Reserved11b = Don't Care/Not Commanded...";
CM_ SG_ 2560163582 CabNoiseControlTuningCommand "Cab Noise Control Tuning Command: Command values for the Tuning State of the Cab Noise Control System.  The Tuning State allows the Cab Noise Control System to adjust certain system characteristics (e.g. to account for microphone or speaker degradati...";
CM_ BO_ 2560360190 "Proprietary Method Identification";
CM_ SG_ 2560360190 DataDictionaryManufacturerCode "Data Dictionary Manufacturer Code: The J1939 Manufacturer Code (see J1939 Table B10) associated with the manufacturer who defined the proprietary communications method.  7FFh reserved for Not Available";
CM_ SG_ 2560360190 DataDictionaryMethod "Data Dictionary Method: A manufacturer defined code to define the proprietary communications method.  The structure and interpretation of the code is manufacturer specific.  This allows manufacturers to establish their own methods for reporting propr...";
CM_ BO_ 2560425726 "Auxiliary Input/Output Status 7";
CM_ SG_ 2560425726 AuxiliaryIOChannel15 "Auxiliary I/O Channel #15: Identifies the current value of auxiliary input/output channels that are configured uniquely per application.";
CM_ SG_ 2560425726 AuxiliaryIOChannel16 "Auxiliary I/O Channel #16: Identifies the current value of auxiliary input/output channels that are configured uniquely per application.";
CM_ SG_ 2560425726 AuxiliaryIOChannel17 "Auxiliary I/O Channel #17: Identifies the current value of auxiliary input/output channels that are configured uniquely per application.";
CM_ SG_ 2560425726 AuxiliaryIOChannel18 "Auxiliary I/O Channel #18: Identifies the current value of auxiliary input/output channels that are configured uniquely per application.";
CM_ SG_ 2560425726 AuxiliaryIOChannel19 "Auxiliary I/O Channel #19: Identifies the current value of auxiliary input/output channels that are configured uniquely per application.";
CM_ SG_ 2560425726 AuxiliaryIOChannel20 "Auxiliary I/O Channel #20: Identifies the current value of auxiliary input/output channels that are configured uniquely per application.";
CM_ SG_ 2560425726 AuxiliaryIOChannel21 "Auxiliary I/O Channel #21: Identifies the current value of auxiliary input/output channels that are configured uniquely per application.";
CM_ SG_ 2560425726 AuxiliaryIOChannel22 "Auxiliary I/O Channel #22: Identifies the current value of auxiliary input/output channels that are configured uniquely per application.";
CM_ BO_ 2560491262 "Auxiliary Input/Output Status 6";
CM_ SG_ 2560491262 AuxiliaryIOChannel10 "Auxiliary I/O Channel #10: Identifies the current value of auxiliary input/output channels that are configured uniquely per application.";
CM_ SG_ 2560491262 AuxiliaryIOChannel11 "Auxiliary I/O Channel #11: Identifies the current value of auxiliary input/output channels that are configured uniquely per application.";
CM_ SG_ 2560491262 AuxiliaryIOChannel12 "Auxiliary I/O Channel #12: Identifies the current value of auxiliary input/output channels that are configured uniquely per application.";
CM_ SG_ 2560491262 AuxiliaryIOChannel13 "Auxiliary I/O Channel #13: Identifies the current value of auxiliary input/output channels that are configured uniquely per application.";
CM_ SG_ 2560491262 AuxiliaryIOChannel14 "Auxiliary I/O Channel #14: Identifies the current value of auxiliary input/output channels that are configured uniquely per application.";
CM_ SG_ 2560491262 AuxiliaryIOChannel7 "Auxiliary I/O Channel #7: Identifies the current value of auxiliary input/output channels that are configured uniquely per application.";
CM_ SG_ 2560491262 AuxiliaryIOChannel8 "Auxiliary I/O Channel #8: Identifies the current value of auxiliary input/output channels that are configured uniquely per application.";
CM_ SG_ 2560491262 AuxiliaryIOChannel9 "Auxiliary I/O Channel #9: Identifies the current value of auxiliary input/output channels that are configured uniquely per application.";
CM_ BO_ 2561015550 "Auxiliary Input/Output Status 4";
CM_ SG_ 2561015550 AuxiliaryIO100 "Auxiliary I/O #100: Identifies the current status of auxiliary input/output functions that are configured uniquely per application.00b = Auxiliary channel off01b = Auxiliary channel on10b = Error Indicator or Not Used , depending on application11b = ...";
CM_ SG_ 2561015550 AuxiliaryIO101 "Auxiliary I/O #101: Identifies the current status of auxiliary input/output functions that are configured uniquely per application.00b = Auxiliary channel off01b = Auxiliary channel on10b = Error Indicator or Not Used , depending on application11b = ...";
CM_ SG_ 2561015550 AuxiliaryIO102 "Auxiliary I/O #102: Identifies the current status of auxiliary input/output functions that are configured uniquely per application.00b = Auxiliary channel off01b = Auxiliary channel on10b = Error Indicator or Not Used , depending on application11b = ...";
CM_ SG_ 2561015550 AuxiliaryIO103 "Auxiliary I/O #103: Identifies the current status of auxiliary input/output functions that are configured uniquely per application.00b = Auxiliary channel off01b = Auxiliary channel on10b = Error Indicator or Not Used , depending on application11b = ...";
CM_ SG_ 2561015550 AuxiliaryIO104 "Auxiliary I/O #104: Identifies the current status of auxiliary input/output functions that are configured uniquely per application.00b = Auxiliary channel off01b = Auxiliary channel on10b = Error Indicator or Not Used , depending on application11b = ...";
CM_ SG_ 2561015550 AuxiliaryIO105 "Auxiliary I/O #105: Identifies the current status of auxiliary input/output functions that are configured uniquely per application.00b = Auxiliary channel off01b = Auxiliary channel on10b = Error Indicator or Not Used , depending on application11b = ...";
CM_ SG_ 2561015550 AuxiliaryIO106 "Auxiliary I/O #106: Identifies the current status of auxiliary input/output functions that are configured uniquely per application.00b = Auxiliary channel off01b = Auxiliary channel on10b = Error Indicator or Not Used , depending on application11b = ...";
CM_ SG_ 2561015550 AuxiliaryIO107 "Auxiliary I/O #107: Identifies the current status of auxiliary input/output functions that are configured uniquely per application.00b = Auxiliary channel off01b = Auxiliary channel on10b = Error Indicator or Not Used , depending on application11b = ...";
CM_ SG_ 2561015550 AuxiliaryIO108 "Auxiliary I/O #108: Identifies the current status of auxiliary input/output functions that are configured uniquely per application.00b = Auxiliary channel off01b = Auxiliary channel on10b = Error Indicator or Not Used , depending on application11b = ...";
CM_ SG_ 2561015550 AuxiliaryIO109 "Auxiliary I/O #109: Identifies the current status of auxiliary input/output functions that are configured uniquely per application.00b = Auxiliary channel off01b = Auxiliary channel on10b = Error Indicator or Not Used , depending on application11b = ...";
CM_ SG_ 2561015550 AuxiliaryIO110 "Auxiliary I/O #110: Identifies the current status of auxiliary input/output functions that are configured uniquely per application.00b = Auxiliary channel off01b = Auxiliary channel on10b = Error Indicator or Not Used , depending on application11b = ...";
CM_ SG_ 2561015550 AuxiliaryIO111 "Auxiliary I/O #111: Identifies the current status of auxiliary input/output functions that are configured uniquely per application.00b = Auxiliary channel off01b = Auxiliary channel on10b = Error Indicator or Not Used , depending on application11b = ...";
CM_ SG_ 2561015550 AuxiliaryIO112 "Auxiliary I/O #112: Identifies the current status of auxiliary input/output functions that are configured uniquely per application.00b = Auxiliary channel off01b = Auxiliary channel on10b = Error Indicator or Not Used , depending on application11b = ...";
CM_ SG_ 2561015550 AuxiliaryIO81 "Auxiliary I/O #81: Identifies the current status of auxiliary input/output functions that are configured uniquely per application.00b = Auxiliary channel off01b = Auxiliary channel on10b = Error Indicator or Not Used , depending on application11b = N...";
CM_ SG_ 2561015550 AuxiliaryIO82 "Auxiliary I/O #82: Identifies the current status of auxiliary input/output functions that are configured uniquely per application.00b = Auxiliary channel off01b = Auxiliary channel on10b = Error Indicator or Not Used , depending on application11b = N...";
CM_ SG_ 2561015550 AuxiliaryIO83 "Auxiliary I/O #83: Identifies the current status of auxiliary input/output functions that are configured uniquely per application.00b = Auxiliary channel off01b = Auxiliary channel on10b = Error Indicator or Not Used , depending on application11b = N...";
CM_ SG_ 2561015550 AuxiliaryIO84 "Auxiliary I/O #84: Identifies the current status of auxiliary input/output functions that are configured uniquely per application.00b = Auxiliary channel off01b = Auxiliary channel on10b = Error Indicator or Not Used , depending on application11b = N...";
CM_ SG_ 2561015550 AuxiliaryIO85 "Auxiliary I/O #85: Identifies the current status of auxiliary input/output functions that are configured uniquely per application.00b = Auxiliary channel off01b = Auxiliary channel on10b = Error Indicator or Not Used , depending on application11b = N...";
CM_ SG_ 2561015550 AuxiliaryIO86 "Auxiliary I/O #86: Identifies the current status of auxiliary input/output functions that are configured uniquely per application.00b = Auxiliary channel off01b = Auxiliary channel on10b = Error Indicator or Not Used , depending on application11b = N...";
CM_ SG_ 2561015550 AuxiliaryIO87 "Auxiliary I/O #87: Identifies the current status of auxiliary input/output functions that are configured uniquely per application.00b = Auxiliary channel off01b = Auxiliary channel on10b = Error Indicator or Not Used , depending on application11b = N...";
CM_ SG_ 2561015550 AuxiliaryIO88 "Auxiliary I/O #88: Identifies the current status of auxiliary input/output functions that are configured uniquely per application.00b = Auxiliary channel off01b = Auxiliary channel on10b = Error Indicator or Not Used , depending on application11b = N...";
CM_ SG_ 2561015550 AuxiliaryIO89 "Auxiliary I/O #89: Identifies the current status of auxiliary input/output functions that are configured uniquely per application.00b = Auxiliary channel off01b = Auxiliary channel on10b = Error Indicator or Not Used , depending on application11b = N...";
CM_ SG_ 2561015550 AuxiliaryIO90 "Auxiliary I/O #90: Identifies the current status of auxiliary input/output functions that are configured uniquely per application.00b = Auxiliary channel off01b = Auxiliary channel on10b = Error Indicator or Not Used , depending on application11b = N...";
CM_ SG_ 2561015550 AuxiliaryIO91 "Auxiliary I/O #91: Identifies the current status of auxiliary input/output functions that are configured uniquely per application.00b = Auxiliary channel off01b = Auxiliary channel on10b = Error Indicator or Not Used , depending on application11b = N...";
CM_ SG_ 2561015550 AuxiliaryIO92 "Auxiliary I/O #92: Identifies the current status of auxiliary input/output functions that are configured uniquely per application.00b = Auxiliary channel off01b = Auxiliary channel on10b = Error Indicator or Not Used , depending on application11b = N...";
CM_ SG_ 2561015550 AuxiliaryIO93 "Auxiliary I/O #93: Identifies the current status of auxiliary input/output functions that are configured uniquely per application.00b = Auxiliary channel off01b = Auxiliary channel on10b = Error Indicator or Not Used , depending on application11b = N...";
CM_ SG_ 2561015550 AuxiliaryIO94 "Auxiliary I/O #94: Identifies the current status of auxiliary input/output functions that are configured uniquely per application.00b = Auxiliary channel off01b = Auxiliary channel on10b = Error Indicator or Not Used , depending on application11b = N...";
CM_ SG_ 2561015550 AuxiliaryIO95 "Auxiliary I/O #95: Identifies the current status of auxiliary input/output functions that are configured uniquely per application.00b = Auxiliary channel off01b = Auxiliary channel on10b = Error Indicator or Not Used , depending on application11b = N...";
CM_ SG_ 2561015550 AuxiliaryIO96 "Auxiliary I/O #96: Identifies the current status of auxiliary input/output functions that are configured uniquely per application.00b = Auxiliary channel off01b = Auxiliary channel on10b = Error Indicator or Not Used , depending on application11b = N...";
CM_ SG_ 2561015550 AuxiliaryIO97 "Auxiliary I/O #97: Identifies the current status of auxiliary input/output functions that are configured uniquely per application.00b = Auxiliary channel off01b = Auxiliary channel on10b = Error Indicator or Not Used , depending on application11b = N...";
CM_ SG_ 2561015550 AuxiliaryIO98 "Auxiliary I/O #98: Identifies the current status of auxiliary input/output functions that are configured uniquely per application.00b = Auxiliary channel off01b = Auxiliary channel on10b = Error Indicator or Not Used , depending on application11b = N...";
CM_ SG_ 2561015550 AuxiliaryIO99 "Auxiliary I/O #99: Identifies the current status of auxiliary input/output functions that are configured uniquely per application.00b = Auxiliary channel off01b = Auxiliary channel on10b = Error Indicator or Not Used , depending on application11b = N...";
CM_ BO_ 2561081086 "Auxiliary Input/Output Status 3";
CM_ SG_ 2561081086 AuxiliaryIO49 "Auxiliary I/O #49: Identifies the current status of auxiliary input/output functions that are configured uniquely per application.00b = Auxiliary channel off01b = Auxiliary channel on10b = Error Indicator or Not Used , depending on application11b = N...";
CM_ SG_ 2561081086 AuxiliaryIO50 "Auxiliary I/O #50: Identifies the current status of auxiliary input/output functions that are configured uniquely per application.00b = Auxiliary channel off01b = Auxiliary channel on10b = Error Indicator or Not Used , depending on application11b = N...";
CM_ SG_ 2561081086 AuxiliaryIO51 "Auxiliary I/O #51: Identifies the current status of auxiliary input/output functions that are configured uniquely per application.00b = Auxiliary channel off01b = Auxiliary channel on10b = Error Indicator or Not Used , depending on application11b = N...";
CM_ SG_ 2561081086 AuxiliaryIO52 "Auxiliary I/O #52: Identifies the current status of auxiliary input/output functions that are configured uniquely per application.00b = Auxiliary channel off01b = Auxiliary channel on10b = Error Indicator or Not Used , depending on application11b = N...";
CM_ SG_ 2561081086 AuxiliaryIO53 "Auxiliary I/O #53: Identifies the current status of auxiliary input/output functions that are configured uniquely per application.00b = Auxiliary channel off01b = Auxiliary channel on10b = Error Indicator or Not Used , depending on application11b = N...";
CM_ SG_ 2561081086 AuxiliaryIO54 "Auxiliary I/O #54: Identifies the current status of auxiliary input/output functions that are configured uniquely per application.00b = Auxiliary channel off01b = Auxiliary channel on10b = Error Indicator or Not Used , depending on application11b = N...";
CM_ SG_ 2561081086 AuxiliaryIO55 "Auxiliary I/O #55: Identifies the current status of auxiliary input/output functions that are configured uniquely per application.00b = Auxiliary channel off01b = Auxiliary channel on10b = Error Indicator or Not Used , depending on application11b = N...";
CM_ SG_ 2561081086 AuxiliaryIO56 "Auxiliary I/O #56: Identifies the current status of auxiliary input/output functions that are configured uniquely per application.00b = Auxiliary channel off01b = Auxiliary channel on10b = Error Indicator or Not Used , depending on application11b = N...";
CM_ SG_ 2561081086 AuxiliaryIO57 "Auxiliary I/O #57: Identifies the current status of auxiliary input/output functions that are configured uniquely per application.00b = Auxiliary channel off01b = Auxiliary channel on10b = Error Indicator or Not Used , depending on application11b = N...";
CM_ SG_ 2561081086 AuxiliaryIO58 "Auxiliary I/O #58: Identifies the current status of auxiliary input/output functions that are configured uniquely per application.00b = Auxiliary channel off01b = Auxiliary channel on10b = Error Indicator or Not Used , depending on application11b = N...";
CM_ SG_ 2561081086 AuxiliaryIO59 "Auxiliary I/O #59: Identifies the current status of auxiliary input/output functions that are configured uniquely per application.00b = Auxiliary channel off01b = Auxiliary channel on10b = Error Indicator or Not Used , depending on application11b = N...";
CM_ SG_ 2561081086 AuxiliaryIO60 "Auxiliary I/O #60: Identifies the current status of auxiliary input/output functions that are configured uniquely per application.00b = Auxiliary channel off01b = Auxiliary channel on10b = Error Indicator or Not Used , depending on application11b = N...";
CM_ SG_ 2561081086 AuxiliaryIO61 "Auxiliary I/O #61: Identifies the current status of auxiliary input/output functions that are configured uniquely per application.00b = Auxiliary channel off01b = Auxiliary channel on10b = Error Indicator or Not Used , depending on application11b = N...";
CM_ SG_ 2561081086 AuxiliaryIO62 "Auxiliary I/O #62: Identifies the current status of auxiliary input/output functions that are configured uniquely per application.00b = Auxiliary channel off01b = Auxiliary channel on10b = Error Indicator or Not Used , depending on application11b = N...";
CM_ SG_ 2561081086 AuxiliaryIO63 "Auxiliary I/O #63: Identifies the current status of auxiliary input/output functions that are configured uniquely per application.00b = Auxiliary channel off01b = Auxiliary channel on10b = Error Indicator or Not Used , depending on application11b = N...";
CM_ SG_ 2561081086 AuxiliaryIO64 "Auxiliary I/O #64: Identifies the current status of auxiliary input/output functions that are configured uniquely per application.00b = Auxiliary channel off01b = Auxiliary channel on10b = Error Indicator or Not Used , depending on application11b = N...";
CM_ SG_ 2561081086 AuxiliaryIO65 "Auxiliary I/O #65: Identifies the current status of auxiliary input/output functions that are configured uniquely per application.00b = Auxiliary channel off01b = Auxiliary channel on10b = Error Indicator or Not Used , depending on application11b = N...";
CM_ SG_ 2561081086 AuxiliaryIO66 "Auxiliary I/O #66: Identifies the current status of auxiliary input/output functions that are configured uniquely per application.00b = Auxiliary channel off01b = Auxiliary channel on10b = Error Indicator or Not Used , depending on application11b = N...";
CM_ SG_ 2561081086 AuxiliaryIO67 "Auxiliary I/O #67: Identifies the current status of auxiliary input/output functions that are configured uniquely per application.00b = Auxiliary channel off01b = Auxiliary channel on10b = Error Indicator or Not Used , depending on application11b = N...";
CM_ SG_ 2561081086 AuxiliaryIO68 "Auxiliary I/O #68: Identifies the current status of auxiliary input/output functions that are configured uniquely per application.00b = Auxiliary channel off01b = Auxiliary channel on10b = Error Indicator or Not Used , depending on application11b = N...";
CM_ SG_ 2561081086 AuxiliaryIO69 "Auxiliary I/O #69: Identifies the current status of auxiliary input/output functions that are configured uniquely per application.00b = Auxiliary channel off01b = Auxiliary channel on10b = Error Indicator or Not Used , depending on application11b = N...";
CM_ SG_ 2561081086 AuxiliaryIO70 "Auxiliary I/O #70: Identifies the current status of auxiliary input/output functions that are configured uniquely per application.00b = Auxiliary channel off01b = Auxiliary channel on10b = Error Indicator or Not Used , depending on application11b = N...";
CM_ SG_ 2561081086 AuxiliaryIO71 "Auxiliary I/O #71: Identifies the current status of auxiliary input/output functions that are configured uniquely per application.00b = Auxiliary channel off01b = Auxiliary channel on10b = Error Indicator or Not Used , depending on application11b = N...";
CM_ SG_ 2561081086 AuxiliaryIO72 "Auxiliary I/O #72: Identifies the current status of auxiliary input/output functions that are configured uniquely per application.00b = Auxiliary channel off01b = Auxiliary channel on10b = Error Indicator or Not Used , depending on application11b = N...";
CM_ SG_ 2561081086 AuxiliaryIO73 "Auxiliary I/O #73: Identifies the current status of auxiliary input/output functions that are configured uniquely per application.00b = Auxiliary channel off01b = Auxiliary channel on10b = Error Indicator or Not Used , depending on application11b = N...";
CM_ SG_ 2561081086 AuxiliaryIO74 "Auxiliary I/O #74: Identifies the current status of auxiliary input/output functions that are configured uniquely per application.00b = Auxiliary channel off01b = Auxiliary channel on10b = Error Indicator or Not Used , depending on application11b = N...";
CM_ SG_ 2561081086 AuxiliaryIO75 "Auxiliary I/O #75: Identifies the current status of auxiliary input/output functions that are configured uniquely per application.00b = Auxiliary channel off01b = Auxiliary channel on10b = Error Indicator or Not Used , depending on application11b = N...";
CM_ SG_ 2561081086 AuxiliaryIO76 "Auxiliary I/O #76: Identifies the current status of auxiliary input/output functions that are configured uniquely per application.00b = Auxiliary channel off01b = Auxiliary channel on10b = Error Indicator or Not Used , depending on application11b = N...";
CM_ SG_ 2561081086 AuxiliaryIO77 "Auxiliary I/O #77: Identifies the current status of auxiliary input/output functions that are configured uniquely per application.00b = Auxiliary channel off01b = Auxiliary channel on10b = Error Indicator or Not Used , depending on application11b = N...";
CM_ SG_ 2561081086 AuxiliaryIO78 "Auxiliary I/O #78: Identifies the current status of auxiliary input/output functions that are configured uniquely per application.00b = Auxiliary channel off01b = Auxiliary channel on10b = Error Indicator or Not Used , depending on application11b = N...";
CM_ SG_ 2561081086 AuxiliaryIO79 "Auxiliary I/O #79: Identifies the current status of auxiliary input/output functions that are configured uniquely per application.00b = Auxiliary channel off01b = Auxiliary channel on10b = Error Indicator or Not Used , depending on application11b = N...";
CM_ SG_ 2561081086 AuxiliaryIO80 "Auxiliary I/O #80: Identifies the current status of auxiliary input/output functions that are configured uniquely per application.00b = Auxiliary channel off01b = Auxiliary channel on10b = Error Indicator or Not Used , depending on application11b = N...";
BA_DEF_ SG_  "SPN" INT 0 524287;
BA_DEF_ BO_  "VFrameFormat" ENUM  "StandardCAN","ExtendedCAN","reserved","J1939PG";
BA_DEF_DEF_  "SPN" 0;
BA_DEF_DEF_  "VFrameFormat" "J1939PG";
BA_ "SPN" SG_ 2498825982 DmpBdRsPstnRltvtRmmnddMxmm 8314;
BA_ "SPN" SG_ 2498825982 DumpBodyEjectorBladePosition 8315;
BA_ "SPN" SG_ 2498825982 DumpBodyRaiseAngle 8313;
BA_ "SPN" SG_ 2498825982 DumpBodyRollAngle 8312;
BA_ "SPN" SG_ 2499547902 CabDoorsLockActuationCommand 7727;
BA_ "SPN" SG_ 2499547902 LeftFrontWindowPositionCommand 7729;
BA_ "SPN" SG_ 2499547902 LeftRearWindowPositionCommand 7731;
BA_ "SPN" SG_ 2499547902 MirrorLeft1HeatCommand 7741;
BA_ "SPN" SG_ 2499547902 MirrorLeft1HorizontalCommand 7733;
BA_ "SPN" SG_ 2499547902 MirrorLeft1VerticalCommand 7734;
BA_ "SPN" SG_ 2499547902 MirrorLeft2HeatCommand 7743;
BA_ "SPN" SG_ 2499547902 MirrorLeft2HorizontalCommand 7737;
BA_ "SPN" SG_ 2499547902 MirrorLeft2VerticalCommand 7738;
BA_ "SPN" SG_ 2499547902 MirrorRight1HeatCommand 7742;
BA_ "SPN" SG_ 2499547902 MirrorRight1HorizontalCommand 7735;
BA_ "SPN" SG_ 2499547902 MirrorRight1VerticalCommand 7736;
BA_ "SPN" SG_ 2499547902 MirrorRight2HeatCommand 7744;
BA_ "SPN" SG_ 2499547902 MirrorRight2HorizontalCommand 7739;
BA_ "SPN" SG_ 2499547902 MirrorRight2VerticalCommand 7740;
BA_ "SPN" SG_ 2499547902 RemoteCabDoorLockRequest 7728;
BA_ "SPN" SG_ 2499547902 RightFrontWindowPositionCommand 7730;
BA_ "SPN" SG_ 2499547902 RightRearWindowPositionCommand 7732;
BA_ "SPN" SG_ 2499547902 MirrorFoldingSwitch 12317;
BA_ "SPN" SG_ 2499547902 MirrorAutoPanningEnable 12318;
BA_ "SPN" SG_ 2499548158 LeftFrontCabDoorLatchPosition 7723;
BA_ "SPN" SG_ 2499548158 LeftRearCabDoorLatchPosition 7725;
BA_ "SPN" SG_ 2499548158 RightFrontCabDoorLatchPosition 7724;
BA_ "SPN" SG_ 2499548158 RightRearCabDoorLatchPosition 7726;
BA_ "SPN" SG_ 2499548670 BatteryPotentialPowerInput3 7712;
BA_ "SPN" SG_ 2499548670 BatteryPotentialPowerInput4 7713;
BA_ "SPN" SG_ 2499548670 SLIBattery3NetCurrent 7714;
BA_ "SPN" SG_ 2499548670 SLIBattery4NetCurrent 7715;
BA_ "SPN" SG_ 2499548926 PayloadTemperature5 7707;
BA_ "SPN" SG_ 2499549182 PayloadTemperature1 7703;
BA_ "SPN" SG_ 2499549182 PayloadTemperature2 7704;
BA_ "SPN" SG_ 2499549182 PayloadTemperature3 7705;
BA_ "SPN" SG_ 2499549182 PayloadTemperature4 7706;
BA_ "SPN" SG_ 2499556094 Atttt1PttSsHtHSdDvDstStts 7322;
BA_ "SPN" SG_ 2499556094 Atttt1PttSsHtHSdDvPFMI 7321;
BA_ "SPN" SG_ 2499556094 Atttt1PttSsHtLwSdDvDstStts 7324;
BA_ "SPN" SG_ 2499556094 Atttt1PttSsHtLwSdDvPFMI 7323;
BA_ "SPN" SG_ 2499556094 Atttt1PttSsHtPwSppDstStts 7330;
BA_ "SPN" SG_ 2499556094 Atttt1PttSsHtPwSppPFMI 7329;
BA_ "SPN" SG_ 2499556094 Atttt1PttSsIptDstStts 7326;
BA_ "SPN" SG_ 2499556094 Atttt1PttSsIptPFMI 7325;
BA_ "SPN" SG_ 2499556094 Atttt1PttSsPwSppDstStts 7328;
BA_ "SPN" SG_ 2499556094 Atttt1PttSsPwSppPFMI 7327;
BA_ "SPN" SG_ 2499556350 EngnFl1InjtrMtrngRl1DsrdPrssr 7100;
BA_ "SPN" SG_ 2499556350 EngnFl1InjtrMtrngRl2DsrdPrssr 7101;
BA_ "SPN" SG_ 2499556606 EF1ItMtR1Pss1ExtddR 7096;
BA_ "SPN" SG_ 2499556606 EF1ItMtR1Pss2ExtddR 7097;
BA_ "SPN" SG_ 2499556606 EF1ItMtR2Pss1ExtddR 7098;
BA_ "SPN" SG_ 2499556606 EF1ItMtR2Pss2ExtddR 7099;
BA_ "SPN" SG_ 2499557118 EngnGssFlSpplBldVlv1Pstn 7083;
BA_ "SPN" SG_ 2499557118 EngnGssFlSpplBldVlv2Pstn 7084;
BA_ "SPN" SG_ 2499557118 EngnGssFlSpplBldVlv3Pstn 7085;
BA_ "SPN" SG_ 2499557118 EngnGssFlSpplShtffVlv1Pstn 7081;
BA_ "SPN" SG_ 2499557118 EngnGssFlSpplShtffVlv2Pstn 7082;
BA_ "SPN" SG_ 2499557118 InertGasSupplyValvePosition 7442;
BA_ "SPN" SG_ 2499557374 EngineOilMist10Concentration 7080;
BA_ "SPN" SG_ 2499557374 EngineOilMist9Concentration 7079;
BA_ "SPN" SG_ 2499557630 EngineOilMist1Concentration 7071;
BA_ "SPN" SG_ 2499557630 EngineOilMist2Concentration 7072;
BA_ "SPN" SG_ 2499557630 EngineOilMist3Concentration 7073;
BA_ "SPN" SG_ 2499557630 EngineOilMist4Concentration 7074;
BA_ "SPN" SG_ 2499557630 EngineOilMist5Concentration 7075;
BA_ "SPN" SG_ 2499557630 EngineOilMist6Concentration 7076;
BA_ "SPN" SG_ 2499557630 EngineOilMist7Concentration 7077;
BA_ "SPN" SG_ 2499557630 EngineOilMist8Concentration 7078;
BA_ "SPN" SG_ 2499557886 PlntGssFlSpplOtltPrssr 7067;
BA_ "SPN" SG_ 2499557886 PlntInrtGsSpplOtltPrssr 7068;
BA_ "SPN" SG_ 2499558142 EngnGssFlSpplPrssr2 7063;
BA_ "SPN" SG_ 2499558142 EngnGssFlSpplShtffVlv1IntkPrssr 7065;
BA_ "SPN" SG_ 2499558142 EngnGssFlSpplShtffVlv2IntkPrssr 7066;
BA_ "SPN" SG_ 2499558142 EngnGssFlSpplUntIntkPrssr 7064;
BA_ "SPN" SG_ 2499580158 EngnFl1InjtrMtrngRl1Prssr1 6589;
BA_ "SPN" SG_ 2499580158 EngnFl1InjtrMtrngRl1Prssr2 6590;
BA_ "SPN" SG_ 2499580158 EngnFl1InjtrMtrngRl2Prssr1 6591;
BA_ "SPN" SG_ 2499580158 EngnFl1InjtrMtrngRl2Prssr2 6592;
BA_ "SPN" SG_ 2499582206 SftTpSpdLmtRmnngCntnsIntrvlDstn 6914;
BA_ "SPN" SG_ 2499582206 SftTpSpdLmtRmnngDstn 6372;
BA_ "SPN" SG_ 2499582206 SoftTopRatioLimitExceeded 6371;
BA_ "SPN" SG_ 2499582206 SoftTopSpeedLimitActive 6370;
BA_ "SPN" SG_ 2499582206 SoftTopSpeedLimitResetDistance 6373;
BA_ "SPN" SG_ 2499583486 EngnTmngAttr1PstnCmmnd 6336;
BA_ "SPN" SG_ 2499583486 EngnTmngAttr2PstnCmmnd 6337;
BA_ "SPN" SG_ 2499583742 EngineTimingActuator1 635;
BA_ "SPN" SG_ 2499583742 EngineTimingActuator2 1245;
BA_ "SPN" SG_ 2499583742 EngnTmngAttr1RqstdPstn 6334;
BA_ "SPN" SG_ 2499583742 EngnTmngAttr2RqstdPstn 6335;
BA_ "SPN" SG_ 2499592190 TrnsmssnClth1AttrPrnt 5944;
BA_ "SPN" SG_ 2499592190 TrnsmssnClth1ClngAttrStts 5949;
BA_ "SPN" SG_ 2499592190 TrnsmssnClth2AttrPrnt 5945;
BA_ "SPN" SG_ 2499592190 TrnsmssnClth2ClngAttrStts 5950;
BA_ "SPN" SG_ 2499592190 TrnsmssnHdrlPmpAttr1Prnt 5946;
BA_ "SPN" SG_ 2499592190 TrnsmssnHdrlPmpAttr2Prnt 6582;
BA_ "SPN" SG_ 2499592190 TrnsmssnShftAttr1Prnt 5947;
BA_ "SPN" SG_ 2499592190 TrnsmssnShftAttr2Prnt 5948;
BA_ "SPN" SG_ 2499592190 TrnsmssnShftRl1AttrStts 5951;
BA_ "SPN" SG_ 2499592190 TrnsmssnShftRl2AttrStts 5952;
BA_ "SPN" SG_ 2499592190 TrnsmssnShftRl3AttrStts 5953;
BA_ "SPN" SG_ 2499592190 TrnsmssnShftRl4AttrStts 5954;
BA_ "SPN" SG_ 2499592190 TrnsmssnShftRl5AttrStts 5955;
BA_ "SPN" SG_ 2499592190 TrnsmssnShftRl6AttrStts 5956;
BA_ "SPN" SG_ 2499592446 TransmissionShiftRail1Position 4218;
BA_ "SPN" SG_ 2499592446 TransmissionShiftRail2Position 4219;
BA_ "SPN" SG_ 2499592446 TransmissionShiftRail3Position 4220;
BA_ "SPN" SG_ 2499592446 TransmissionShiftRail4Position 5941;
BA_ "SPN" SG_ 2499592446 TransmissionShiftRail5Position 5942;
BA_ "SPN" SG_ 2499592446 TransmissionShiftRail6Position 5943;
BA_ "SPN" SG_ 2499604222 BladeElevationDeviationLeft 5410;
BA_ "SPN" SG_ 2499604222 BladeElevationDeviationRight 5411;
BA_ "SPN" SG_ 2499604222 BldRfrnElvtnOffstLft 5412;
BA_ "SPN" SG_ 2499604222 BldRfrnElvtnOffstRght 5413;
BA_ "SPN" SG_ 2499604478 EExstGsRt1OttAstPssHRst 5431;
BA_ "SPN" SG_ 2499604478 EFDvPssHRstExtddR 7469;
BA_ "SPN" SG_ 2499604478 EngnExhstGsRrltn1IntkAsltPrssr 5430;
BA_ "SPN" SG_ 2499604478 EngnOlPrssrHghRsltnExtnddRng 7468;
BA_ "SPN" SG_ 2499607550 EExstMdB1FwBVvAttPst 5277;
BA_ "SPN" SG_ 2499607550 EExstMdB2FwBVvAttPst 5279;
BA_ "SPN" SG_ 2499614462 DrvrOpntClssftnSstmStts 4963;
BA_ "SPN" SG_ 2499614462 OpntClssftnSstm10Stts 4972;
BA_ "SPN" SG_ 2499614462 OpntClssftnSstm3Stts 4965;
BA_ "SPN" SG_ 2499614462 OpntClssftnSstm4Stts 4966;
BA_ "SPN" SG_ 2499614462 OpntClssftnSstm5Stts 4967;
BA_ "SPN" SG_ 2499614462 OpntClssftnSstm6Stts 4968;
BA_ "SPN" SG_ 2499614462 OpntClssftnSstm7Stts 4969;
BA_ "SPN" SG_ 2499614462 OpntClssftnSstm8Stts 4970;
BA_ "SPN" SG_ 2499614462 OpntClssftnSstm9Stts 4971;
BA_ "SPN" SG_ 2499614462 PssngrOpntClssftnSstmStts 4964;
BA_ "SPN" SG_ 2499614718 Beltlock10Status 4961;
BA_ "SPN" SG_ 2499614718 Beltlock3Status 4954;
BA_ "SPN" SG_ 2499614718 Beltlock4Status 4955;
BA_ "SPN" SG_ 2499614718 Beltlock5Status 4956;
BA_ "SPN" SG_ 2499614718 Beltlock6Status 4957;
BA_ "SPN" SG_ 2499614718 Beltlock7Status 4958;
BA_ "SPN" SG_ 2499614718 Beltlock8Status 4959;
BA_ "SPN" SG_ 2499614718 Beltlock9Status 4960;
BA_ "SPN" SG_ 2499614718 DriverBeltlockStatus 4952;
BA_ "SPN" SG_ 2499614718 PassengerBeltlockStatus 4953;
BA_ "SPN" SG_ 2499614718 PssngrArgDtvtnSwthStts 4962;
BA_ "SPN" SG_ 2499624702 Aftrtrtmnt1SCRIntkTmprtr 4360;
BA_ "SPN" SG_ 2499624702 Aftrtrtmnt1SCROtltTmprtr 4363;
BA_ "SPN" SG_ 2499624702 Atttt1SCRItTptPFMI 4361;
BA_ "SPN" SG_ 2499624702 Atttt1SCROttTptPFMI 4362;
BA_ "SPN" SG_ 2499630078 EngineExhaustTemperatureAverage 4151;
BA_ "SPN" SG_ 2499630078 EngnExhstBnk1TmprtrAvrg 4153;
BA_ "SPN" SG_ 2499630078 EngnExhstBnk2TmprtrAvrg 4152;
BA_ "SPN" SG_ 2499635454 GrossCombinationWeight 417;
BA_ "SPN" SG_ 2499635454 NetVehicleWeightChange 413;
BA_ "SPN" SG_ 2499635966 AdditionalAxleGroupLocation 5935;
BA_ "SPN" SG_ 2499635966 AxleGroupLocation 4073;
BA_ "SPN" SG_ 2499635966 AxleGroupWeight 409;
BA_ "SPN" SG_ 2499641854 EExstGsRt1CBpssAttPst 3672;
BA_ "SPN" SG_ 2550660862 ValveAssemblyLoadsensePressure 4088;
BA_ "SPN" SG_ 2550660862 ValveAssemblySupplyPressure 4089;
BA_ "SPN" SG_ 2550660862 ValveLoadSensePressure 4086;
BA_ "SPN" SG_ 2550660862 ValvePilotPressure 4087;
BA_ "SPN" SG_ 2550988542 EngineClutchEngageRequestStatus 7844;
BA_ "SPN" SG_ 2550988542 ReadyForClutchEngagementStatus 7847;
BA_ "SPN" SG_ 2550988542 AcceleratorPedal3Position 28;
BA_ "SPN" SG_ 2557214462 WSttPpDsPssCtStPtCd 9198;
BA_ "SPN" SG_ 2557214462 WSttPpStPssCtStPtCd 9197;
BA_ "SPN" SG_ 2557345534 WllStmltnPmpPlngrFrngOrdr 8870;
BA_ "SPN" SG_ 2557345534 WllStmltnPmpRdLdHghThrshld 8869;
BA_ "SPN" SG_ 2557345534 WllStmltnPmpStnPrssrHghThrshld 8865;
BA_ "SPN" SG_ 2557345534 WllStmltnPmpStnPrssrLwThrshld 8864;
BA_ "SPN" SG_ 2557345534 WSttPpCstSpdHTsd 8868;
BA_ "SPN" SG_ 2557345534 WSttPpCstSpdLwTsd 8867;
BA_ "SPN" SG_ 2557345534 WSttPpDsPssHTsd 8866;
BA_ "SPN" SG_ 2557345534 WSttPpGBxOPssHTsd 8861;
BA_ "SPN" SG_ 2557345534 WSttPpGBxOPssLwTsd 8860;
BA_ "SPN" SG_ 2557345534 WSttPpGBxOTptHTsd 8863;
BA_ "SPN" SG_ 2557345534 WSttPpGBxOTptLwTsd 8862;
BA_ "SPN" SG_ 2557673214 OlDrsMntrCnfgrtnIdntftnNmr 8191;
BA_ "SPN" SG_ 2557673214 OlDrsMntrFrrsBn1CntCmmnd 8192;
BA_ "SPN" SG_ 2557673214 OlDrsMntrFrrsBn2CntCmmnd 8193;
BA_ "SPN" SG_ 2557673214 OlDrsMntrFrrsBn3CntCmmnd 8194;
BA_ "SPN" SG_ 2557673214 OlDrsMntrFrrsBn4CntCmmnd 8195;
BA_ "SPN" SG_ 2557673214 OlDrsMntrFrrsBn5CntCmmnd 8196;
BA_ "SPN" SG_ 2557673214 OlDrsMntrFrrsBn6CntCmmnd 8197;
BA_ "SPN" SG_ 2557673214 OlDrsMntrNnFrrsBn1CntCmmnd 8198;
BA_ "SPN" SG_ 2557673214 OlDrsMntrNnFrrsBn2CntCmmnd 8199;
BA_ "SPN" SG_ 2557673214 OlDrsMntrNnFrrsBn3CntCmmnd 8200;
BA_ "SPN" SG_ 2557673214 OlDrsMntrNnFrrsBn4CntCmmnd 8201;
BA_ "SPN" SG_ 2557673214 OlDrsMntrNnFrrsBn5CntCmmnd 8202;
BA_ "SPN" SG_ 2557673214 OlDrsMntrNnFrrsBn6CntCmmnd 8203;
BA_ "SPN" SG_ 2557738750 PrplsnMtrClntFn3EnlCmmnd 8063;
BA_ "SPN" SG_ 2557738750 PrplsnMtrClntFn3PrntSpdCmmnd 8066;
BA_ "SPN" SG_ 2557738750 PrplsnMtrClntFn3PwrHld 8064;
BA_ "SPN" SG_ 2557738750 PrplsnMtrClntFn3SpdCmmnd 8065;
BA_ "SPN" SG_ 2557804286 PrplsnMtrClntFn2EnlCmmnd 8051;
BA_ "SPN" SG_ 2557804286 PrplsnMtrClntFn2PrntSpdCmmnd 8054;
BA_ "SPN" SG_ 2557804286 PrplsnMtrClntFn2PwrHld 8052;
BA_ "SPN" SG_ 2557804286 PrplsnMtrClntFn2SpdCmmnd 8053;
BA_ "SPN" SG_ 2557869822 PrplsnMtrClntFn1EnlCmmnd 8039;
BA_ "SPN" SG_ 2557869822 PrplsnMtrClntFn1PrntSpdCmmnd 8042;
BA_ "SPN" SG_ 2557869822 PrplsnMtrClntFn1PwrHld 8040;
BA_ "SPN" SG_ 2557869822 PrplsnMtrClntFn1SpdCmmnd 8041;
BA_ "SPN" SG_ 2557935358 PwrEltrnsClntFn3EnlCmmnd 8027;
BA_ "SPN" SG_ 2557935358 PwrEltrnsClntFn3PrntSpdCmmnd 8030;
BA_ "SPN" SG_ 2557935358 PwrEltrnsClntFn3PwrHld 8028;
BA_ "SPN" SG_ 2557935358 PwrEltrnsClntFn3SpdCmmnd 8029;
BA_ "SPN" SG_ 2558000894 PwrEltrnsClntFn2EnlCmmnd 8015;
BA_ "SPN" SG_ 2558000894 PwrEltrnsClntFn2PrntSpdCmmnd 8018;
BA_ "SPN" SG_ 2558000894 PwrEltrnsClntFn2PwrHld 8016;
BA_ "SPN" SG_ 2558000894 PwrEltrnsClntFn2SpdCmmnd 8017;
BA_ "SPN" SG_ 2558066430 PwrEltrnsClntFn1EnlCmmnd 8003;
BA_ "SPN" SG_ 2558066430 PwrEltrnsClntFn1PrntSpdCmmnd 8006;
BA_ "SPN" SG_ 2558066430 PwrEltrnsClntFn1PwrHld 8004;
BA_ "SPN" SG_ 2558066430 PwrEltrnsClntFn1SpdCmmnd 8005;
BA_ "SPN" SG_ 2558131966 PropulsionMotorOilPumpPowerHold 7992;
BA_ "SPN" SG_ 2558131966 PrplsnMtrOlPmpEnlCmmnd 7991;
BA_ "SPN" SG_ 2558131966 PrplsnMtrOlPmpPrntSpdCmmnd 7994;
BA_ "SPN" SG_ 2558131966 PrplsnMtrOlPmpSpdCmmnd 7993;
BA_ "SPN" SG_ 2558197502 PrplsnMtrClntPmpEnlCmmnd 7979;
BA_ "SPN" SG_ 2558197502 PrplsnMtrClntPmpPrntSpdCmmnd 7982;
BA_ "SPN" SG_ 2558197502 PrplsnMtrClntPmpPwrHld 7980;
BA_ "SPN" SG_ 2558197502 PrplsnMtrClntPmpSpdCmmnd 7981;
BA_ "SPN" SG_ 2558263038 PwrEltrnsClntPmpEnlCmmnd 7967;
BA_ "SPN" SG_ 2558263038 PwrEltrnsClntPmpPrntSpdCmmnd 7970;
BA_ "SPN" SG_ 2558263038 PwrEltrnsClntPmpPwrHld 7968;
BA_ "SPN" SG_ 2558263038 PwrEltrnsClntPmpSpdCmmnd 7969;
BA_ "SPN" SG_ 2558394110 EltrfdAssrMtrEnlCmmnd 7943;
BA_ "SPN" SG_ 2558394110 EltrfdAssrMtrPrntSpdCmmnd 7946;
BA_ "SPN" SG_ 2558394110 EltrfdAssrMtrPwrHld 7944;
BA_ "SPN" SG_ 2558394110 EltrfdAssrMtrSpdCmmnd 7945;
BA_ "SPN" SG_ 2558394110 ElectrifiedAccessoryMotor1 8292;
BA_ "SPN" SG_ 2558394110 ElectrifiedAccessoryMotor2 8293;
BA_ "SPN" SG_ 2558394110 ElectrifiedAccessoryMotor3 8294;
BA_ "SPN" SG_ 2558394110 ElectrifiedAccessoryMotor4 8295;
BA_ "SPN" SG_ 2558394110 ElectrifiedAccessoryMotor5 8296;
BA_ "SPN" SG_ 2558394110 ElectrifiedAccessoryMotor6 8297;
BA_ "SPN" SG_ 2558394110 ElectrifiedAccessoryMotor7 8298;
BA_ "SPN" SG_ 2558394110 ElectrifiedAccessoryMotor8 8299;
BA_ "SPN" SG_ 2558394110 ElectrifiedAccessoryMotor9 8300;
BA_ "SPN" SG_ 2558394110 ElectrifiedAccessoryMotor10 8301;
BA_ "SPN" SG_ 2558394110 ElectrifiedAccessoryMotor11 8302;
BA_ "SPN" SG_ 2558394110 ElectrifiedAccessoryMotor12 8303;
BA_ "SPN" SG_ 2558394110 ElectrifiedAccessoryMotor13 8304;
BA_ "SPN" SG_ 2558394110 ElectrifiedAccessoryMotor14 8305;
BA_ "SPN" SG_ 2558394110 ElectrifiedAccessoryMotor15 8306;
BA_ "SPN" SG_ 2558459646 RqstdEngnSpdAlrtnRtLmt 7760;
BA_ "SPN" SG_ 2558459646 RqstdEngnSpdDlrtnRtLmt 7761;
BA_ "SPN" SG_ 2558525182 NumberofTireSensors 7583;
BA_ "SPN" SG_ 2558525182 TireLocation 7585;
BA_ "SPN" SG_ 2558525182 TireNumber 7584;
BA_ "SPN" SG_ 2558525182 TireSensorIdentificationNumber 7586;
BA_ "SPN" SG_ 2558590718 ExtrnlEnrgSrCnntnDmnd 7890;
BA_ "SPN" SG_ 2558590718 HrdSstmPrplsnDslRqst 7558;
BA_ "SPN" SG_ 2558590718 HrdSstmPrttnOvrrdRqst 7557;
BA_ "SPN" SG_ 2558590718 HrdSstmRgnrtvBrkngDslRqst 7559;
BA_ "SPN" SG_ 2558590718 HybridPropulsionModeRequest 7889;
BA_ "SPN" SG_ 2558590718 HybridSystemShutdownCommand 7560;
BA_ "SPN" SG_ 2558590718 OperatorVehicleModeRequest 7888;
BA_ "SPN" SG_ 2558590718 StrdEnrgSrChrgDshrgRtRqst 7891;
BA_ "SPN" SG_ 2558590718 StrdEnrgSrStPntRqst 7892;
BA_ "SPN" SG_ 2558590718 HVESChargeConsent 10148;
BA_ "SPN" SG_ 2558590718 HrdPrplsnMdRqstdMxmmSpd 9706;
BA_ "SPN" SG_ 2558590718 HrdPrplsnMdRqstdDstn 9707;
BA_ "SPN" SG_ 2558656254 AftrtrtmntDslExhstFldDsrRdStts 8149;
BA_ "SPN" SG_ 2558656254 AftrtrtmntSstmEnlStts 7851;
BA_ "SPN" SG_ 2558656254 AftrtrtmntThrmlMngmntInhtRqst 7331;
BA_ "SPN" SG_ 2558656254 RqsttPrmtDEFHdrlStffnssChk 7515;
BA_ "SPN" SG_ 2558656254 RqsttPrmtSCRDsngTstInjtn 7516;
BA_ "SPN" SG_ 2558721790 ColdInflationPressureSetting 6974;
BA_ "SPN" SG_ 2558721790 ExtrmUndrPrssrPrntgThrshldSttng 6976;
BA_ "SPN" SG_ 2558721790 OverTemperatureSetting 6978;
BA_ "SPN" SG_ 2558721790 OvrPrssrPrntgThrshldSttng 6977;
BA_ "SPN" SG_ 2558721790 TireLocation 6973;
BA_ "SPN" SG_ 2558721790 TireSensorEnableSetting 7587;
BA_ "SPN" SG_ 2558721790 UndrPrssrPrntgThrshldSttng 6975;
BA_ "SPN" SG_ 2558787326 PayloadCorrectionFactorCommand 6873;
BA_ "SPN" SG_ 2558787326 PldClrtnCmmnddWght 6872;
BA_ "SPN" SG_ 2558787326 PldClrtnStPntCmmnd 6871;
BA_ "SPN" SG_ 2558852862 Aftrtrtmnt1PrtltSnsrDwpnt 6784;
BA_ "SPN" SG_ 2558852862 Aftrtrtmnt1PrtltSnsrExhstTmprtr 6785;
BA_ "SPN" SG_ 2558852862 Aftrtrtmnt1PrtltSnsrExhstVlt 6829;
BA_ "SPN" SG_ 2558852862 Aftrtrtmnt1PrtltSnsrRgnrtnRqst 6783;
BA_ "SPN" SG_ 2558852862 Aftrtrtmnt1PrtltSnsrShtdwnRqst 6782;
BA_ "SPN" SG_ 2558918398 ActiveShiftConsoleRequest 8855;
BA_ "SPN" SG_ 2558918398 AftrtrtmntSstmEnlCmmnd 8148;
BA_ "SPN" SG_ 2558918398 AttttRtESpdAwdSwt 7580;
BA_ "SPN" SG_ 2558918398 ElvtdEngnSpdAllwdSwth 7579;
BA_ "SPN" SG_ 2558918398 EngineFan2RequestedPercentSpeed 6730;
BA_ "SPN" SG_ 2558918398 EngineStopStartDisableCommand 7759;
BA_ "SPN" SG_ 2558918398 EngnIdlMngmntPndngEvntOvrrd 9374;
BA_ "SPN" SG_ 2558918398 HtExhngrDrsPrgFrSwth 7034;
BA_ "SPN" SG_ 2558918398 HtExhngrDrsPrgInhtSwth 7033;
BA_ "SPN" SG_ 2558918398 PerformanceBiasSelection 6874;
BA_ "SPN" SG_ 2558918398 PrdtvCrsCntrlDtvtnRqst 7437;
BA_ "SPN" SG_ 2558918398 PrdtvCrsCntrlEnlSwth 7436;
BA_ "SPN" SG_ 2558918398 PrdtvCrsCntrlMxmmNgtvOffst 7439;
BA_ "SPN" SG_ 2558918398 PrdtvCrsCntrlMxmmPstvOffst 7438;
BA_ "SPN" SG_ 2558918398 SCROprtrIndmntOvrrdSwth 6881;
BA_ "SPN" SG_ 2558918398 TrnsmssnAtNtrlMnlRtrnEnlSwth 7694;
BA_ "SPN" SG_ 2558918398 VehicleHoodSwitch 5575;
BA_ "SPN" SG_ 2558983934 SwitchedPowerOutput10Command 5994;
BA_ "SPN" SG_ 2558983934 SwitchedPowerOutput11Command 5993;
BA_ "SPN" SG_ 2558983934 SwitchedPowerOutput12Command 5992;
BA_ "SPN" SG_ 2558983934 SwitchedPowerOutput13Command 5999;
BA_ "SPN" SG_ 2558983934 SwitchedPowerOutput14Command 5998;
BA_ "SPN" SG_ 2558983934 SwitchedPowerOutput15Command 5997;
BA_ "SPN" SG_ 2558983934 SwitchedPowerOutput16Command 5996;
BA_ "SPN" SG_ 2558983934 SwitchedPowerOutput17Command 6003;
BA_ "SPN" SG_ 2558983934 SwitchedPowerOutput18Command 6002;
BA_ "SPN" SG_ 2558983934 SwitchedPowerOutput19Command 6001;
BA_ "SPN" SG_ 2558983934 SwitchedPowerOutput1Command 5987;
BA_ "SPN" SG_ 2558983934 SwitchedPowerOutput20Command 6000;
BA_ "SPN" SG_ 2558983934 SwitchedPowerOutput21Command 6007;
BA_ "SPN" SG_ 2558983934 SwitchedPowerOutput22Command 6006;
BA_ "SPN" SG_ 2558983934 SwitchedPowerOutput23Command 6005;
BA_ "SPN" SG_ 2558983934 SwitchedPowerOutput24Command 6004;
BA_ "SPN" SG_ 2558983934 SwitchedPowerOutput25Command 6011;
BA_ "SPN" SG_ 2558983934 SwitchedPowerOutput26Command 6010;
BA_ "SPN" SG_ 2558983934 SwitchedPowerOutput27Command 6009;
BA_ "SPN" SG_ 2558983934 SwitchedPowerOutput28Command 6008;
BA_ "SPN" SG_ 2558983934 SwitchedPowerOutput29Command 6015;
BA_ "SPN" SG_ 2558983934 SwitchedPowerOutput2Command 5986;
BA_ "SPN" SG_ 2558983934 SwitchedPowerOutput30Command 6014;
BA_ "SPN" SG_ 2558983934 SwitchedPowerOutput31Command 6013;
BA_ "SPN" SG_ 2558983934 SwitchedPowerOutput32Command 6012;
BA_ "SPN" SG_ 2558983934 SwitchedPowerOutput3Command 5985;
BA_ "SPN" SG_ 2558983934 SwitchedPowerOutput4Command 5984;
BA_ "SPN" SG_ 2558983934 SwitchedPowerOutput5Command 5991;
BA_ "SPN" SG_ 2558983934 SwitchedPowerOutput6Command 5990;
BA_ "SPN" SG_ 2558983934 SwitchedPowerOutput7Command 5989;
BA_ "SPN" SG_ 2558983934 SwitchedPowerOutput8Command 5988;
BA_ "SPN" SG_ 2558983934 SwitchedPowerOutput9Command 5995;
BA_ "SPN" SG_ 2559049470 DesiredEngineFuelingState 5793;
BA_ "SPN" SG_ 2559049470 EngineFuelingDesiredReason 7789;
BA_ "SPN" SG_ 2559049470 EngineFuelingNotDesiredReason 7855;
BA_ "SPN" SG_ 2559049470 EngineGaseousFuelUsageInhibited 6833;
BA_ "SPN" SG_ 2559049470 EngineShutdownCommand 8614;
BA_ "SPN" SG_ 2559049470 EngnGssFlSpplDsrdPrssr 6715;
BA_ "SPN" SG_ 2559049470 EngnPrttnDrtOvrrdCmmnd 9173;
BA_ "SPN" SG_ 2559049470 RequestedFuelType 6317;
BA_ "SPN" SG_ 2559049470 TrnsmssnIdlGvrnrFlngInht 7829;
BA_ "SPN" SG_ 2559115006 RadioBeaconDirection 5755;
BA_ "SPN" SG_ 2559115006 TransmitterID2 5756;
BA_ "SPN" SG_ 2559115006 UnqBnMssgIdntfrNmr 5754;
BA_ "SPN" SG_ 2559115006 WirelessSignalStrength2 5757;
BA_ "SPN" SG_ 2559573758 CtLvEPttStdwOvdCd 5565;
BA_ "SPN" SG_ 2559639294 SupplementalFanDirectionCommand 5553;
BA_ "SPN" SG_ 2559639294 SupplementalFanEnableCommand 5552;
BA_ "SPN" SG_ 2559639294 SupplementalFanPowerHold 5555;
BA_ "SPN" SG_ 2559639294 SupplementalFanSpeedCommand 5554;
BA_ "SPN" SG_ 2559704830 LrtnOprtnMdStCmmnd 5512;
BA_ "SPN" SG_ 2559704830 LubricationCycleModeLockCommand 5510;
BA_ "SPN" SG_ 2559704830 LubricationCycleSetCommand 5511;
BA_ "SPN" SG_ 2559704830 LubricationPumpEnableCommand 5513;
BA_ "SPN" SG_ 2559704830 LubricationTimingCycleCommand 5514;
BA_ "SPN" SG_ 2559770366 DiagnosticStatusofHCDoser 5508;
BA_ "SPN" SG_ 2559770366 HCDoserInjectingStatus 5507;
BA_ "SPN" SG_ 2559770366 HCDoserStatus 5506;
BA_ "SPN" SG_ 2559770366 HydrocarbonDoserPurgingRequired 5509;
BA_ "SPN" SG_ 2559770366 RequestedFuelMassRate 5505;
BA_ "SPN" SG_ 2559770366 Aftertreatment1DPFHydrocarbon 10155;
BA_ "SPN" SG_ 2559901438 Atttt1DsPttFtStMCtOst 5495;
BA_ "SPN" SG_ 2559901438 Atttt1DsPttFtStStddDvtCtOst 5496;
BA_ "SPN" SG_ 2559966974 Atttt2DsPttFtStMCtOst 5497;
BA_ "SPN" SG_ 2559966974 Atttt2DsPttFtStStddDvtCtOst 5498;
BA_ "SPN" SG_ 2560032510 LwVltgDsnntDsrdOprtngMd 5149;
BA_ "SPN" SG_ 2560098046 CabNoiseControlStatus 5059;
BA_ "SPN" SG_ 2560098046 CabNoiseControlTuningStatus 5060;
BA_ "SPN" SG_ 2560163582 CabNoiseControlCommand 5057;
BA_ "SPN" SG_ 2560163582 CabNoiseControlTuningCommand 5058;
BA_ "SPN" SG_ 2560360190 DataDictionaryManufacturerCode 4180;
BA_ "SPN" SG_ 2560360190 DataDictionaryMethod 4181;
BA_ "SPN" SG_ 2560425726 AuxiliaryIOChannel15 4170;
BA_ "SPN" SG_ 2560425726 AuxiliaryIOChannel16 4169;
BA_ "SPN" SG_ 2560425726 AuxiliaryIOChannel17 4168;
BA_ "SPN" SG_ 2560425726 AuxiliaryIOChannel18 4167;
BA_ "SPN" SG_ 2560425726 AuxiliaryIOChannel19 4174;
BA_ "SPN" SG_ 2560425726 AuxiliaryIOChannel20 4173;
BA_ "SPN" SG_ 2560425726 AuxiliaryIOChannel21 4172;
BA_ "SPN" SG_ 2560425726 AuxiliaryIOChannel22 4171;
BA_ "SPN" SG_ 2560491262 AuxiliaryIOChannel10 4159;
BA_ "SPN" SG_ 2560491262 AuxiliaryIOChannel11 4166;
BA_ "SPN" SG_ 2560491262 AuxiliaryIOChannel12 4165;
BA_ "SPN" SG_ 2560491262 AuxiliaryIOChannel13 4164;
BA_ "SPN" SG_ 2560491262 AuxiliaryIOChannel14 4163;
BA_ "SPN" SG_ 2560491262 AuxiliaryIOChannel7 4162;
BA_ "SPN" SG_ 2560491262 AuxiliaryIOChannel8 4161;
BA_ "SPN" SG_ 2560491262 AuxiliaryIOChannel9 4160;
BA_ "SPN" SG_ 2561015550 AuxiliaryIO100 3923;
BA_ "SPN" SG_ 2561015550 AuxiliaryIO101 3924;
BA_ "SPN" SG_ 2561015550 AuxiliaryIO102 3925;
BA_ "SPN" SG_ 2561015550 AuxiliaryIO103 3926;
BA_ "SPN" SG_ 2561015550 AuxiliaryIO104 3927;
BA_ "SPN" SG_ 2561015550 AuxiliaryIO105 3928;
BA_ "SPN" SG_ 2561015550 AuxiliaryIO106 3929;
BA_ "SPN" SG_ 2561015550 AuxiliaryIO107 3930;
BA_ "SPN" SG_ 2561015550 AuxiliaryIO108 3931;
BA_ "SPN" SG_ 2561015550 AuxiliaryIO109 3932;
BA_ "SPN" SG_ 2561015550 AuxiliaryIO110 3933;
BA_ "SPN" SG_ 2561015550 AuxiliaryIO111 3934;
BA_ "SPN" SG_ 2561015550 AuxiliaryIO112 3935;
BA_ "SPN" SG_ 2561015550 AuxiliaryIO81 3904;
BA_ "SPN" SG_ 2561015550 AuxiliaryIO82 3905;
BA_ "SPN" SG_ 2561015550 AuxiliaryIO83 3906;
BA_ "SPN" SG_ 2561015550 AuxiliaryIO84 3907;
BA_ "SPN" SG_ 2561015550 AuxiliaryIO85 3908;
BA_ "SPN" SG_ 2561015550 AuxiliaryIO86 3909;
BA_ "SPN" SG_ 2561015550 AuxiliaryIO87 3910;
BA_ "SPN" SG_ 2561015550 AuxiliaryIO88 3911;
BA_ "SPN" SG_ 2561015550 AuxiliaryIO89 3912;
BA_ "SPN" SG_ 2561015550 AuxiliaryIO90 3913;
BA_ "SPN" SG_ 2561015550 AuxiliaryIO91 3914;
BA_ "SPN" SG_ 2561015550 AuxiliaryIO92 3915;
BA_ "SPN" SG_ 2561015550 AuxiliaryIO93 3916;
BA_ "SPN" SG_ 2561015550 AuxiliaryIO94 3917;
BA_ "SPN" SG_ 2561015550 AuxiliaryIO95 3918;
BA_ "SPN" SG_ 2561015550 AuxiliaryIO96 3919;
BA_ "SPN" SG_ 2561015550 AuxiliaryIO97 3920;
BA_ "SPN" SG_ 2561015550 AuxiliaryIO98 3921;
BA_ "SPN" SG_ 2561015550 AuxiliaryIO99 3922;
BA_ "SPN" SG_ 2561081086 AuxiliaryIO49 3872;
BA_ "SPN" SG_ 2561081086 AuxiliaryIO50 3873;
BA_ "SPN" SG_ 2561081086 AuxiliaryIO51 3874;
BA_ "SPN" SG_ 2561081086 AuxiliaryIO52 3875;
BA_ "SPN" SG_ 2561081086 AuxiliaryIO53 3876;
BA_ "SPN" SG_ 2561081086 AuxiliaryIO54 3877;
BA_ "SPN" SG_ 2561081086 AuxiliaryIO55 3878;
BA_ "SPN" SG_ 2561081086 AuxiliaryIO56 3879;
BA_ "SPN" SG_ 2561081086 AuxiliaryIO57 3880;
BA_ "SPN" SG_ 2561081086 AuxiliaryIO58 3881;
BA_ "SPN" SG_ 2561081086 AuxiliaryIO59 3882;
BA_ "SPN" SG_ 2561081086 AuxiliaryIO60 3883;
BA_ "SPN" SG_ 2561081086 AuxiliaryIO61 3884;
BA_ "SPN" SG_ 2561081086 AuxiliaryIO62 3885;
BA_ "SPN" SG_ 2561081086 AuxiliaryIO63 3886;
BA_ "SPN" SG_ 2561081086 AuxiliaryIO64 3887;
BA_ "SPN" SG_ 2561081086 AuxiliaryIO65 3888;
BA_ "SPN" SG_ 2561081086 AuxiliaryIO66 3889;
BA_ "SPN" SG_ 2561081086 AuxiliaryIO67 3890;
BA_ "SPN" SG_ 2561081086 AuxiliaryIO68 3891;
BA_ "SPN" SG_ 2561081086 AuxiliaryIO69 3892;
BA_ "SPN" SG_ 2561081086 AuxiliaryIO70 3893;
BA_ "SPN" SG_ 2561081086 AuxiliaryIO71 3894;
BA_ "SPN" SG_ 2561081086 AuxiliaryIO72 3895;
BA_ "SPN" SG_ 2561081086 AuxiliaryIO73 3896;
BA_ "SPN" SG_ 2561081086 AuxiliaryIO74 3897;
BA_ "SPN" SG_ 2561081086 AuxiliaryIO75 3898;
BA_ "SPN" SG_ 2561081086 AuxiliaryIO76 3899;
BA_ "SPN" SG_ 2561081086 AuxiliaryIO77 3900;
BA_ "SPN" SG_ 2561081086 AuxiliaryIO78 3901;
BA_ "SPN" SG_ 2561081086 AuxiliaryIO79 3902;
BA_ "SPN" SG_ 2561081086 AuxiliaryIO80 3903;
